VERSION ""

NS_ :

BS_:

BU_: AMP ETC GW ICM IVI NVS PDC TBOX VSP WCM

BO_ 801 VCU_alertMatrix0: 8 GW
 SG_ vcu_w000_accelPedalMismatch : 0|1@1+ (1,0) [0|1] ""  TBOX
 SG_ vcu_f000_accelPedalMismatch : 1|1@1+ (1,0) [0|1] ""  TBOX
 SG_ vcu_w001_ptOverTemp : 2|1@1+ (1,0) [0|1] ""  TBOX
 SG_ vcu_f001_ptOverTemp : 3|1@1+ (1,0) [0|1] ""  TBOX
 SG_ vcu_w002_vacuumSensorError : 4|1@1+ (1,0) [0|1] ""  TBOX
 SG_ vcu_f002_vacuumSensorError : 5|1@1+ (1,0) [0|1] ""  TBOX
 SG_ vcu_w003_accelPedalOutRange : 6|1@1+ (1,0) [0|1] ""  TBOX
 SG_ vcu_f003_accelPedalOutRange : 7|1@1+ (1,0) [0|1] ""  TBOX
 SG_ vcu_w004_waterPumpError : 8|1@1+ (1,0) [0|1] ""  TBOX
 SG_ vcu_f004_waterPumpError : 9|1@1+ (1,0) [0|1] ""  TBOX
 SG_ vcu_w009_limpMode : 18|1@1+ (1,0) [0|1] ""  TBOX
 SG_ vcu_f009_limpMode : 19|1@1+ (1,0) [0|1] ""  IVI,TBOX
 SG_ vcu_w010_gpoMode : 20|1@1+ (1,0) [0|1] ""  TBOX
 SG_ vcu_f010_gpoMode : 21|1@1+ (1,0) [0|1] ""  TBOX
 SG_ vcu_w011_hardFault : 22|1@1+ (1,0) [0|1] ""  TBOX
 SG_ vcu_f011_hardFault : 23|1@1+ (1,0) [0|1] ""  TBOX
 SG_ vcu_w012_bmsMia : 24|1@1+ (1,0) [0|1] ""  TBOX
 SG_ vcu_f012_bmsMia : 25|1@1+ (1,0) [0|1] ""  TBOX
 SG_ vcu_w013_mcuf0Mia : 26|1@1+ (1,0) [0|1] ""  TBOX
 SG_ vcu_f013_mcuf0Mia : 27|1@1+ (1,0) [0|1] ""  TBOX
 SG_ vcu_w014_mcur0Mia : 28|1@1+ (1,0) [0|1] ""  TBOX
 SG_ vcu_f014_mcur0Mia : 29|1@1+ (1,0) [0|1] ""  TBOX
 SG_ vcu_w015_mcuf1Mia : 30|1@1+ (1,0) [0|1] ""  TBOX
 SG_ vcu_f015_mcuf1Mia : 31|1@1+ (1,0) [0|1] ""  TBOX
 SG_ vcu_w016_mcur1Mia : 32|1@1+ (1,0) [0|1] ""  TBOX
 SG_ vcu_f016_mcur1Mia : 33|1@1+ (1,0) [0|1] ""  TBOX
 SG_ vcu_w017_gcuMia : 34|1@1+ (1,0) [0|1] ""  TBOX
 SG_ vcu_f017_gcuMia : 35|1@1+ (1,0) [0|1] ""  TBOX
 SG_ vcu_w018_escMia : 36|1@1+ (1,0) [0|1] ""  TBOX
 SG_ vcu_f018_escMia : 37|1@1+ (1,0) [0|1] ""  TBOX
 SG_ vcu_w019_dcdcOverTemp : 38|1@1+ (1,0) [0|1] ""  IVI,TBOX
 SG_ vcu_f019_dcdcOverTemp : 39|1@1+ (1,0) [0|1] ""  TBOX
 SG_ vcu_w020_obcOverTemp : 40|1@1+ (1,0) [0|1] ""  TBOX
 SG_ vcu_f020_obcOverTemp : 41|1@1+ (1,0) [0|1] ""  TBOX
 SG_ vcu_w021_lostCommCoolantLevel : 42|1@1+ (1,0) [0|1] ""  TBOX
 SG_ vcu_f021_lostCommCoolantLevel : 43|1@1+ (1,0) [0|1] ""  TBOX
 SG_ vcu_w022_threeWayValveFault : 44|1@1+ (1,0) [0|1] ""  TBOX
 SG_ vcu_f022_threeWayValveFault : 45|1@1+ (1,0) [0|1] ""  TBOX
 SG_ vcu_w023_fourWayValveFault : 46|1@1+ (1,0) [0|1] ""  TBOX
 SG_ vcu_f023_fourWayValveFault : 47|1@1+ (1,0) [0|1] ""  TBOX
 SG_ vcu_w024_battPtcFault : 48|1@1+ (1,0) [0|1] ""  TBOX
 SG_ vcu_f024_battPtcFault : 49|1@1+ (1,0) [0|1] ""  TBOX
 SG_ vcu_w025_acCompressorFault : 50|1@1+ (1,0) [0|1] ""  TBOX
 SG_ vcu_f025_acCompressorFault : 51|1@1+ (1,0) [0|1] ""  TBOX
 SG_ vcu_w026_agsFault : 52|1@1+ (1,0) [0|1] ""  TBOX
 SG_ vcu_f026_agsFault : 53|1@1+ (1,0) [0|1] ""  TBOX
 SG_ vcu_w027_battExvFault : 54|1@1+ (1,0) [0|1] ""  TBOX
 SG_ vcu_f027_battExvFault : 55|1@1+ (1,0) [0|1] ""  TBOX
 SG_ vcu_w028_acExvFault : 56|1@1+ (1,0) [0|1] ""  TBOX
 SG_ vcu_f028_acExvFault : 57|1@1+ (1,0) [0|1] ""  TBOX
 SG_ vcu_w029_coolantLevelLow : 58|1@1+ (1,0) [0|1] ""  TBOX
 SG_ vcu_f029_coolantLevelLow : 59|1@1+ (1,0) [0|1] ""  TBOX

BO_ 802 MCUR0_alertMatrix0: 8 GW
 SG_ mcur0_w000_overVoltage : 0|1@1+ (1,0) [0|1] ""  TBOX
 SG_ mcur0_f000_overVoltage : 1|1@1+ (1,0) [0|1] ""  TBOX
 SG_ mcur0_w001_overSpeed : 2|1@1+ (1,0) [0|1] ""  TBOX
 SG_ mcur0_f001_overSpeed : 3|1@1+ (1,0) [0|1] ""  TBOX
 SG_ mcur0_w002_overCurrentPhA : 4|1@1+ (1,0) [0|1] ""  TBOX
 SG_ mcur0_f002_overCurrentPhA : 5|1@1+ (1,0) [0|1] ""  TBOX
 SG_ mcur0_w003_overCurrentPhB : 6|1@1+ (1,0) [0|1] ""  TBOX
 SG_ mcur0_f003_overCurrentPhB : 7|1@1+ (1,0) [0|1] ""  TBOX
 SG_ mcur0_w004_overCurrentPhC : 8|1@1+ (1,0) [0|1] ""  TBOX
 SG_ mcur0_f004_overCurrentPhC : 9|1@1+ (1,0) [0|1] ""  TBOX
 SG_ mcur0_w005_canError : 10|1@1+ (1,0) [0|1] ""  TBOX
 SG_ mcur0_f005_canError : 11|1@1+ (1,0) [0|1] ""  TBOX
 SG_ mcur0_w006_noCurrentPhA : 12|1@1+ (1,0) [0|1] ""  TBOX
 SG_ mcur0_f006_noCurrentPhA : 13|1@1+ (1,0) [0|1] ""  TBOX
 SG_ mcur0_w007_noCurrentPhB : 14|1@1+ (1,0) [0|1] ""  TBOX
 SG_ mcur0_f007_noCurrentPhB : 15|1@1+ (1,0) [0|1] ""  TBOX
 SG_ mcur0_w008_noCurrentPhC : 16|1@1+ (1,0) [0|1] ""  TBOX
 SG_ mcur0_f008_noCurrentPhC : 17|1@1+ (1,0) [0|1] ""  TBOX
 SG_ mcur0_w009_taskOverrun100Hz : 18|1@1+ (1,0) [0|1] ""  TBOX
 SG_ mcur0_f009_taskOverrun100Hz : 19|1@1+ (1,0) [0|1] ""  TBOX
 SG_ mcur0_w010_taskOverrun10Hz : 20|1@1+ (1,0) [0|1] ""  TBOX
 SG_ mcur0_f010_taskOverrun10Hz : 21|1@1+ (1,0) [0|1] ""  TBOX
 SG_ mcur0_w011_PhATopDsatFaltSta : 22|1@1+ (1,0) [0|1] ""  TBOX
 SG_ mcur0_f011_PhATopDsatFaltSta : 23|1@1+ (1,0) [0|1] ""  TBOX
 SG_ mcur0_w012_PhBTopDsatFaltSta : 24|1@1+ (1,0) [0|1] ""  TBOX
 SG_ mcur0_f012_PhBTopDsatFaltSta : 25|1@1+ (1,0) [0|1] ""  TBOX
 SG_ mcur0_w013_PhCTopDsatFaltSta : 26|1@1+ (1,0) [0|1] ""  TBOX
 SG_ mcur0_f013_PhCTopDsatFaltSta : 27|1@1+ (1,0) [0|1] ""  TBOX
 SG_ mcur0_w014_PhABotDsatFaltSta : 28|1@1+ (1,0) [0|1] ""  TBOX
 SG_ mcur0_f014_PhABotDsatFaltSta : 29|1@1+ (1,0) [0|1] ""  TBOX
 SG_ mcur0_w015_PhBBotDsatFaltSta : 30|1@1+ (1,0) [0|1] ""  TBOX
 SG_ mcur0_f015_PhBBotDsatFaltSta : 31|1@1+ (1,0) [0|1] ""  TBOX
 SG_ mcur0_w016_PhCBotDsatFaltSta : 32|1@1+ (1,0) [0|1] ""  TBOX
 SG_ mcur0_f016_PhCBotDsatFaltSta : 33|1@1+ (1,0) [0|1] ""  TBOX
 SG_ mcur0_w017_underVoltage : 34|1@1+ (1,0) [0|1] ""  TBOX
 SG_ mcur0_f017_underVoltage : 35|1@1+ (1,0) [0|1] ""  TBOX
 SG_ mcur0_w018_overTemperature : 36|1@1+ (1,0) [0|1] ""  IVI,TBOX
 SG_ mcur0_f018_overTemperature : 37|1@1+ (1,0) [0|1] ""  IVI,TBOX
 SG_ mcur0_w019_underTemperature : 38|1@1+ (1,0) [0|1] ""  IVI,TBOX
 SG_ mcur0_f019_underTemperature : 39|1@1+ (1,0) [0|1] ""  TBOX
 SG_ mcur0_w020_controllerOverTemp : 40|1@1+ (1,0) [0|1] ""  IVI,TBOX
 SG_ mcur0_f020_controllerOverTemp : 41|1@1+ (1,0) [0|1] ""  TBOX
 SG_ mcur0_w021_adcOverRun : 42|1@1+ (1,0) [0|1] ""  TBOX
 SG_ mcur0_f021_adcOverRun : 43|1@1+ (1,0) [0|1] ""  TBOX
 SG_ mcur0_w022_HwOverCurrentPh : 44|1@1+ (1,0) [0|1] ""  TBOX
 SG_ mcur0_f022_HwOverCurrentPh : 45|1@1+ (1,0) [0|1] ""  TBOX
 SG_ mcur0_w023_HwOverCurrentPh : 46|1@1+ (1,0) [0|1] ""  TBOX
 SG_ mcur0_f023_HwOverCurrentPh : 47|1@1+ (1,0) [0|1] ""  TBOX
 SG_ mcur0_w024_HwOverCurrentPh : 48|1@1+ (1,0) [0|1] ""  TBOX
 SG_ mcur0_f024_HwOverCurrentPh : 49|1@1+ (1,0) [0|1] ""  TBOX
 SG_ mcur0_w025_hardwareOverVoltage : 50|1@1+ (1,0) [0|1] ""  TBOX
 SG_ mcur0_f025_hardwareOverVoltage : 51|1@1+ (1,0) [0|1] ""  TBOX
 SG_ mcur0_w026_hardwareDsatFault : 52|1@1+ (1,0) [0|1] ""  TBOX
 SG_ mcur0_f026_hardwareDsatFault : 53|1@1+ (1,0) [0|1] ""  TBOX
 SG_ mcur0_w027_curSenOffsetOutOfR : 54|1@1+ (1,0) [0|1] ""  TBOX
 SG_ mcur0_f027_curSenOffsetOutOfR : 55|1@1+ (1,0) [0|1] ""  TBOX

BO_ 803 MCUF0_alertMatrix0: 8 GW
 SG_ mcuf0_w000_overVoltage : 0|1@1+ (1,0) [0|1] ""  TBOX
 SG_ mcuf0_f000_overVoltage : 1|1@1+ (1,0) [0|1] ""  TBOX
 SG_ mcuf0_w001_overSpeed : 2|1@1+ (1,0) [0|1] ""  TBOX
 SG_ mcuf0_f001_overSpeed : 3|1@1+ (1,0) [0|1] ""  TBOX
 SG_ mcuf0_w002_overCurrentPhA : 4|1@1+ (1,0) [0|1] ""  TBOX
 SG_ mcuf0_f002_overCurrentPhA : 5|1@1+ (1,0) [0|1] ""  TBOX
 SG_ mcuf0_w003_overCurrentPhB : 6|1@1+ (1,0) [0|1] ""  TBOX
 SG_ mcuf0_f003_overCurrentPhB : 7|1@1+ (1,0) [0|1] ""  TBOX
 SG_ mcuf0_w004_overCurrentPhC : 8|1@1+ (1,0) [0|1] ""  TBOX
 SG_ mcuf0_f004_overCurrentPhC : 9|1@1+ (1,0) [0|1] ""  TBOX
 SG_ mcuf0_w005_canError : 10|1@1+ (1,0) [0|1] ""  TBOX
 SG_ mcuf0_f005_canError : 11|1@1+ (1,0) [0|1] ""  TBOX
 SG_ mcuf0_w006_noCurrentPhA : 12|1@1+ (1,0) [0|1] ""  TBOX
 SG_ mcuf0_f006_noCurrentPhA : 13|1@1+ (1,0) [0|1] ""  TBOX
 SG_ mcuf0_w007_noCurrentPhB : 14|1@1+ (1,0) [0|1] ""  TBOX
 SG_ mcuf0_f007_noCurrentPhB : 15|1@1+ (1,0) [0|1] ""  TBOX
 SG_ mcuf0_w008_noCurrentPhC : 16|1@1+ (1,0) [0|1] ""  TBOX
 SG_ mcuf0_f008_noCurrentPhC : 17|1@1+ (1,0) [0|1] ""  TBOX
 SG_ mcuf0_w009_taskOverrun100Hz : 18|1@1+ (1,0) [0|1] ""  TBOX
 SG_ mcuf0_f009_taskOverrun100Hz : 19|1@1+ (1,0) [0|1] ""  TBOX
 SG_ mcuf0_w010_taskOverrun10Hz : 20|1@1+ (1,0) [0|1] ""  TBOX
 SG_ mcuf0_f010_taskOverrun10Hz : 21|1@1+ (1,0) [0|1] ""  TBOX
 SG_ mcuf0_w011_PhATopDsatFaltSts : 22|1@1+ (1,0) [0|1] ""  TBOX
 SG_ mcuf0_f011_PhATopDsatFaltSts : 23|1@1+ (1,0) [0|1] ""  TBOX
 SG_ mcuf0_w012_PhBTopDsatFaltSts : 24|1@1+ (1,0) [0|1] ""  TBOX
 SG_ mcuf0_f012_PhBTopDsatFaltSts : 25|1@1+ (1,0) [0|1] ""  TBOX
 SG_ mcuf0_w013_PhCTopDsatFaltSts : 26|1@1+ (1,0) [0|1] ""  TBOX
 SG_ mcuf0_f013_PhCTopDsatFaltSts : 27|1@1+ (1,0) [0|1] ""  TBOX
 SG_ mcuf0_w014_PhABotDsatFaltSts : 28|1@1+ (1,0) [0|1] ""  TBOX
 SG_ mcuf0_f014_PhABotDsatFaltSts : 29|1@1+ (1,0) [0|1] ""  TBOX
 SG_ mcuf0_w015_PhBBotDsatFaltSts : 30|1@1+ (1,0) [0|1] ""  TBOX
 SG_ mcuf0_f015_PhBBotDsatFaltSts : 31|1@1+ (1,0) [0|1] ""  TBOX
 SG_ mcuf0_w016_PhCBotDsatFaltSts : 32|1@1+ (1,0) [0|1] ""  TBOX
 SG_ mcuf0_f016_PhCBotDsatFaltSts : 33|1@1+ (1,0) [0|1] ""  TBOX
 SG_ mcuf0_w017_underVoltage : 34|1@1+ (1,0) [0|1] ""  TBOX
 SG_ mcuf0_f017_underVoltage : 35|1@1+ (1,0) [0|1] ""  TBOX
 SG_ mcuf0_w018_overTemperature : 36|1@1+ (1,0) [0|1] ""  IVI,TBOX
 SG_ mcuf0_f018_overTemperature : 37|1@1+ (1,0) [0|1] ""  IVI,TBOX
 SG_ mcuf0_w019_underTemperature : 38|1@1+ (1,0) [0|1] ""  IVI,TBOX
 SG_ mcuf0_f019_underTemperature : 39|1@1+ (1,0) [0|1] ""  TBOX
 SG_ mcuf0_w020_controllerOverTemp : 40|1@1+ (1,0) [0|1] ""  IVI,TBOX
 SG_ mcuf0_f020_controllerOverTemp : 41|1@1+ (1,0) [0|1] ""  TBOX
 SG_ mcuf0_w021_adcOverRun : 42|1@1+ (1,0) [0|1] ""  TBOX
 SG_ mcuf0_f021_adcOverRun : 43|1@1+ (1,0) [0|1] ""  TBOX
 SG_ mcuf0_w022_hdOverCurrentPhA : 44|1@1+ (1,0) [0|1] ""  TBOX
 SG_ mcuf0_f022_hdOverCurrentPhA : 45|1@1+ (1,0) [0|1] ""  TBOX
 SG_ mcuf0_w023_hdOverCurrentPhB : 46|1@1+ (1,0) [0|1] ""  TBOX
 SG_ mcuf0_f023_hdOverCurrentPhB : 47|1@1+ (1,0) [0|1] ""  TBOX
 SG_ mcuf0_w024_hdOverCurrentPhC : 48|1@1+ (1,0) [0|1] ""  TBOX
 SG_ mcuf0_f024_hdOverCurrentPhC : 49|1@1+ (1,0) [0|1] ""  TBOX
 SG_ mcuf0_w025_hardwareOverVoltage : 50|1@1+ (1,0) [0|1] ""  TBOX
 SG_ mcuf0_f025_hardwareOverVoltage : 51|1@1+ (1,0) [0|1] ""  TBOX
 SG_ mcuf0_w026_hardwareDsatFault : 52|1@1+ (1,0) [0|1] ""  TBOX
 SG_ mcuf0_f026_hardwareDsatFault : 53|1@1+ (1,0) [0|1] ""  TBOX
 SG_ mcuf0_w027_curSenOffsetOutOfR : 54|1@1+ (1,0) [0|1] ""  TBOX
 SG_ mcuf0_f027_curSenOffsetOutOfR : 55|1@1+ (1,0) [0|1] ""  TBOX

BO_ 804 BMS_alertMatrix0: 8 GW
 SG_ bms_w000_packUnderVoltage : 0|1@1+ (1,0) [0|1] ""  TBOX
 SG_ bms_f000_packUnderVoltage : 1|1@1+ (1,0) [0|1] ""  TBOX
 SG_ bms_w001_packOverVoltage : 2|1@1+ (1,0) [0|1] ""  TBOX
 SG_ bms_f001_packOverVoltage : 3|1@1+ (1,0) [0|1] ""  TBOX
 SG_ bms_w002_packOverCrntDischg : 4|1@1+ (1,0) [0|1] ""  TBOX
 SG_ bms_f002_packOverCrntDischg : 5|1@1+ (1,0) [0|1] ""  TBOX
 SG_ bms_w003_packOverCrntChg : 6|1@1+ (1,0) [0|1] ""  TBOX
 SG_ bms_f003_packOverCrntChg : 7|1@1+ (1,0) [0|1] ""  TBOX
 SG_ bms_w004_cellUnderVoltage : 8|1@1+ (1,0) [0|1] ""  TBOX
 SG_ bms_f004_cellUnderVoltage : 9|1@1+ (1,0) [0|1] ""  TBOX
 SG_ bms_w005_cellOverVoltage : 10|1@1+ (1,0) [0|1] ""  TBOX
 SG_ bms_f005_cellOverVoltage : 11|1@1+ (1,0) [0|1] ""  TBOX
 SG_ bms_w006_cellUnderTemp : 12|1@1+ (1,0) [0|1] ""  IVI,TBOX
 SG_ bms_f006_cellUnderTemp : 13|1@1+ (1,0) [0|1] ""  TBOX
 SG_ bms_w007_cellOverTemp : 14|1@1+ (1,0) [0|1] ""  IVI,TBOX
 SG_ bms_f007_cellOverTemp : 15|1@1+ (1,0) [0|1] ""  TBOX
 SG_ bms_w008_contactorPosMainHSFlt : 16|1@1+ (1,0) [0|1] ""  TBOX
 SG_ bms_f008_contactorPosMainHSFlt : 17|1@1+ (1,0) [0|1] ""  TBOX
 SG_ bms_w009_contactorPosMainLSFlt : 18|1@1+ (1,0) [0|1] ""  TBOX
 SG_ bms_f009_contactorPosMainLSFlt : 19|1@1+ (1,0) [0|1] ""  TBOX
 SG_ bms_w010_contactorNegMainHSFlt : 20|1@1+ (1,0) [0|1] ""  TBOX
 SG_ bms_f010_contactorNegMainHSFlt : 21|1@1+ (1,0) [0|1] ""  TBOX
 SG_ bms_w011_contactorNegMainLSFlt : 22|1@1+ (1,0) [0|1] ""  TBOX
 SG_ bms_f011_contactorNegMainLSFlt : 23|1@1+ (1,0) [0|1] ""  TBOX
 SG_ bms_w012_contactorPrechgHSFault : 24|1@1+ (1,0) [0|1] ""  TBOX
 SG_ bms_f012_contactorPrechgHSFault : 25|1@1+ (1,0) [0|1] ""  TBOX
 SG_ bms_w013_contactorPrechgLSFault : 26|1@1+ (1,0) [0|1] ""  TBOX
 SG_ bms_f013_contactorPrechgLSFault : 27|1@1+ (1,0) [0|1] ""  TBOX
 SG_ bms_w014_acChargingRelayFault : 28|1@1+ (1,0) [0|1] ""  TBOX
 SG_ bms_f014_acChargingRelayFault : 29|1@1+ (1,0) [0|1] ""  TBOX
 SG_ bms_w015_dcChargingRelayFault : 30|1@1+ (1,0) [0|1] ""  TBOX
 SG_ bms_f015_dcChargingRelayFault : 31|1@1+ (1,0) [0|1] ""  TBOX
 SG_ bms_w016_currentSensorFailure : 32|1@1+ (1,0) [0|1] ""  TBOX
 SG_ bms_f016_currentSensorFailure : 33|1@1+ (1,0) [0|1] ""  TBOX
 SG_ bms_w017_cellImbalanceDischrg : 34|1@1+ (1,0) [0|1] ""  TBOX
 SG_ bms_f017_cellImbalanceDischrg : 35|1@1+ (1,0) [0|1] ""  TBOX
 SG_ bms_w018_prechargeFailure : 36|1@1+ (1,0) [0|1] ""  TBOX
 SG_ bms_f018_prechargeFailure : 37|1@1+ (1,0) [0|1] ""  TBOX
 SG_ bms_w019_bmuCommFailure : 38|1@1+ (1,0) [0|1] ""  TBOX
 SG_ bms_f019_bmuCommFailure : 39|1@1+ (1,0) [0|1] ""  TBOX
 SG_ bms_w020_isolationFault : 40|1@1+ (1,0) [0|1] ""  TBOX
 SG_ bms_f020_isolationFault : 41|1@1+ (1,0) [0|1] ""  IVI,TBOX
 SG_ bms_w021_coolantInletOverTemp : 42|1@1+ (1,0) [0|1] ""  TBOX
 SG_ bms_f021_coolantInletOverTemp : 43|1@1+ (1,0) [0|1] ""  TBOX
 SG_ bms_w022_coolantOutletOverTemp : 44|1@1+ (1,0) [0|1] ""  TBOX
 SG_ bms_f022_coolantOutletOverTemp : 45|1@1+ (1,0) [0|1] ""  TBOX
 SG_ bms_w023_prechargeTimeout : 46|1@1+ (1,0) [0|1] ""  TBOX
 SG_ bms_f023_prechargeTimeout : 47|1@1+ (1,0) [0|1] ""  TBOX
 SG_ bms_w024_powerDeratingSoc : 48|1@1+ (1,0) [0|1] ""  TBOX
 SG_ bms_f024_powerDeratingSoc : 49|1@1+ (1,0) [0|1] ""  TBOX
 SG_ bms_w025_noPowerDeliverySoc : 50|1@1+ (1,0) [0|1] ""  TBOX
 SG_ bms_f025_noPowerDeliverySoc : 51|1@1+ (1,0) [0|1] ""  TBOX
 SG_ bms_w026_dcLSContactorFail : 52|1@1+ (1,0) [0|1] ""  TBOX
 SG_ bms_f026_dcLSContactorFail : 53|1@1+ (1,0) [0|1] ""  TBOX
 SG_ bms_w027_hvilOpen : 54|1@1+ (1,0) [0|1] ""  TBOX
 SG_ bms_f027_hvilOpen : 55|1@1+ (1,0) [0|1] ""  TBOX
 SG_ bms_w028_lostCommsVCU : 56|1@1+ (1,0) [0|1] ""  TBOX
 SG_ bms_f028_lostCommsVCU : 57|1@1+ (1,0) [0|1] ""  TBOX
 SG_ bms_w029_lostCommsOBC : 58|1@1+ (1,0) [0|1] ""  TBOX
 SG_ bms_f029_lostCommsOBC : 59|1@1+ (1,0) [0|1] ""  TBOX
 SG_ bms_w030_batteryProtectionSoc : 60|1@1+ (1,0) [0|1] ""  TBOX
 SG_ bms_f030_batteryProtectionSoc : 61|1@1+ (1,0) [0|1] ""  TBOX
 SG_ bms_w031_cellTempImbalDischrg : 62|1@1+ (1,0) [0|1] ""  TBOX
 SG_ bms_f031_cellTempImbalDischrg : 63|1@1+ (1,0) [0|1] ""  TBOX

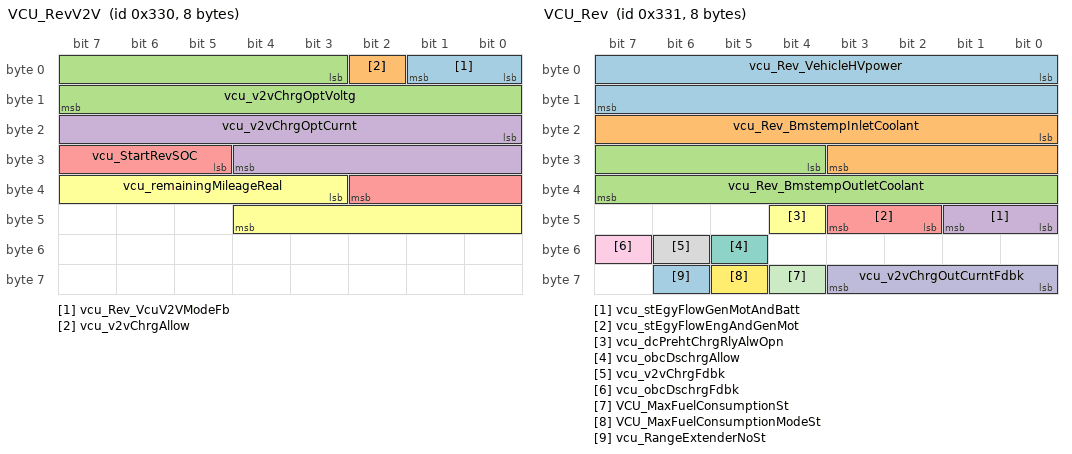
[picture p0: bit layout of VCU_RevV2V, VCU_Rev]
BO_ 816 VCU_RevV2V: 8 GW
 SG_ vcu_Rev_VcuV2VModeFb : 0|2@1+ (1,0) [0|3] "" Vector__XXX
 SG_ vcu_v2vChrgAllow : 2|1@1+ (1,0) [0|1] ""  IVI
 SG_ vcu_v2vChrgOptVoltg : 3|13@1+ (0.1,0) [0|800] "V"  IVI
 SG_ vcu_v2vChrgOptCurnt : 16|13@1+ (0.1,-400) [-400|400] "A"  IVI
 SG_ vcu_StartRevSOC : 29|6@1+ (1,20) [20|80] "%"  IVI
 SG_ vcu_remainingMileageReal : 35|10@1+ (1,0) [0|1023] "km"  IVI,TBOX

BO_ 817 VCU_Rev: 8 GW
 SG_ vcu_Rev_VehicleHVpower : 0|16@1+ (1,0) [0|20000] "W" Vector__XXX
 SG_ vcu_Rev_BmstempInletCoolant : 16|12@1+ (0.5,-40) [-40|125] "℃" Vector__XXX
 SG_ vcu_Rev_BmstempOutletCoolant : 28|12@1+ (0.5,-40) [-40|125] "℃" Vector__XXX
 SG_ vcu_stEgyFlowGenMotAndBatt : 40|2@1+ (1,0) [0|2] ""  IVI
 SG_ vcu_stEgyFlowEngAndGenMot : 42|2@1+ (1,0) [0|2] ""  IVI
 SG_ vcu_dcPrehtChrgRlyAlwOpn : 44|1@1+ (1,0) [0|1] "" Vector__XXX
 SG_ vcu_obcDschrgAllow : 53|1@1+ (1,0) [0|1] ""  IVI
 SG_ vcu_v2vChrgFdbk : 54|1@1+ (1,0) [0|1] ""  IVI
 SG_ vcu_obcDschrgFdbk : 55|1@1+ (1,0) [0|1] ""  IVI
 SG_ vcu_v2vChrgOutCurntFdbk : 56|4@1+ (1,0) [0|15] "A"  IVI
 SG_ VCU_MaxFuelConsumptionSt : 60|1@1+ (1,0) [0|1] ""  IVI
 SG_ VCU_MaxFuelConsumptionModeSt : 61|1@1+ (1,0) [0|1] ""  IVI
 SG_ vcu_RangeExtenderNoSt : 62|1@1+ (1,0) [0|1] ""  IVI

BO_ 820 BMS_alertMatrix1: 8 GW
 SG_ bms_w032_highSOC : 0|1@1+ (1,0) [0|1] ""  TBOX
 SG_ bms_f032_highSOC : 1|1@1+ (1,0) [0|1] ""  TBOX
 SG_ bms_w033_lostCommsIVTS : 2|1@1+ (1,0) [0|1] ""  TBOX
 SG_ bms_f033_lostCommsIVTS : 3|1@1+ (1,0) [0|1] ""  TBOX
 SG_ bms_w034_socStepChange : 4|1@1+ (1,0) [0|1] ""  TBOX
 SG_ bms_f034_socStepChange : 5|1@1+ (1,0) [0|1] ""  TBOX
 SG_ bms_w035_bmuNoResponse : 6|1@1+ (1,0) [0|1] ""  TBOX
 SG_ bms_f035_bmuNoResponse : 7|1@1+ (1,0) [0|1] ""  TBOX
 SG_ bms_w036_bmuHarnessBroken : 8|1@1+ (1,0) [0|1] ""  TBOX
 SG_ bms_f036_bmuHarnessBroken : 9|1@1+ (1,0) [0|1] ""  TBOX
 SG_ bms_w037_cellVoltImbalanceChrg : 10|1@1+ (1,0) [0|1] ""  TBOX
 SG_ bms_f037_cellVoltImbalanceChrg : 11|1@1+ (1,0) [0|1] ""  TBOX
 SG_ bms_w038_cellTempImbalanceChrg : 12|1@1+ (1,0) [0|1] ""  TBOX
 SG_ bms_f038_cellTempImbalanceChrg : 13|1@1+ (1,0) [0|1] ""  TBOX
 SG_ bms_w039_cellVoltSnrDisconnect : 14|1@1+ (1,0) [0|1] ""  TBOX
 SG_ bms_f039_cellVoltSnrDisconnect : 15|1@1+ (1,0) [0|1] ""  TBOX
 SG_ bms_w040_cellThermistorDiscon : 16|1@1+ (1,0) [0|1] ""  TBOX
 SG_ bms_f040_cellThermistorDiscon : 17|1@1+ (1,0) [0|1] ""  TBOX
 SG_ bms_w041_posMainConStuckOpen : 18|1@1+ (1,0) [0|1] ""  TBOX
 SG_ bms_f041_posMainConStuckOpen : 19|1@1+ (1,0) [0|1] ""  TBOX
 SG_ bms_w042_posMainContactorWelded : 20|1@1+ (1,0) [0|1] ""  TBOX
 SG_ bms_f042_posMainContactorWelded : 21|1@1+ (1,0) [0|1] ""  TBOX
 SG_ bms_w043_negMainConStuckOpen : 22|1@1+ (1,0) [0|1] ""  TBOX
 SG_ bms_f043_negMainConStuckOpen : 23|1@1+ (1,0) [0|1] ""  TBOX
 SG_ bms_w044_negMainContactorWelded : 24|1@1+ (1,0) [0|1] ""  TBOX
 SG_ bms_f044_negMainContactorWelded : 25|1@1+ (1,0) [0|1] ""  TBOX
 SG_ bms_w045_prechrgConStuckOpen : 26|1@1+ (1,0) [0|1] ""  TBOX
 SG_ bms_f045_prechrgConStuckOpen : 27|1@1+ (1,0) [0|1] ""  TBOX
 SG_ bms_w046_prechrgContactorWelded : 28|1@1+ (1,0) [0|1] ""  TBOX
 SG_ bms_f046_prechrgContactorWelded : 29|1@1+ (1,0) [0|1] ""  TBOX
 SG_ bms_w047_packOverTemp : 30|1@1+ (1,0) [0|1] ""  TBOX
 SG_ bms_f047_packOverTemp : 31|1@1+ (1,0) [0|1] ""  TBOX
 SG_ bms_w048_packUnderTemp : 32|1@1+ (1,0) [0|1] ""  TBOX
 SG_ bms_f048_packUnderTemp : 33|1@1+ (1,0) [0|1] ""  TBOX
 SG_ bms_w049_coolantInletSnrDiscon : 34|1@1+ (1,0) [0|1] ""  TBOX
 SG_ bms_f049_coolantInletSnrDiscon : 35|1@1+ (1,0) [0|1] ""  TBOX
 SG_ bms_w050_coolantOutletSnrDiscon : 36|1@1+ (1,0) [0|1] ""  TBOX
 SG_ bms_f050_coolantOutletSnrDiscon : 37|1@1+ (1,0) [0|1] ""  TBOX
 SG_ bms_w051_obcOverTemp : 38|1@1+ (1,0) [0|1] ""  IVI,TBOX
 SG_ bms_f051_obcOverTemp : 39|1@1+ (1,0) [0|1] ""  IVI,TBOX
 SG_ bms_w052_battPackShortCircuit : 40|1@1+ (1,0) [0|1] ""  TBOX
 SG_ bms_f052_battPackShortCircuit : 41|1@1+ (1,0) [0|1] ""  TBOX
 SG_ bms_w053_acChrgPortOverTemp : 42|1@1+ (1,0) [0|1] ""  TBOX
 SG_ bms_f053_acChrgPortOverTemp : 43|1@1+ (1,0) [0|1] ""  TBOX
 SG_ bms_w054_dcChrgPortOverTemp : 44|1@1+ (1,0) [0|1] ""  TBOX
 SG_ bms_f054_dcChrgPortOverTemp : 45|1@1+ (1,0) [0|1] ""  TBOX
 SG_ bms_w055_dcChrgPortTempRise : 46|1@1+ (1,0) [0|1] ""  TBOX
 SG_ bms_f055_dcChrgPortTempRise : 47|1@1+ (1,0) [0|1] ""  TBOX
 SG_ bms_w056_ivtsOverTemp : 48|1@1+ (1,0) [0|1] "" Vector__XXX
 SG_ bms_f056_ivtsOverTemp : 49|1@1+ (1,0) [0|1] "" Vector__XXX
 SG_ bms_w059_vcuStateMsgMia : 54|1@1+ (1,0) [0|1] ""  TBOX
 SG_ bms_f059_vcuStateMsgMia : 55|1@1+ (1,0) [0|1] ""  TBOX
 SG_ bms_w060_ribbonBondBroken : 56|1@1+ (1,0) [0|1] "" Vector__XXX
 SG_ bms_f060_ribbonBondBroken : 57|1@1+ (1,0) [0|1] "" Vector__XXX
 SG_ bms_w061_crashDetected : 58|1@1+ (1,0) [0|1] "" Vector__XXX
 SG_ bms_f061_crashDetected : 59|1@1+ (1,0) [0|1] ""  TBOX
 SG_ bms_w062_vcuVehicleMsgMia : 60|1@1+ (1,0) [0|1] ""  TBOX
 SG_ bms_f062_vcuVehicleMsgMia : 61|1@1+ (1,0) [0|1] ""  TBOX
 SG_ bms_w063_systemFault : 62|1@1+ (1,0) [0|1] ""  TBOX
 SG_ bms_f063_systemFault : 63|1@1+ (1,0) [0|1] ""  TBOX

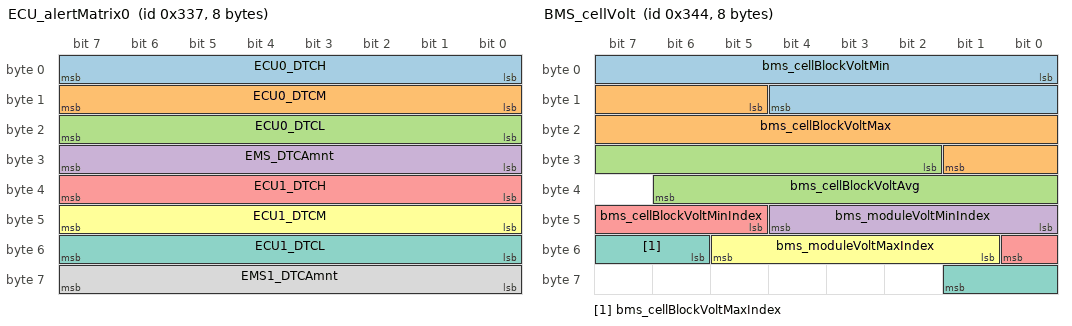
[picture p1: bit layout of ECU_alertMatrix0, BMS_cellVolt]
BO_ 823 ECU_alertMatrix0: 8 GW
 SG_ ECU0_DTCH : 0|8@1+ (1,0) [0|255] ""  TBOX
 SG_ ECU0_DTCM : 8|8@1+ (1,0) [0|255] ""  TBOX
 SG_ ECU0_DTCL : 16|8@1+ (1,0) [0|255] ""  TBOX
 SG_ EMS_DTCAmnt : 24|8@1+ (1,0) [0|255] ""  TBOX
 SG_ ECU1_DTCH : 32|8@1+ (1,0) [0|255] ""  TBOX
 SG_ ECU1_DTCM : 40|8@1+ (1,0) [0|255] ""  TBOX
 SG_ ECU1_DTCL : 48|8@1+ (1,0) [0|255] ""  TBOX
 SG_ EMS1_DTCAmnt : 56|8@1+ (1,0) [0|255] ""  TBOX

BO_ 836 BMS_cellVolt: 8 GW
 SG_ bms_cellBlockVoltMin : 0|13@1+ (0.001,0) [0|5] "V"  TBOX
 SG_ bms_cellBlockVoltMax : 13|13@1+ (0.001,0) [0|5] "V"  TBOX
 SG_ bms_cellBlockVoltAvg : 26|13@1+ (0.001,0) [0|5] "V"  TBOX
 SG_ bms_moduleVoltMinIndex : 40|5@1+ (1,0) [0|31] ""  TBOX
 SG_ bms_cellBlockVoltMinIndex : 45|4@1+ (1,0) [0|15] ""  TBOX
 SG_ bms_moduleVoltMaxIndex : 49|5@1+ (1,0) [0|31] ""  TBOX
 SG_ bms_cellBlockVoltMaxIndex : 54|4@1+ (1,0) [0|15] ""  TBOX

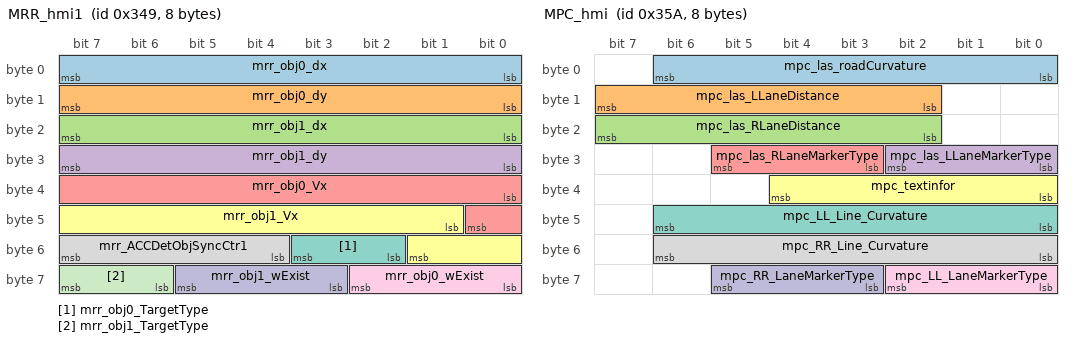
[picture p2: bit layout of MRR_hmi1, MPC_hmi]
BO_ 841 MRR_hmi1: 8 GW
 SG_ mrr_obj0_dx : 0|8@1+ (1,0) [0|250] "m"  IVI
 SG_ mrr_obj0_dy : 8|8@1+ (0.1,-12.8) [-12.8|12.7] "m"  IVI
 SG_ mrr_obj1_dx : 16|8@1+ (1,0) [0|250] "m"  IVI
 SG_ mrr_obj1_dy : 24|8@1+ (0.1,-12.8) [-12.8|12.7] "m"  IVI
 SG_ mrr_obj0_Vx : 32|9@1+ (0.1,0) [0|50] "m/s"  IVI
 SG_ mrr_obj1_Vx : 41|9@1+ (0.1,0) [0|50] "m/s"  IVI
 SG_ mrr_obj0_TargetType : 50|2@1+ (1,0) [0|3] ""  IVI
 SG_ mrr_ACCDetObjSyncCtr1 : 52|4@1+ (1,0) [0|15] ""  IVI
 SG_ mrr_obj0_wExist : 56|3@1+ (1,0) [0|7] ""  IVI
 SG_ mrr_obj1_wExist : 59|3@1+ (1,0) [0|7] ""  IVI
 SG_ mrr_obj1_TargetType : 62|2@1+ (1,0) [0|3] ""  IVI

BO_ 858 MPC_hmi: 8 GW
 SG_ mpc_las_roadCurvature : 0|7@1+ (0.0005,-0.03) [-0.03|0.03] "1/m"  IVI,TBOX
 SG_ mpc_las_LLaneDistance : 10|6@1+ (0.1,-1) [-1|5] "m"  IVI,TBOX
 SG_ mpc_las_RLaneDistance : 18|6@1+ (0.1,-5) [-5|1] "m"  IVI,TBOX
 SG_ mpc_las_LLaneMarkerType : 24|3@1+ (1,0) [0|7] ""  IVI,TBOX
 SG_ mpc_las_RLaneMarkerType : 27|3@1+ (1,0) [0|7] ""  IVI,TBOX
 SG_ mpc_textinfor : 32|5@1+ (1,0) [0|31] ""  IVI
 SG_ mpc_LL_Line_Curvature : 40|7@1+ (0.0005,-0.03) [-0.03|0.03] "1/m"  IVI,TBOX
 SG_ mpc_RR_Line_Curvature : 48|7@1+ (0.0005,-0.03) [-0.03|0.03] "1/m"  IVI,TBOX
 SG_ mpc_LL_LaneMarkerType : 56|3@1+ (1,0) [0|7] ""  IVI,TBOX
 SG_ mpc_RR_LaneMarkerType : 59|3@1+ (1,0) [0|7] ""  IVI,TBOX

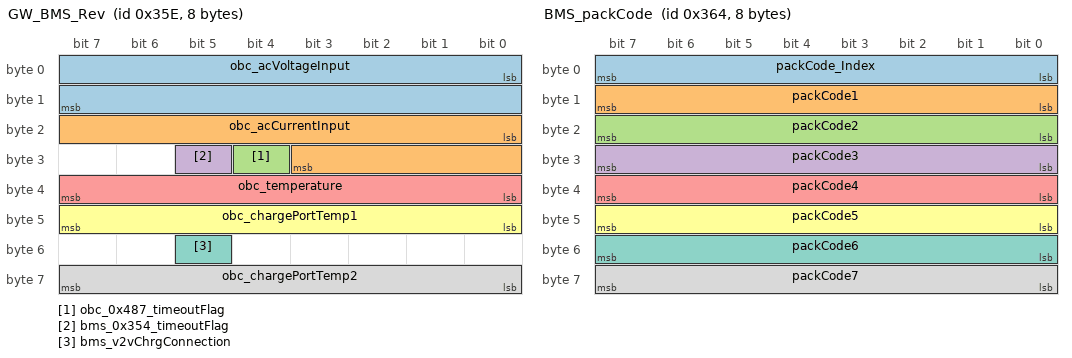
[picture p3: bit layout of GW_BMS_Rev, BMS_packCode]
BO_ 862 GW_BMS_Rev: 8 GW
 SG_ obc_acVoltageInput : 0|16@1+ (0.1,0) [0|6553.5] "V"  IVI
 SG_ obc_acCurrentInput : 16|12@1+ (0.1,0) [0|409.5] "A"  IVI
 SG_ obc_0x487_timeoutFlag : 28|1@1+ (1,0) [0|1] ""  IVI,TBOX
 SG_ bms_0x354_timeoutFlag : 29|1@1+ (1,0) [0|1] ""  IVI
 SG_ obc_temperature : 32|8@1+ (1,-40) [-40|200] "degC"  TBOX
 SG_ obc_chargePortTemp1 : 40|8@1+ (1,-40) [-40|205] "degC"  TBOX
 SG_ bms_v2vChrgConnection : 53|1@1+ (1,0) [0|1] ""  IVI
 SG_ obc_chargePortTemp2 : 56|8@1+ (1,-40) [-40|205] "degC"  TBOX

BO_ 868 BMS_packCode: 8 GW
 SG_ packCode_Index : 0|8@1+ (1,0) [0|4] ""  TBOX
 SG_ packCode1 : 8|8@1+ (1,0) [0|255] ""  TBOX
 SG_ packCode2 : 16|8@1+ (1,0) [0|255] ""  TBOX
 SG_ packCode3 : 24|8@1+ (1,0) [0|255] ""  TBOX
 SG_ packCode4 : 32|8@1+ (1,0) [0|255] ""  TBOX
 SG_ packCode5 : 40|8@1+ (1,0) [0|255] ""  TBOX
 SG_ packCode6 : 48|8@1+ (1,0) [0|255] ""  TBOX
 SG_ packCode7 : 56|8@1+ (1,0) [0|255] ""  TBOX

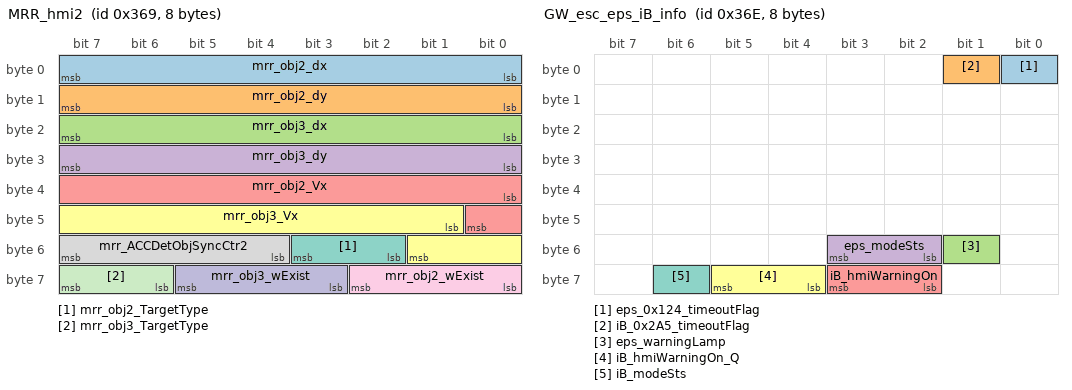
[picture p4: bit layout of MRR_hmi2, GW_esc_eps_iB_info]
BO_ 873 MRR_hmi2: 8 GW
 SG_ mrr_obj2_dx : 0|8@1+ (1,0) [0|250] "m"  IVI
 SG_ mrr_obj2_dy : 8|8@1+ (0.1,-12.8) [-12.8|12.7] "m"  IVI
 SG_ mrr_obj3_dx : 16|8@1+ (1,0) [0|250] "m"  IVI
 SG_ mrr_obj3_dy : 24|8@1+ (0.1,-12.8) [-12.8|12.7] "m"  IVI
 SG_ mrr_obj2_Vx : 32|9@1+ (0.1,0) [0|50] "m/s"  IVI
 SG_ mrr_obj3_Vx : 41|9@1+ (0.1,0) [0|50] "m/s"  IVI
 SG_ mrr_obj2_TargetType : 50|2@1+ (1,0) [0|3] ""  IVI
 SG_ mrr_ACCDetObjSyncCtr2 : 52|4@1+ (1,0) [0|15] ""  IVI
 SG_ mrr_obj2_wExist : 56|3@1+ (1,0) [0|7] ""  IVI
 SG_ mrr_obj3_wExist : 59|3@1+ (1,0) [0|7] ""  IVI
 SG_ mrr_obj3_TargetType : 62|2@1+ (1,0) [0|3] ""  IVI

BO_ 878 GW_esc_eps_iB_info: 8 GW
 SG_ eps_0x124_timeoutFlag : 0|1@1+ (1,0) [0|1] ""  IVI
 SG_ iB_0x2A5_timeoutFlag : 1|1@1+ (1,0) [0|1] ""  IVI
 SG_ eps_warningLamp : 49|1@1+ (1,0) [0|1] ""  IVI,TBOX
 SG_ eps_modeSts : 50|2@1+ (1,0) [0|3] ""  IVI
 SG_ iB_hmiWarningOn : 58|2@1+ (1,0) [0|3] ""  IVI,TBOX
 SG_ iB_hmiWarningOn_Q : 60|2@1+ (1,0) [0|3] ""  IVI,TBOX
 SG_ iB_modeSts : 62|1@1+ (1,0) [0|1] ""  IVI

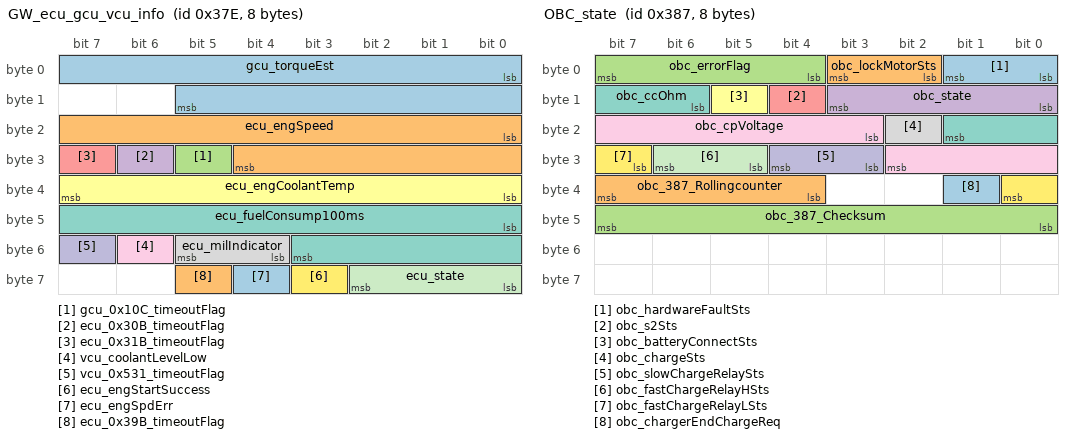
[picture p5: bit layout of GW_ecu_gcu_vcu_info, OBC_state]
BO_ 894 GW_ecu_gcu_vcu_info: 8 GW
 SG_ gcu_torqueEst : 0|14@1+ (0.1,-800) [-800|800] "Nm"  TBOX
 SG_ ecu_engSpeed : 16|13@1+ (1,0) [0|8000] "RPM"  IVI,TBOX
 SG_ gcu_0x10C_timeoutFlag : 29|1@1+ (1,0) [0|1] ""  IVI,TBOX
 SG_ ecu_0x30B_timeoutFlag : 30|1@1+ (1,0) [0|1] ""  IVI
 SG_ ecu_0x31B_timeoutFlag : 31|1@1+ (1,0) [0|1] ""  IVI
 SG_ ecu_engCoolantTemp : 32|8@1+ (0.75,-48) [-48|142.5] "℃"  IVI,TBOX
 SG_ ecu_fuelConsump100ms : 40|12@1+ (0.001,0) [0|4] "ml"  IVI,TBOX
 SG_ ecu_milIndicator : 52|2@1+ (1,0) [0|3] ""  IVI
 SG_ vcu_coolantLevelLow : 54|1@1+ (1,0) [0|1] ""  IVI
 SG_ vcu_0x531_timeoutFlag : 55|1@1+ (1,0) [0|1] "" Vector__XXX
 SG_ ecu_state : 56|3@1+ (1,0) [0|7] ""  TBOX
 SG_ ecu_engStartSuccess : 59|1@1+ (1,0) [0|1] ""  TBOX
 SG_ ecu_engSpdErr : 60|1@1+ (1,0) [0|1] ""  IVI
 SG_ ecu_0x39B_timeoutFlag : 61|1@1+ (1,0) [0|1] ""  IVI

BO_ 896 ACU_state: 8 GW
 SG_ acu_warningLampSts : 0|2@1+ (1,0) [0|3] ""  IVI
 SG_ acu_crashOutputStsValid : 2|2@1+ (1,0) [0|3] ""  TBOX
 SG_ acu_crashOutputSts : 4|2@1+ (1,0) [0|3] ""  ICM,TBOX
 SG_ acu_driverSeatBeltSts : 8|1@1+ (1,0) [0|1] ""  ICM,IVI
 SG_ acu_driverSeatBeltStsValid : 9|1@1+ (1,0) [0|1] ""  IVI
 SG_ acu_passengerSeatBeltSts : 10|1@1+ (1,0) [0|1] ""  IVI
 SG_ acu_passengerSeatBeltStsValid : 11|1@1+ (1,0) [0|1] ""  IVI
 SG_ acu_passengerAirbagSts : 12|2@1+ (1,0) [0|3] ""  IVI
 SG_ acu_secondLeftSeatBeltSts : 14|1@1+ (1,0) [0|1] ""  IVI
 SG_ acu_secondMiddleSeatBeltSts : 15|1@1+ (1,0) [0|1] ""  IVI
 SG_ acu_secondRightSeatBeltSts : 16|1@1+ (1,0) [0|1] ""  IVI
 SG_ acu_passengerSts : 17|1@1+ (1,0) [0|1] ""  IVI
 SG_ acu_secondLeftSts : 18|1@1+ (1,0) [0|1] ""  IVI
 SG_ acu_secondMiddleSts : 19|1@1+ (1,0) [0|1] ""  IVI
 SG_ acu_secondRightSts : 20|1@1+ (1,0) [0|1] ""  IVI
 SG_ acu_380_RollingCounter : 52|4@1+ (1,0) [0|15] ""  ICM,IVI
 SG_ acu_380_Checksum : 56|8@1+ (1,0) [0|255] ""  ICM,IVI

BO_ 903 OBC_state: 8 GW
 SG_ obc_hardwareFaultSts : 0|2@1+ (1,0) [0|3] ""  TBOX
 SG_ obc_lockMotorSts : 2|2@1+ (1,0) [0|3] ""  IVI,TBOX
 SG_ obc_errorFlag : 4|4@1+ (1,0) [0|15] ""  TBOX
 SG_ obc_state : 8|4@1+ (1,0) [0|15] ""  TBOX
 SG_ obc_s2Sts : 12|1@1+ (1,0) [0|1] ""  TBOX
 SG_ obc_batteryConnectSts : 13|1@1+ (1,0) [0|1] ""  TBOX
 SG_ obc_ccOhm : 14|4@1+ (1,0) [0|15] ""  IVI,TBOX
 SG_ obc_chargeSts : 18|1@1+ (1,0) [0|1] ""  TBOX
 SG_ obc_cpVoltage : 19|8@1+ (0.1,0) [0|25.5] ""  TBOX
 SG_ obc_slowChargeRelaySts : 27|2@1+ (1,0) [0|2] ""  TBOX
 SG_ obc_fastChargeRelayHSts : 29|2@1+ (1,0) [0|2] ""  TBOX
 SG_ obc_fastChargeRelayLSts : 31|2@1+ (1,0) [0|2] ""  TBOX
 SG_ obc_chargerEndChargeReq : 33|1@1+ (1,0) [0|1] ""  TBOX
 SG_ obc_387_Rollingcounter : 36|4@1+ (1,0) [0|15] ""  TBOX
 SG_ obc_387_Checksum : 40|8@1+ (1,0) [0|255] ""  TBOX

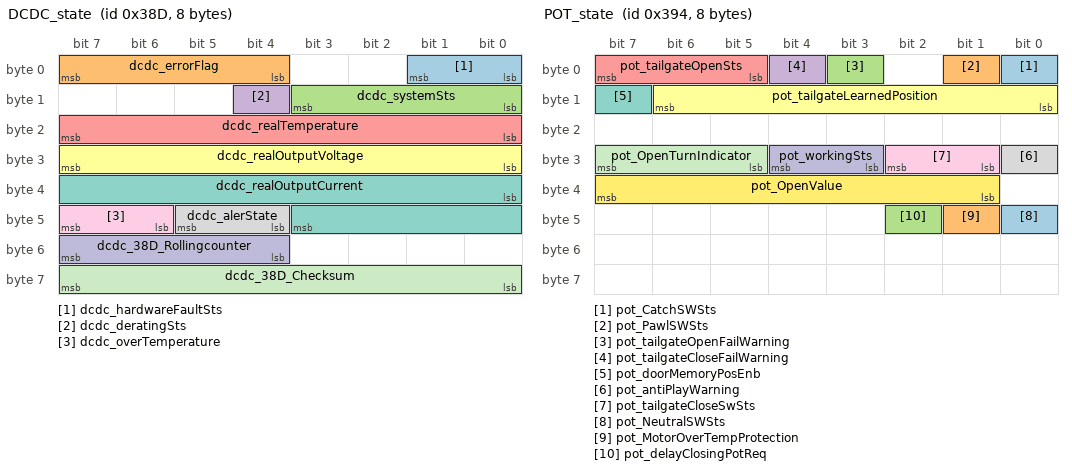
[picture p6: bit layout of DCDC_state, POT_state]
BO_ 909 DCDC_state: 8 GW
 SG_ dcdc_hardwareFaultSts : 0|2@1+ (1,0) [0|3] ""  TBOX
 SG_ dcdc_errorFlag : 4|4@1+ (1,0) [0|15] "" Vector__XXX
 SG_ dcdc_systemSts : 8|4@1+ (1,0) [0|15] ""  IVI,TBOX
 SG_ dcdc_deratingSts : 12|1@1+ (1,0) [0|1] "" Vector__XXX
 SG_ dcdc_realTemperature : 16|8@1+ (1,-40) [-40|120] "degreeC" Vector__XXX
 SG_ dcdc_realOutputVoltage : 24|8@1+ (0.1,0) [0|25.5] "V"  TBOX
 SG_ dcdc_realOutputCurrent : 32|12@1+ (0.1,0) [0|409.5] "A"  IVI,TBOX
 SG_ dcdc_alerState : 44|2@1+ (1,0) [0|3] ""  TBOX
 SG_ dcdc_overTemperature : 46|2@1+ (1,0) [0|3] ""  TBOX
 SG_ dcdc_38D_Rollingcounter : 52|4@1+ (1,0) [0|15] "" Vector__XXX
 SG_ dcdc_38D_Checksum : 56|8@1+ (1,0) [0|255] "" Vector__XXX

BO_ 916 POT_state: 8 GW
 SG_ pot_CatchSWSts : 0|1@1+ (1,0) [0|1] ""  IVI
 SG_ pot_PawlSWSts : 1|1@1+ (1,0) [0|1] ""  IVI
 SG_ pot_tailgateOpenFailWarning : 3|1@1+ (1,0) [0|1] ""  IVI
 SG_ pot_tailgateCloseFailWarning : 4|1@1+ (1,0) [0|1] ""  IVI
 SG_ pot_tailgateOpenSts : 5|3@1+ (1,0) [0|7] ""  IVI,TBOX
 SG_ pot_tailgateLearnedPosition : 8|7@1+ (1,0) [0|100] "%"  IVI
 SG_ pot_doorMemoryPosEnb : 15|1@1+ (1,0) [0|1] ""  IVI
 SG_ pot_antiPlayWarning : 24|1@1+ (1,0) [0|1] ""  IVI
 SG_ pot_tailgateCloseSwSts : 25|2@1+ (1,0) [0|3] ""  IVI
 SG_ pot_workingSts : 27|2@1+ (1,0) [0|3] ""  IVI
 SG_ pot_OpenTurnIndicator : 29|3@1+ (1,0) [0|7] ""  IVI
 SG_ pot_OpenValue : 33|7@1+ (1,0) [0|100] "%"  IVI
 SG_ pot_NeutralSWSts : 40|1@1+ (1,0) [0|1] ""  IVI
 SG_ pot_MotorOverTempProtection : 41|1@1+ (1,0) [0|1] ""  IVI
 SG_ pot_delayClosingPotReq : 42|1@1+ (1,0) [0|1] "" Vector__XXX

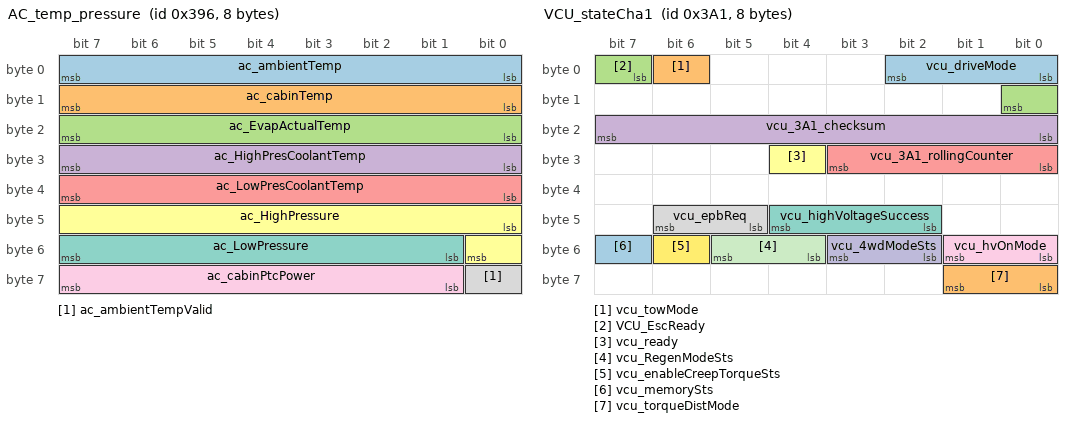
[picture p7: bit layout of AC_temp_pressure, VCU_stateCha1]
BO_ 918 AC_temp_pressure: 8 GW
 SG_ ac_ambientTemp : 0|8@1+ (0.5,-40) [-40|85] "degreeC"  IVI,PDC,TBOX
 SG_ ac_cabinTemp : 8|8@1+ (0.5,-40) [-40|85] "degreeC"  IVI,TBOX
 SG_ ac_EvapActualTemp : 16|8@1+ (0.5,-40) [-40|85] "degreeC" Vector__XXX
 SG_ ac_HighPresCoolantTemp : 24|8@1+ (0.5,-40) [-40|85] "degreeC" Vector__XXX
 SG_ ac_LowPresCoolantTemp : 32|8@1+ (0.5,-40) [-40|85] "degreeC" Vector__XXX
 SG_ ac_HighPressure : 40|9@1+ (0.1,0) [0|36] "Bar" Vector__XXX
 SG_ ac_LowPressure : 49|7@1+ (0.1,0) [0|12] "Bar" Vector__XXX
 SG_ ac_ambientTempValid : 56|1@1+ (1,0) [0|1] "bit"  IVI,PDC,TBOX
 SG_ ac_cabinPtcPower : 57|7@1+ (0.1,0) [0|10] "KW"  TBOX

BO_ 929 VCU_stateCha1: 8 GW
 SG_ vcu_driveMode : 0|3@1+ (1,0) [0|7] ""  IVI,TBOX
 SG_ vcu_towMode : 6|1@1+ (1,0) [0|1] ""  IVI,TBOX
 SG_ VCU_EscReady : 7|2@1+ (1,0) [0|3] "" Vector__XXX
 SG_ vcu_3A1_checksum : 16|8@1+ (1,0) [0|255] "" Vector__XXX
 SG_ vcu_3A1_rollingCounter : 24|4@1+ (1,0) [0|15] "" Vector__XXX
 SG_ vcu_ready : 28|1@1+ (1,0) [0|1] ""  ICM,IVI,TBOX,VSP
 SG_ vcu_highVoltageSuccess : 42|3@1+ (1,0) [0|7] ""  IVI
 SG_ vcu_epbReq : 45|2@1+ (1,0) [0|3] "" Vector__XXX
 SG_ vcu_hvOnMode : 48|2@1+ (1,0) [0|3] ""  IVI,TBOX
 SG_ vcu_4wdModeSts : 50|2@1+ (1,0) [0|3] ""  IVI
 SG_ vcu_RegenModeSts : 52|2@1+ (1,0) [0|3] ""  IVI,TBOX
 SG_ vcu_enableCreepTorqueSts : 54|1@1+ (1,0) [0|1] ""  IVI
 SG_ vcu_memorySts : 55|1@1+ (1,0) [0|1] ""  IVI,TBOX
 SG_ vcu_torqueDistMode : 56|2@1+ (1,0) [0|3] ""  IVI

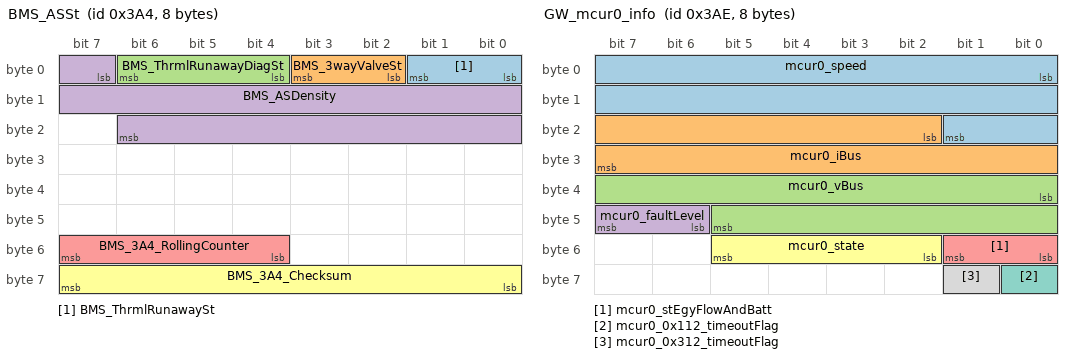
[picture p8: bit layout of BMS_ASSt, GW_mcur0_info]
BO_ 932 BMS_ASSt: 8 GW
 SG_ BMS_ThrmlRunawaySt : 0|2@1+ (1,0) [0|3] ""  IVI,TBOX
 SG_ BMS_3wayValveSt : 2|2@1+ (1,0) [0|3] "" Vector__XXX
 SG_ BMS_ThrmlRunawayDiagSt : 4|3@1+ (1,0) [0|7] "" Vector__XXX
 SG_ BMS_ASDensity : 7|16@1+ (1,0) [0|10000] ""  TBOX
 SG_ BMS_3A4_RollingCounter : 52|4@1+ (1,0) [0|15] ""  IVI,TBOX
 SG_ BMS_3A4_Checksum : 56|8@1+ (1,0) [0|255] ""  IVI,TBOX

BO_ 942 GW_mcur0_info: 8 GW
 SG_ mcur0_speed : 0|18@1- (0.2,0) [-26000|26000] "RPM"  IVI,TBOX
 SG_ mcur0_iBus : 18|14@1+ (0.2,-600) [-600|2500] "A"  TBOX
 SG_ mcur0_vBus : 32|14@1+ (0.05,0) [0|800] "V"  TBOX
 SG_ mcur0_faultLevel : 46|2@1+ (1,0) [0|3] ""  IVI
 SG_ mcur0_stEgyFlowAndBatt : 48|2@1+ (1,0) [0|3] ""  IVI
 SG_ mcur0_state : 50|4@1+ (1,0) [0|15] ""  TBOX
 SG_ mcur0_0x112_timeoutFlag : 56|1@1+ (1,0) [0|1] ""  IVI
 SG_ mcur0_0x312_timeoutFlag : 57|1@1+ (1,0) [0|1] ""  IVI

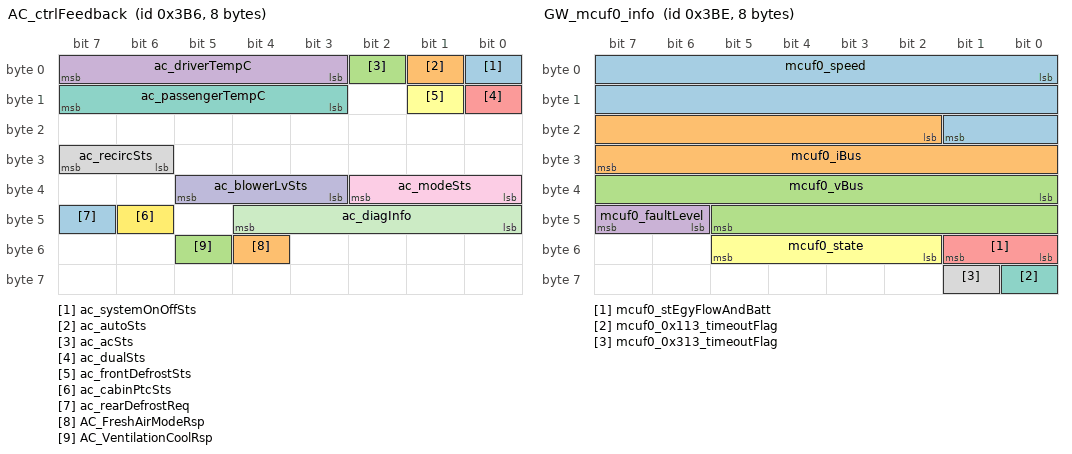
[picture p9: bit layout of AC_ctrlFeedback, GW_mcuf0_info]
BO_ 950 AC_ctrlFeedback: 8 GW
 SG_ ac_systemOnOffSts : 0|1@1+ (1,0) [0|1] ""  IVI,TBOX
 SG_ ac_autoSts : 1|1@1+ (1,0) [0|1] ""  IVI,TBOX
 SG_ ac_acSts : 2|1@1+ (1,0) [0|1] ""  IVI,TBOX
 SG_ ac_driverTempC : 3|5@1+ (0.5,15.5) [15.5|30.5] "degreeC"  IVI,TBOX
 SG_ ac_dualSts : 8|1@1+ (1,0) [0|1] ""  IVI
 SG_ ac_frontDefrostSts : 9|1@1+ (1,0) [0|1] ""  IVI,TBOX
 SG_ ac_passengerTempC : 11|5@1+ (0.5,15.5) [15.5|30.5] "degreeC"  IVI,TBOX
 SG_ ac_recircSts : 30|2@1+ (1,0) [0|3] ""  IVI,TBOX
 SG_ ac_modeSts : 32|3@1+ (1,0) [0|7] ""  IVI,TBOX
 SG_ ac_blowerLvSts : 35|3@1+ (1,0) [0|7] ""  IVI,TBOX
 SG_ ac_diagInfo : 40|5@1+ (1,0) [0|31] ""  IVI,TBOX
 SG_ ac_cabinPtcSts : 46|1@1+ (1,0) [0|1] ""  IVI
 SG_ ac_rearDefrostReq : 47|1@1+ (1,0) [0|1] "" Vector__XXX
 SG_ AC_FreshAirModeRsp : 52|1@1+ (1,0) [0|1] ""  IVI
 SG_ AC_VentilationCoolRsp : 53|1@1+ (1,0) [0|1] ""  IVI

BO_ 958 GW_mcuf0_info: 8 GW
 SG_ mcuf0_speed : 0|18@1- (0.2,0) [-26000|26000] "RPM"  IVI,TBOX
 SG_ mcuf0_iBus : 18|14@1+ (0.2,-600) [-600|2500] "A"  TBOX
 SG_ mcuf0_vBus : 32|14@1+ (0.05,0) [0|800] "V"  TBOX
 SG_ mcuf0_faultLevel : 46|2@1+ (1,0) [0|3] ""  IVI
 SG_ mcuf0_stEgyFlowAndBatt : 48|2@1+ (1,0) [0|3] ""  IVI
 SG_ mcuf0_state : 50|4@1+ (1,0) [0|15] ""  TBOX
 SG_ mcuf0_0x113_timeoutFlag : 56|1@1+ (1,0) [0|1] ""  IVI
 SG_ mcuf0_0x313_timeoutFlag : 57|1@1+ (1,0) [0|1] ""  IVI

BO_ 961 BCM_state2: 8 GW
 SG_ bcm_rearMirrorSts : 0|1@1+ (1,0) [0|1] ""  IVI
 SG_ bcm_DRLSts : 1|1@1+ (1,0) [0|1] ""  IVI
 SG_ bcm_sunroofSts : 2|3@1+ (1,0) [0|7] ""  IVI,TBOX
 SG_ bcm_sunshadeSts : 5|3@1+ (1,0) [0|7] ""  IVI,TBOX
 SG_ bcm_windowLFSts : 8|3@1+ (1,0) [0|7] ""  IVI,TBOX
 SG_ bcm_windowRFSts : 11|3@1+ (1,0) [0|7] ""  IVI,TBOX
 SG_ bcm_leftBsdLedSts : 14|1@1+ (1,0) [0|1] "" Vector__XXX
 SG_ bcm_rightBsdLedSts : 15|1@1+ (1,0) [0|1] "" Vector__XXX
 SG_ bcm_windowLRSts : 16|3@1+ (1,0) [0|7] ""  IVI,TBOX
 SG_ bcm_windowRRSts : 19|3@1+ (1,0) [0|7] ""  IVI,TBOX
 SG_ bcm_rearDefrostSts : 22|1@1+ (1,0) [0|1] ""  IVI,TBOX
 SG_ bcm_delayClosingPotReq : 23|1@1+ (1,0) [0|1] "" Vector__XXX
 SG_ bcm_rkeTailgateCtrlCmd : 24|2@1+ (1,0) [0|3] "" Vector__XXX
 SG_ bcm_rainSensorError : 28|1@1+ (1,0) [0|1] "" Vector__XXX
 SG_ bcm_GlassUncloseWarning : 29|1@1+ (1,0) [0|1] ""  TBOX
 SG_ bcm_posLampSts : 30|1@1+ (1,0) [0|1] ""  ICM,IVI
 SG_ bcm_autoLampSwSts : 31|1@1+ (1,0) [0|1] ""  IVI
 SG_ bcm_rsmSolarRight : 32|8@1+ (5,0) [0|1265] "w/m2"  IVI
 SG_ bcm_rsmSolarLeft : 40|8@1+ (5,0) [0|1265] "w/m2"  IVI
 SG_ bcm_lowBeamSts : 48|1@1+ (1,0) [0|1] ""  ICM,IVI,NVS,TBOX
 SG_ bcm_highBeamSts : 50|1@1+ (1,0) [0|1] ""  ICM,IVI,NVS,TBOX
 SG_ bcm_kickActiveReq : 52|1@1+ (1,0) [0|1] "" Vector__XXX
 SG_ bcm_rlsSensitivity : 53|3@1+ (1,0) [0|7] "" Vector__XXX
 SG_ bcm_rearFogLampSts : 56|1@1+ (1,0) [0|1] ""  ICM,IVI,TBOX
 SG_ bcm_lightSensorError : 58|1@1+ (1,0) [0|1] "" Vector__XXX
 SG_ bcm_remoteForbidden : 61|2@1+ (1,0) [0|3] ""  IVI,TBOX
 SG_ BCM_rlsWindowCloseReq : 63|1@1+ (1,0) [0|1] ""  ICM

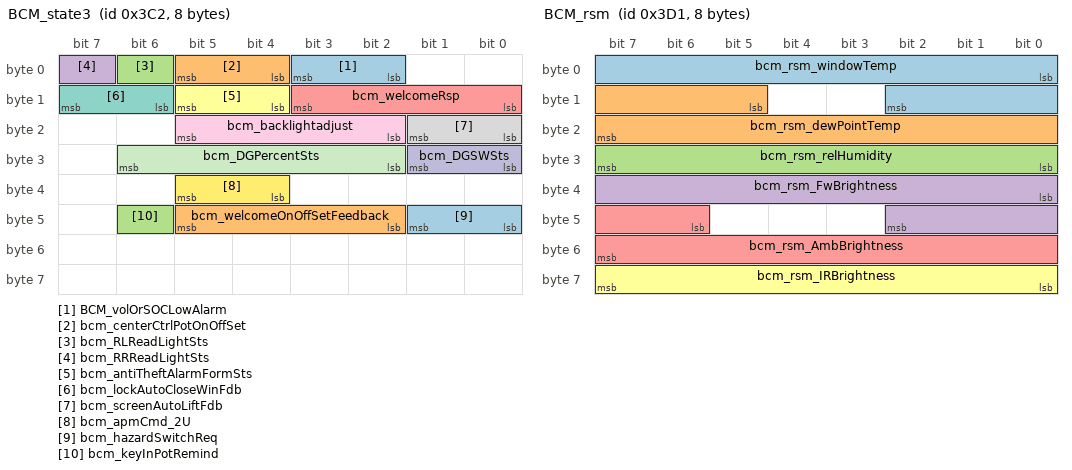
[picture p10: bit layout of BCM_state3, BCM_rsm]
BO_ 962 BCM_state3: 8 GW
 SG_ BCM_volOrSOCLowAlarm : 2|2@1+ (1,0) [0|3] ""  IVI
 SG_ bcm_centerCtrlPotOnOffSet : 4|2@1+ (1,0) [0|3] "" Vector__XXX
 SG_ bcm_RLReadLightSts : 6|1@1+ (1,0) [0|1] ""  ICM
 SG_ bcm_RRReadLightSts : 7|1@1+ (1,0) [0|1] ""  ICM
 SG_ bcm_welcomeRsp : 8|4@1+ (1,0) [0|15] "" Vector__XXX
 SG_ bcm_antiTheftAlarmFormSts : 12|2@1+ (1,0) [0|3] ""  IVI
 SG_ bcm_lockAutoCloseWinFdb : 14|2@1+ (1,0) [0|3] ""  IVI
 SG_ bcm_screenAutoLiftFdb : 16|2@1+ (1,0) [0|3] ""  IVI
 SG_ bcm_backlightadjust : 18|4@1+ (1,0) [0|10] ""  IVI
 SG_ bcm_DGSWSts : 24|2@1+ (1,0) [0|3] ""  IVI
 SG_ bcm_DGPercentSts : 26|5@1+ (1,0) [0|31] ""  IVI
 SG_ bcm_apmCmd_2U : 36|2@1+ (1,0) [0|3] "" Vector__XXX
 SG_ bcm_hazardSwitchReq : 40|2@1+ (1,0) [0|3] "" Vector__XXX
 SG_ bcm_welcomeOnOffSetFeedback : 42|4@1+ (1,0) [0|15] ""  IVI
 SG_ bcm_keyInPotRemind : 46|1@1+ (1,0) [0|1] "" Vector__XXX

BO_ 977 BCM_rsm: 8 GW
 SG_ bcm_rsm_windowTemp : 0|11@1+ (0.1,-39.6) [-39.6|100] "degreeC" Vector__XXX
 SG_ bcm_rsm_dewPointTemp : 13|11@1+ (0.1,-39.6) [-39.6|100] "degreeC" Vector__XXX
 SG_ bcm_rsm_relHumidity : 24|8@1+ (0.5,-0.5) [-0.5|100] "%" Vector__XXX
 SG_ bcm_rsm_FwBrightness : 32|11@1+ (1,0) [0|2045] "lux"  ICM,IVI,NVS
 SG_ bcm_rsm_AmbBrightness : 46|10@1+ (1,0) [0|1021] "lux"  IVI
 SG_ bcm_rsm_IRBrightness : 56|8@1+ (8,0) [0|2024] "lux"  IVI

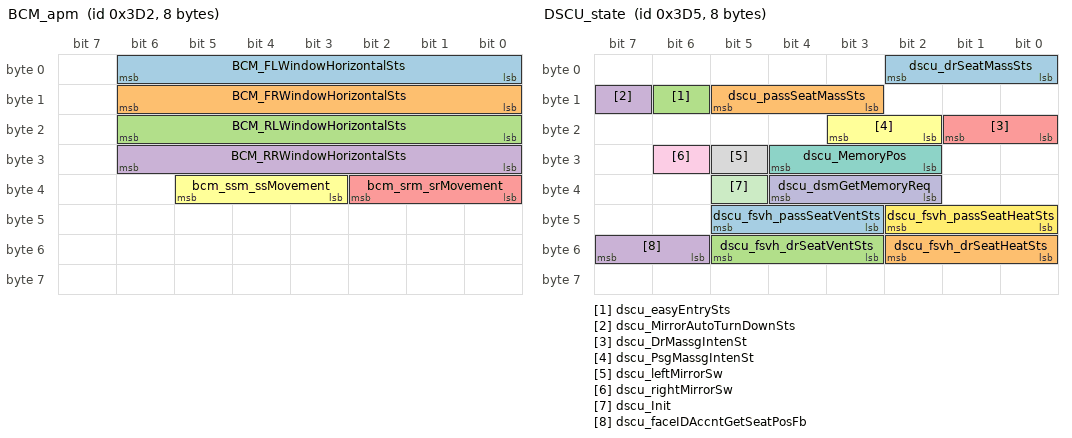
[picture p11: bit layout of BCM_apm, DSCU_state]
BO_ 978 BCM_apm: 8 GW
 SG_ BCM_FLWindowHorizontalSts : 0|7@1+ (1,0) [0|100] "%"  IVI,TBOX
 SG_ BCM_FRWindowHorizontalSts : 8|7@1+ (1,0) [0|100] "%"  IVI,TBOX
 SG_ BCM_RLWindowHorizontalSts : 16|7@1+ (1,0) [0|100] "%"  IVI,TBOX
 SG_ BCM_RRWindowHorizontalSts : 24|7@1+ (1,0) [0|100] "%"  IVI,TBOX
 SG_ bcm_srm_srMovement : 32|3@1+ (1,0) [0|7] ""  IVI
 SG_ bcm_ssm_ssMovement : 35|3@1+ (1,0) [0|7] ""  IVI

BO_ 981 DSCU_state: 8 GW
 SG_ dscu_drSeatMassSts : 0|3@1+ (1,0) [0|7] ""  IVI
 SG_ dscu_passSeatMassSts : 11|3@1+ (1,0) [0|7] ""  IVI
 SG_ dscu_easyEntrySts : 14|1@1+ (1,0) [0|1] ""  IVI
 SG_ dscu_MirrorAutoTurnDownSts : 15|1@1+ (1,0) [0|1] ""  IVI
 SG_ dscu_DrMassgIntenSt : 16|2@1+ (1,0) [0|3] ""  IVI
 SG_ dscu_PsgMassgIntenSt : 18|2@1+ (1,0) [0|3] ""  IVI
 SG_ dscu_MemoryPos : 26|3@1+ (1,0) [0|7] ""  IVI
 SG_ dscu_leftMirrorSw : 29|1@1+ (1,0) [0|1] "" Vector__XXX
 SG_ dscu_rightMirrorSw : 30|1@1+ (1,0) [0|1] "" Vector__XXX
 SG_ dscu_dsmGetMemoryReq : 34|3@1+ (1,0) [0|7] ""  IVI
 SG_ dscu_Init : 37|1@1+ (1,0) [0|1] ""  IVI
 SG_ dscu_fsvh_passSeatHeatSts : 40|3@1+ (1,0) [0|7] ""  IVI,TBOX
 SG_ dscu_fsvh_passSeatVentSts : 43|3@1+ (1,0) [0|7] ""  IVI
 SG_ dscu_fsvh_drSeatHeatSts : 48|3@1+ (1,0) [0|7] ""  IVI,TBOX
 SG_ dscu_fsvh_drSeatVentSts : 51|3@1+ (1,0) [0|7] ""  IVI
 SG_ dscu_faceIDAccntGetSeatPosFb : 54|2@1+ (1,0) [0|3] ""  IVI

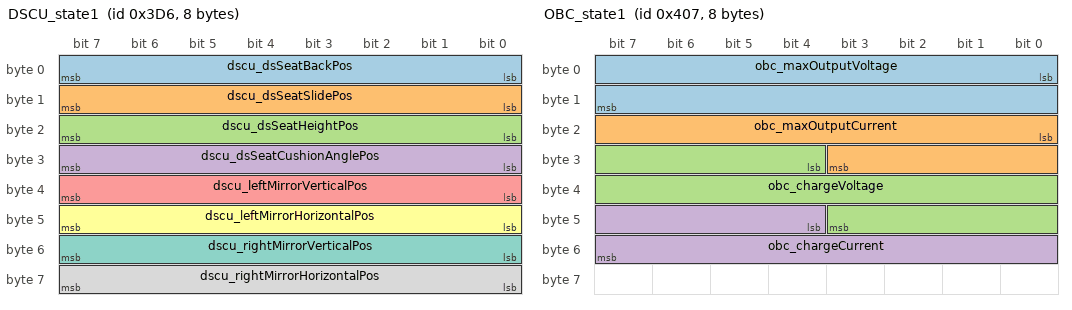
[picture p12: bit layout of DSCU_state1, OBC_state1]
BO_ 982 DSCU_state1: 8 GW
 SG_ dscu_dsSeatBackPos : 0|8@1+ (1,0) [0|100] "%"  IVI
 SG_ dscu_dsSeatSlidePos : 8|8@1+ (1,0) [0|100] "%"  IVI
 SG_ dscu_dsSeatHeightPos : 16|8@1+ (1,0) [0|100] "%"  IVI
 SG_ dscu_dsSeatCushionAnglePos : 24|8@1+ (1,0) [0|100] "%"  IVI
 SG_ dscu_leftMirrorVerticalPos : 32|8@1+ (1,0) [0|100] "%"  IVI
 SG_ dscu_leftMirrorHorizontalPos : 40|8@1+ (1,0) [0|100] "%"  IVI
 SG_ dscu_rightMirrorVerticalPos : 48|8@1+ (1,0) [0|100] "%"  IVI
 SG_ dscu_rightMirrorHorizontalPos : 56|8@1+ (1,0) [0|100] "%"  IVI

BO_ 1031 OBC_state1: 8 GW
 SG_ obc_maxOutputVoltage : 0|16@1+ (0.1,0) [0|6553.5] "V" Vector__XXX
 SG_ obc_maxOutputCurrent : 16|12@1+ (0.1,0) [0|409.5] "A"  TBOX
 SG_ obc_chargeVoltage : 28|16@1+ (0.1,0) [0|6553.5] "V"  IVI,TBOX
 SG_ obc_chargeCurrent : 44|12@1+ (0.1,0) [0|409.5] "A"  IVI,TBOX

BO_ 255 OBC1: 8 GW
 SG_ OBC_AcChgEnergy : 0|11@1+ (0.1,0) [0|200] "kwh"  TBOX

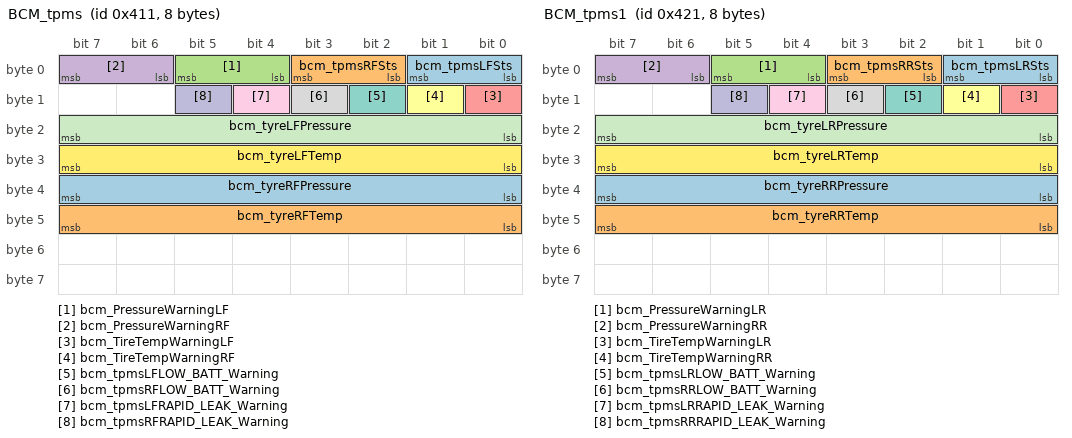
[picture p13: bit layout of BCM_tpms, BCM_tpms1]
BO_ 1041 BCM_tpms: 8 GW
 SG_ bcm_tpmsLFSts : 0|2@1+ (1,0) [0|3] ""  IVI
 SG_ bcm_tpmsRFSts : 2|2@1+ (1,0) [0|3] ""  IVI
 SG_ bcm_PressureWarningLF : 4|2@1+ (1,0) [0|3] ""  IVI
 SG_ bcm_PressureWarningRF : 6|2@1+ (1,0) [0|3] ""  IVI
 SG_ bcm_TireTempWarningLF : 8|1@1+ (1,0) [0|1] ""  IVI
 SG_ bcm_TireTempWarningRF : 9|1@1+ (1,0) [0|1] ""  IVI
 SG_ bcm_tpmsLFLOW_BATT_Warning : 10|1@1+ (1,0) [0|1] ""  IVI
 SG_ bcm_tpmsRFLOW_BATT_Warning : 11|1@1+ (1,0) [0|1] ""  IVI
 SG_ bcm_tpmsLFRAPID_LEAK_Warning : 12|1@1+ (1,0) [0|1] ""  IVI
 SG_ bcm_tpmsRFRAPID_LEAK_Warning : 13|1@1+ (1,0) [0|1] ""  IVI
 SG_ bcm_tyreLFPressure : 16|8@1+ (0.1,0) [0|7] "bar"  IVI
 SG_ bcm_tyreLFTemp : 24|8@1+ (1,-61) [-61|193] "degreeC"  IVI
 SG_ bcm_tyreRFPressure : 32|8@1+ (0.1,0) [0|7] "bar"  IVI
 SG_ bcm_tyreRFTemp : 40|8@1+ (1,-61) [-61|193] "degreeC"  IVI

BO_ 1057 BCM_tpms1: 8 GW
 SG_ bcm_tpmsLRSts : 0|2@1+ (1,0) [0|3] ""  IVI
 SG_ bcm_tpmsRRSts : 2|2@1+ (1,0) [0|3] ""  IVI
 SG_ bcm_PressureWarningLR : 4|2@1+ (1,0) [0|3] ""  IVI
 SG_ bcm_PressureWarningRR : 6|2@1+ (1,0) [0|3] ""  IVI
 SG_ bcm_TireTempWarningLR : 8|1@1+ (1,0) [0|1] ""  IVI
 SG_ bcm_TireTempWarningRR : 9|1@1+ (1,0) [0|1] ""  IVI
 SG_ bcm_tpmsLRLOW_BATT_Warning : 10|1@1+ (1,0) [0|1] ""  IVI
 SG_ bcm_tpmsRRLOW_BATT_Warning : 11|1@1+ (1,0) [0|1] ""  IVI
 SG_ bcm_tpmsLRRAPID_LEAK_Warning : 12|1@1+ (1,0) [0|1] ""  IVI
 SG_ bcm_tpmsRRRAPID_LEAK_Warning : 13|1@1+ (1,0) [0|1] ""  IVI
 SG_ bcm_tyreLRPressure : 16|8@1+ (0.1,0) [0|7] "bar"  IVI
 SG_ bcm_tyreLRTemp : 24|8@1+ (1,-61) [-61|193] "degreeC"  IVI
 SG_ bcm_tyreRRPressure : 32|8@1+ (0.1,0) [0|7] "bar"  IVI
 SG_ bcm_tyreRRTemp : 40|8@1+ (1,-61) [-61|193] "degreeC"  IVI

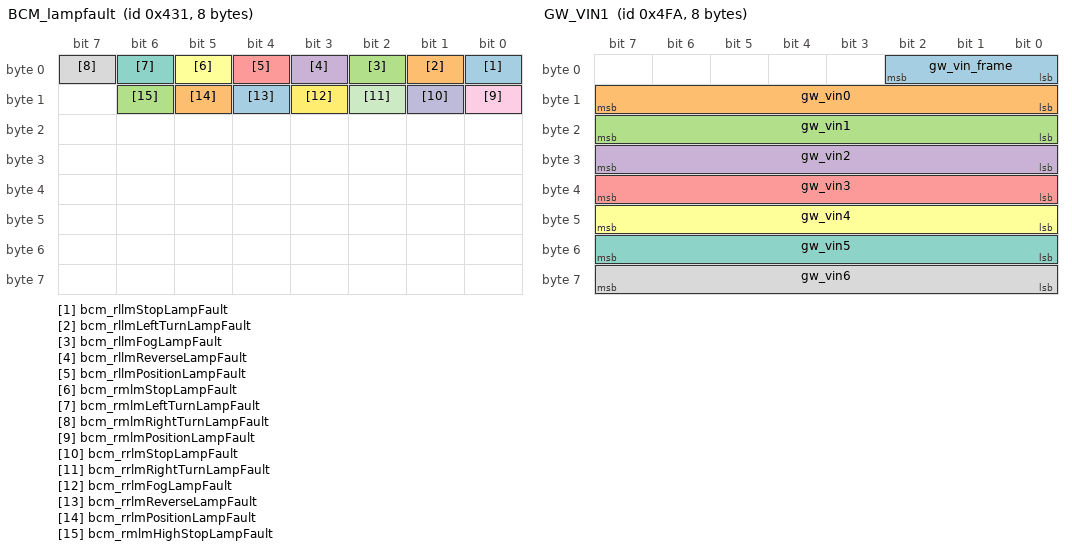
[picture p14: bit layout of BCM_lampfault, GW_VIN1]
BO_ 1073 BCM_lampfault: 8 GW
 SG_ bcm_rllmStopLampFault : 0|1@1+ (1,0) [0|1] ""  IVI
 SG_ bcm_rllmLeftTurnLampFault : 1|1@1+ (1,0) [0|1] ""  IVI
 SG_ bcm_rllmFogLampFault : 2|1@1+ (1,0) [0|1] ""  IVI
 SG_ bcm_rllmReverseLampFault : 3|1@1+ (1,0) [0|1] ""  IVI
 SG_ bcm_rllmPositionLampFault : 4|1@1+ (1,0) [0|1] ""  IVI
 SG_ bcm_rmlmStopLampFault : 5|1@1+ (1,0) [0|1] ""  IVI
 SG_ bcm_rmlmLeftTurnLampFault : 6|1@1+ (1,0) [0|1] ""  IVI
 SG_ bcm_rmlmRightTurnLampFault : 7|1@1+ (1,0) [0|1] ""  IVI
 SG_ bcm_rmlmPositionLampFault : 8|1@1+ (1,0) [0|1] ""  IVI
 SG_ bcm_rrlmStopLampFault : 9|1@1+ (1,0) [0|1] ""  IVI
 SG_ bcm_rrlmRightTurnLampFault : 10|1@1+ (1,0) [0|1] ""  IVI
 SG_ bcm_rrlmFogLampFault : 11|1@1+ (1,0) [0|1] ""  IVI
 SG_ bcm_rrlmReverseLampFault : 12|1@1+ (1,0) [0|1] ""  IVI
 SG_ bcm_rrlmPositionLampFault : 13|1@1+ (1,0) [0|1] ""  IVI
 SG_ bcm_rmlmHighStopLampFault : 14|1@1+ (1,0) [0|1] ""  IVI

BO_ 1089 VCU_vehicle: 8 GW
 SG_ vcu_vehicleSpeed : 0|9@1+ (1,-100) [-100|300] "kph"  IVI,TBOX
 SG_ vcu_cruiseCtrlSetSpeed : 9|8@1+ (1,0) [0|255] "kph"  TBOX
 SG_ vcu_brakeLight : 17|1@1+ (1,0) [0|1] ""  TBOX
 SG_ vcu_alertLevel : 18|3@1+ (1,0) [0|7] ""  IVI,TBOX
 SG_ vcu_driveReady : 21|1@1+ (1,0) [0|1] ""  IVI,TBOX
 SG_ vcu_hvState : 22|2@1+ (1,0) [0|3] ""  TBOX
 SG_ vcu_highVoltFail : 24|2@1+ (1,0) [0|3] ""  IVI,TBOX
 SG_ vcu_regenmode : 26|1@1+ (1,0) [0|1] ""  IVI
 SG_ vcu_drivePowerAllowed : 27|10@1+ (0.5,0) [0|511.5] "kW"  IVI
 SG_ vcu_gearSwitchFail : 37|1@1+ (1,0) [0|1] "" Vector__XXX
 SG_ vcu_refuelReq : 38|1@1+ (1,0) [0|1] "" Vector__XXX
 SG_ vcu_drivePowerAcutal : 40|10@1+ (0.5,0) [0|511.5] "kW"  IVI
 SG_ vcu_evModeDisplay : 50|2@1+ (1,0) [0|3] ""  IVI,TBOX
 SG_ VCU_VehicleSpeedValid : 52|1@1+ (1,0) [0|1] ""  TBOX
 SG_ vcu_RmtEngStartReq : 53|1@1+ (1,0) [0|1] ""  TBOX
 SG_ vcu_ExhibitionSts : 54|2@1+ (1,0) [0|3] ""  IVI
 SG_ vcu_remoteVehicleForbiddenStart : 61|2@1+ (1,0) [0|3] ""  TBOX

BO_ 1274 GW_VIN1: 8 GW
 SG_ gw_vin_frame : 0|3@1+ (1,0) [0|7] ""  ETC,TBOX
 SG_ gw_vin0 : 8|8@1+ (1,0) [0|255] ""  ETC,TBOX
 SG_ gw_vin1 : 16|8@1+ (1,0) [0|255] ""  ETC,TBOX
 SG_ gw_vin2 : 24|8@1+ (1,0) [0|255] ""  ETC,TBOX
 SG_ gw_vin3 : 32|8@1+ (1,0) [0|255] ""  ETC,TBOX
 SG_ gw_vin4 : 40|8@1+ (1,0) [0|255] ""  ETC,TBOX
 SG_ gw_vin5 : 48|8@1+ (1,0) [0|255] ""  ETC,TBOX
 SG_ gw_vin6 : 56|8@1+ (1,0) [0|255] ""  ETC,TBOX

BO_ 1275 GW_Mode: 8 GW
 SG_ GW_Mode : 0|3@1+ (1,0) [0|6] ""  TBOX

BO_ 1297 VCU_tboxGeneralAlert: 8 GW
 SG_ vcu_cellTemperatureDifHig : 0|1@1+ (1,0) [0|1] ""  TBOX
 SG_ vcu_batteryOverTemperature : 1|1@1+ (1,0) [0|1] ""  IVI,TBOX
 SG_ vcu_overVoltage : 2|1@1+ (1,0) [0|1] ""  TBOX
 SG_ vcu_lowVoltage : 3|1@1+ (1,0) [0|1] ""  TBOX
 SG_ vcu_lowSoc : 4|1@1+ (1,0) [0|1] ""  TBOX
 SG_ vcu_cellOverVoltage : 5|1@1+ (1,0) [0|1] ""  TBOX
 SG_ vcu_cellLowVoltage : 6|1@1+ (1,0) [0|1] ""  TBOX
 SG_ vcu_highSoc : 7|1@1+ (1,0) [0|1] ""  TBOX
 SG_ vcu_socStepChange : 8|1@1+ (1,0) [0|1] ""  TBOX
 SG_ vcu_chargerMismatch : 9|1@1+ (1,0) [0|1] ""  TBOX
 SG_ vcu_cellOutOfBalance : 10|1@1+ (1,0) [0|1] ""  TBOX
 SG_ vcu_isolationFault : 11|1@1+ (1,0) [0|1] ""  TBOX
 SG_ vcu_dcdcOverTemperature : 12|1@1+ (1,0) [0|1] ""  IVI,TBOX
 SG_ vcu_brakeFault : 13|1@1+ (1,0) [0|1] ""  TBOX
 SG_ vcu_dcdcAlerState : 14|1@1+ (1,0) [0|1] ""  TBOX
 SG_ vcu_mcuf0OverTemperature : 15|1@1+ (1,0) [0|1] ""  IVI,TBOX
 SG_ vcu_mcur0OverTemperature : 16|1@1+ (1,0) [0|1] ""  IVI,TBOX
 SG_ vcu_hvilFault : 17|1@1+ (1,0) [0|1] ""  TBOX
 SG_ vcu_mcuf0MotorOverTemperature : 18|1@1+ (1,0) [0|1] ""  IVI,TBOX
 SG_ vcu_mcur0MotorOverTemperature : 19|1@1+ (1,0) [0|1] ""  IVI,TBOX
 SG_ vcu_batteryOverCharge : 20|1@1+ (1,0) [0|1] ""  TBOX

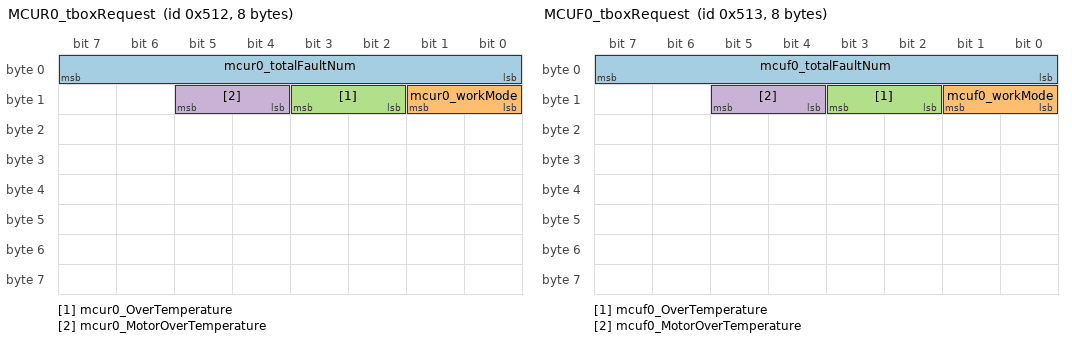
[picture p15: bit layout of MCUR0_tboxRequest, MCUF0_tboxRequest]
BO_ 1298 MCUR0_tboxRequest: 8 GW
 SG_ mcur0_totalFaultNum : 0|8@1+ (1,0) [0|255] ""  TBOX
 SG_ mcur0_workMode : 8|2@1+ (1,0) [0|3] ""  TBOX
 SG_ mcur0_OverTemperature : 10|2@1+ (1,0) [0|3] ""  TBOX
 SG_ mcur0_MotorOverTemperature : 12|2@1+ (1,0) [0|3] ""  TBOX

BO_ 1299 MCUF0_tboxRequest: 8 GW
 SG_ mcuf0_totalFaultNum : 0|8@1+ (1,0) [0|255] ""  TBOX
 SG_ mcuf0_workMode : 8|2@1+ (1,0) [0|3] ""  TBOX
 SG_ mcuf0_OverTemperature : 10|2@1+ (1,0) [0|3] ""  TBOX
 SG_ mcuf0_MotorOverTemperature : 12|2@1+ (1,0) [0|3] ""  TBOX

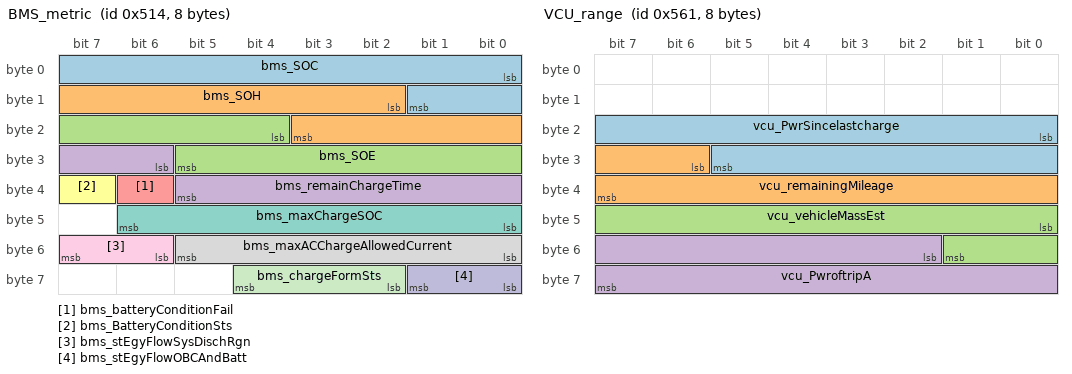
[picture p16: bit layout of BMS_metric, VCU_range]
BO_ 1300 BMS_metric: 8 GW
 SG_ bms_SOC : 0|10@1+ (0.1,0) [0|100] "%"  IVI,TBOX
 SG_ bms_SOH : 10|10@1+ (0.1,0) [0|100] "%"  IVI,TBOX
 SG_ bms_SOE : 20|10@1+ (0.1,0) [0|100] "%"  IVI,TBOX
 SG_ bms_remainChargeTime : 30|8@1+ (0.1,0) [0|20] "hr"  IVI,TBOX
 SG_ bms_batteryConditionFail : 38|1@1+ (1,0) [0|1] ""  IVI,TBOX
 SG_ bms_BatteryConditionSts : 39|1@1+ (1,0) [0|1] ""  IVI,TBOX
 SG_ bms_maxChargeSOC : 40|7@1+ (1,0) [0|100] ""  IVI,TBOX
 SG_ bms_maxACChargeAllowedCurrent : 48|6@1+ (1,5) [5|67] "A"  IVI,TBOX
 SG_ bms_stEgyFlowSysDischRgn : 54|2@1+ (1,0) [0|3] ""  IVI,TBOX
 SG_ bms_stEgyFlowOBCAndBatt : 56|2@1+ (1,0) [0|3] ""  IVI,TBOX
 SG_ bms_chargeFormSts : 58|3@1+ (1,0) [0|7] ""  IVI,TBOX

BO_ 1377 VCU_range: 8 GW
 SG_ vcu_PwrSincelastcharge : 16|14@1+ (0.1,-500) [-500|1000] "kWh"  IVI
 SG_ vcu_remainingMileage : 30|10@1+ (1,0) [0|1023] "km"  IVI,TBOX
 SG_ vcu_vehicleMassEst : 40|10@1+ (5,1300) [1300|5000] "kg"  IVI
 SG_ vcu_PwroftripA : 50|14@1+ (0.1,-500) [-500|1000] "kWh"  IVI

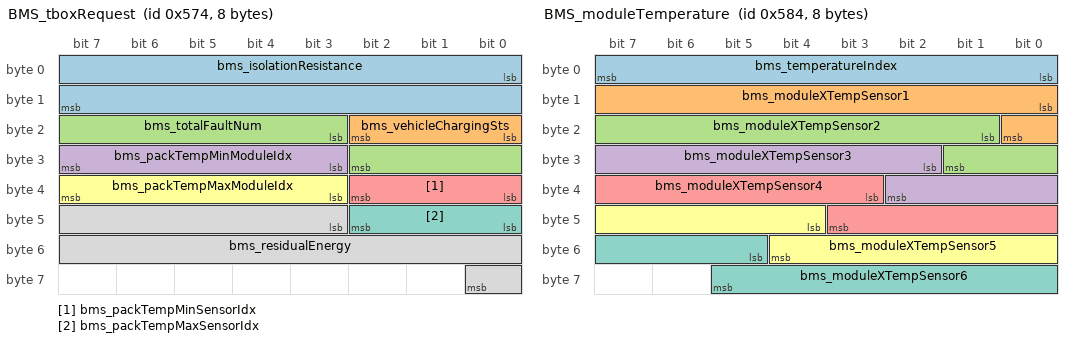
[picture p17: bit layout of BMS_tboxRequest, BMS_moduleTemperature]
BO_ 1396 BMS_tboxRequest: 8 GW
 SG_ bms_isolationResistance : 0|16@1+ (1,0) [0|60000] "kOhm"  TBOX
 SG_ bms_vehicleChargingSts : 16|3@1+ (1,0) [0|7] ""  TBOX
 SG_ bms_totalFaultNum : 19|8@1+ (1,0) [0|255] ""  TBOX
 SG_ bms_packTempMinModuleIdx : 27|5@1+ (1,0) [0|31] ""  TBOX
 SG_ bms_packTempMinSensorIdx : 32|3@1+ (1,0) [0|7] ""  TBOX
 SG_ bms_packTempMaxModuleIdx : 35|5@1+ (1,0) [0|31] ""  TBOX
 SG_ bms_packTempMaxSensorIdx : 40|3@1+ (1,0) [0|7] ""  TBOX
 SG_ bms_residualEnergy : 43|14@1+ (0.01,0) [0|100] "kWh"  TBOX

BO_ 1412 BMS_moduleTemperature: 8 GW
 SG_ bms_temperatureIndex : 0|8@1+ (1,0) [0|255] ""  TBOX
 SG_ bms_moduleXTempSensor1 : 8|9@1+ (0.5,-40) [-40|215] "℃"  TBOX
 SG_ bms_moduleXTempSensor2 : 17|9@1+ (0.5,-40) [-40|215] "℃"  TBOX
 SG_ bms_moduleXTempSensor3 : 26|9@1+ (0.5,-40) [-40|215] "℃"  TBOX
 SG_ bms_moduleXTempSensor4 : 35|9@1+ (0.5,-40) [-40|215] "℃"  TBOX
 SG_ bms_moduleXTempSensor5 : 44|9@1+ (0.5,-40) [-40|215] "℃"  TBOX
 SG_ bms_moduleXTempSensor6 : 53|9@1+ (0.5,-40) [-40|215] "℃"  TBOX

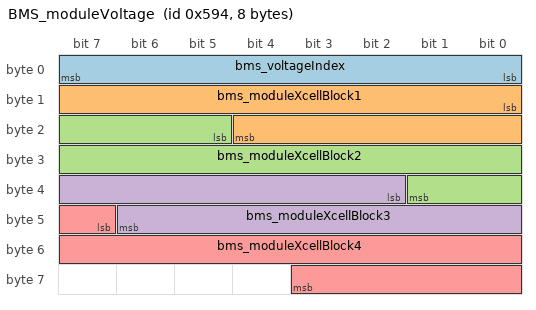
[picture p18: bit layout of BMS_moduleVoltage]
BO_ 1428 BMS_moduleVoltage: 8 GW
 SG_ bms_voltageIndex : 0|8@1+ (1,0) [0|255] ""  TBOX
 SG_ bms_moduleXcellBlock1 : 8|13@1+ (0.001,0) [0|5] "V"  TBOX
 SG_ bms_moduleXcellBlock2 : 21|13@1+ (0.001,0) [0|5] "V"  TBOX
 SG_ bms_moduleXcellBlock3 : 34|13@1+ (0.001,0) [0|5] "V"  TBOX
 SG_ bms_moduleXcellBlock4 : 47|13@1+ (0.001,0) [0|5] "V"  TBOX

BO_ 254 BMS1: 8 GW
 SG_ bms_DcChgEnergy : 0|11@1+ (0.1,0) [0|200] "kwh"  TBOX

BO_ 1566 NM_GW_INFO: 8 GW
 SG_ GW_INFO_RMR : 8|1@1+ (1,0) [0|1] ""  AMP,ETC,ICM,IVI,TBOX
 SG_ GW_INFO_AWB : 12|1@1+ (1,0) [0|1] ""  AMP,ETC,ICM,IVI,TBOX

BO_ 1832 Diag_PhyReq_TBOX: 8 GW
 SG_ Diag_PhyReq_TBOX_Data : 0|64@1+ (1,0) [0|0] "N/A"  TBOX

BO_ 1921 Diag_Resp_BCM: 8 GW
 SG_ Diag_Resp_BCM_Data : 0|64@1+ (1,0) [0|0] "N/A"  TBOX

CM_ SG_ 801 vcu_w000_accelPedalMismatch "w000_Accelerator pedal mismatch.";
CM_ SG_ 801 vcu_f000_accelPedalMismatch "f000_Accelerator pedal mismatch.";
CM_ SG_ 801 vcu_w001_ptOverTemp "w001_pt over temperature.";
CM_ SG_ 801 vcu_f001_ptOverTemp "f001_pt over temperature.";
CM_ SG_ 801 vcu_w002_vacuumSensorError "w002_Vacuum sensor error.";
CM_ SG_ 801 vcu_f002_vacuumSensorError "f002_Vacuum sensor error.";
CM_ SG_ 801 vcu_w003_accelPedalOutRange "w003_Accelerator pedal out range.";
CM_ SG_ 801 vcu_f003_accelPedalOutRange "f003_Accelerator pedal out range.";
CM_ SG_ 801 vcu_w004_waterPumpError "w004_Water pumperror.";
CM_ SG_ 801 vcu_f004_waterPumpError "f004_Water pumperror.";
CM_ SG_ 801 vcu_w009_limpMode "w009_Limp mode.";
CM_ SG_ 801 vcu_f009_limpMode "f009_Limp mode.";
CM_ SG_ 801 vcu_w010_gpoMode "w010_gpo mode.";
CM_ SG_ 801 vcu_f010_gpoMode "f010_gpoMode.";
CM_ SG_ 801 vcu_w011_hardFault "w011_Hard fault.";
CM_ SG_ 801 vcu_f011_hardFault "f011_Hard fault.";
CM_ SG_ 801 vcu_w012_bmsMia "w012_BMS Mia.";
CM_ SG_ 801 vcu_f012_bmsMia "f012_BMS Mia.";
CM_ SG_ 801 vcu_w013_mcuf0Mia "w013_MCUF0 Mia.";
CM_ SG_ 801 vcu_f013_mcuf0Mia "f013_MCUF0 Mia.";
CM_ SG_ 801 vcu_w014_mcur0Mia "w014_MCUR0 Mia";
CM_ SG_ 801 vcu_f014_mcur0Mia "f014_MCUR0 Mia";
CM_ SG_ 801 vcu_w015_mcuf1Mia "w015_MCUF1 Mia";
CM_ SG_ 801 vcu_f015_mcuf1Mia "f015_MCUF1 Mia";
CM_ SG_ 801 vcu_w016_mcur1Mia "w016_MCUR1 Mia";
CM_ SG_ 801 vcu_f016_mcur1Mia "f016_MCUR1 Mia";
CM_ SG_ 801 vcu_w017_gcuMia "w017_GCU Mia";
CM_ SG_ 801 vcu_f017_gcuMia "f017_GCU Mia";
CM_ SG_ 801 vcu_w018_escMia "w018_ESC Mia";
CM_ SG_ 801 vcu_f018_escMia "f018_ESC Mia";
CM_ SG_ 801 vcu_w019_dcdcOverTemp "w019_DCDC over temperature.";
CM_ SG_ 801 vcu_f019_dcdcOverTemp "f019_DCDC over temperature.";
CM_ SG_ 801 vcu_w020_obcOverTemp "w020_OBC over temperature.";
CM_ SG_ 801 vcu_f020_obcOverTemp "f020_OBC over temperature.";
CM_ SG_ 801 vcu_w021_lostCommCoolantLevel "w021_Lost communication coolant level.";
CM_ SG_ 801 vcu_f021_lostCommCoolantLevel "f021_Lost communication coolant level.";
CM_ SG_ 801 vcu_w022_threeWayValveFault "w022_Three way valve fault.";
CM_ SG_ 801 vcu_f022_threeWayValveFault "f022_Three way valve fault.";
CM_ SG_ 801 vcu_w023_fourWayValveFault "w023_Four way valve fault.";
CM_ SG_ 801 vcu_f023_fourWayValveFault "f023_Four way valve fault.";
CM_ SG_ 801 vcu_w024_battPtcFault "w024_Battery PTC fault.";
CM_ SG_ 801 vcu_f024_battPtcFault "f024_Battery PTC fault.";
CM_ SG_ 801 vcu_w025_acCompressorFault "w025_AC compressor  fault.";
CM_ SG_ 801 vcu_f025_acCompressorFault "f025_AC compressor  fault.";
CM_ SG_ 801 vcu_w026_agsFault "w026_ags fault.";
CM_ SG_ 801 vcu_f026_agsFault "f026_ags fault.";
CM_ SG_ 801 vcu_w027_battExvFault "w027_Battery electronic expansion valve   fault.";
CM_ SG_ 801 vcu_f027_battExvFault "f027_Battery electronic expansion valve   fault.";
CM_ SG_ 801 vcu_w028_acExvFault "w028_AC electronic expansion valve   fault.";
CM_ SG_ 801 vcu_f028_acExvFault "f028_AC electronic expansion valve   fault.";
CM_ SG_ 801 vcu_w029_coolantLevelLow "Warning for coolant level low.";
CM_ SG_ 801 vcu_f029_coolantLevelLow "Fault for coolant level low.";
CM_ SG_ 802 mcur0_w000_overVoltage "w000_over voltage.";
CM_ SG_ 802 mcur0_f000_overVoltage "f000_over voltage.";
CM_ SG_ 802 mcur0_w001_overSpeed "w001_over speed.";
CM_ SG_ 802 mcur0_f001_overSpeed "f001_over speed.";
CM_ SG_ 802 mcur0_w002_overCurrentPhA "w002_over  Current PhA.";
CM_ SG_ 802 mcur0_f002_overCurrentPhA "f002_over Current PhA.";
CM_ SG_ 802 mcur0_w003_overCurrentPhB "w003_over Current PhB.";
CM_ SG_ 802 mcur0_f003_overCurrentPhB "f003_over Current PhB.";
CM_ SG_ 802 mcur0_w004_overCurrentPhC "w004_over Current PhC.";
CM_ SG_ 802 mcur0_f004_overCurrentPhC "f004_over Current PhC.";
CM_ SG_ 802 mcur0_w005_canError "w005_can Error.";
CM_ SG_ 802 mcur0_f005_canError "f005_can Error.";
CM_ SG_ 802 mcur0_w006_noCurrentPhA "w006_ Current PhA no fault.";
CM_ SG_ 802 mcur0_f006_noCurrentPhA "f006_Current PhA no fault.";
CM_ SG_ 802 mcur0_w007_noCurrentPhB "w007_Current PhB no fault.";
CM_ SG_ 802 mcur0_f007_noCurrentPhB "f007_Current PhB no fault.";
CM_ SG_ 802 mcur0_w008_noCurrentPhC "w008_Current PhC no fault.";
CM_ SG_ 802 mcur0_f008_noCurrentPhC "f008_Current PhC no fault.";
CM_ SG_ 802 mcur0_w009_taskOverrun100Hz "w009_task Overrun100Hz.";
CM_ SG_ 802 mcur0_f009_taskOverrun100Hz "f009_task Overrun100Hz.";
CM_ SG_ 802 mcur0_w010_taskOverrun10Hz "w010_task Overrun10Hz.";
CM_ SG_ 802 mcur0_f010_taskOverrun10Hz "f010_task Overrun10Hz.";
CM_ SG_ 802 mcur0_w011_PhATopDsatFaltSta "w011_igbt PhA Top Dsat Falt Status.";
CM_ SG_ 802 mcur0_f011_PhATopDsatFaltSta "f011_igbt PhA Top Dsat Falt Status.";
CM_ SG_ 802 mcur0_w012_PhBTopDsatFaltSta "w012_igbt PhB Top Dsat Falt Status.";
CM_ SG_ 802 mcur0_f012_PhBTopDsatFaltSta "f012_igbt PhB Top Dsat Falt Status.";
CM_ SG_ 802 mcur0_w013_PhCTopDsatFaltSta "w013_igbt PhC Top Dsat Falt Status.";
CM_ SG_ 802 mcur0_f013_PhCTopDsatFaltSta "f013_igbt PhC Top Dsat Falt  Status.";
CM_ SG_ 802 mcur0_w014_PhABotDsatFaltSta "w014_igbt PhA Bot Dsat Falt Status.";
CM_ SG_ 802 mcur0_f014_PhABotDsatFaltSta "f014_igbt PhA Bot Dsat Falt Status.";
CM_ SG_ 802 mcur0_w015_PhBBotDsatFaltSta "w015_igbt PhB Bot Dsat Falt Status.";
CM_ SG_ 802 mcur0_f015_PhBBotDsatFaltSta "f015_igbt PhB Bot Dsat Falt Status.";
CM_ SG_ 802 mcur0_w016_PhCBotDsatFaltSta "w016_igbt PhC Bot Dsat Falt  Status.";
CM_ SG_ 802 mcur0_f016_PhCBotDsatFaltSta "f016_igbt PhC Bot Dsat Falt Status.";
CM_ SG_ 802 mcur0_w017_underVoltage "w017_under Voltage.";
CM_ SG_ 802 mcur0_f017_underVoltage "f017_under Voltage.";
CM_ SG_ 802 mcur0_w018_overTemperature "w018_over Temperature.";
CM_ SG_ 802 mcur0_f018_overTemperature "f018_over Temperature.";
CM_ SG_ 802 mcur0_w019_underTemperature "w019_under Temperature.";
CM_ SG_ 802 mcur0_f019_underTemperature "f019_under Temperature.";
CM_ SG_ 802 mcur0_w020_controllerOverTemp "w020_controller Over Temperature.";
CM_ SG_ 802 mcur0_f020_controllerOverTemp "f020_controller Over Temperature.";
CM_ SG_ 802 mcur0_w021_adcOverRun "w021_adc Over Run.";
CM_ SG_ 802 mcur0_f021_adcOverRun "f021_adc Over Run";
CM_ SG_ 802 mcur0_w022_HwOverCurrentPh "w022_hardware  Over Current PhA.";
CM_ SG_ 802 mcur0_f022_HwOverCurrentPh "f022_hardware OverCurrentPhA.";
CM_ SG_ 802 mcur0_w023_HwOverCurrentPh "w023_hardware OverCurrentPhB.";
CM_ SG_ 802 mcur0_f023_HwOverCurrentPh "f023_hardware OverCurrentPhB.";
CM_ SG_ 802 mcur0_w024_HwOverCurrentPh "w024_hardware OverCurrentPhC.";
CM_ SG_ 802 mcur0_f024_HwOverCurrentPh "f024_hardware Over Current PhC.";
CM_ SG_ 802 mcur0_w025_hardwareOverVoltage "w025_hardware Over Voltage.";
CM_ SG_ 802 mcur0_f025_hardwareOverVoltage "f025_hardware Over Voltage.";
CM_ SG_ 802 mcur0_w026_hardwareDsatFault "w026_hardware Dsat Fault.";
CM_ SG_ 802 mcur0_f026_hardwareDsatFault "f026_hardware Dsat Fault.";
CM_ SG_ 802 mcur0_w027_curSenOffsetOutOfR "Warning for rear MCUR0 current sensor offset out of range";
CM_ SG_ 802 mcur0_f027_curSenOffsetOutOfR "Fault for rear MCUR0 current sensor offset out of range";
CM_ SG_ 803 mcuf0_w000_overVoltage "w000_over voltage.";
CM_ SG_ 803 mcuf0_f000_overVoltage "f000_over voltage.";
CM_ SG_ 803 mcuf0_w001_overSpeed "w001_over speed.";
CM_ SG_ 803 mcuf0_f001_overSpeed "f001_over speed.";
CM_ SG_ 803 mcuf0_w002_overCurrentPhA "w002_over  Current PhA.";
CM_ SG_ 803 mcuf0_f002_overCurrentPhA "f002_over Current PhA.";
CM_ SG_ 803 mcuf0_w003_overCurrentPhB "w003_over Current PhB.";
CM_ SG_ 803 mcuf0_f003_overCurrentPhB "f003_over Current PhB.";
CM_ SG_ 803 mcuf0_w004_overCurrentPhC "w004_over Current PhC.";
CM_ SG_ 803 mcuf0_f004_overCurrentPhC "f004_over Current PhC.";
CM_ SG_ 803 mcuf0_w005_canError "w005_can Error.";
CM_ SG_ 803 mcuf0_f005_canError "f005_can Error.";
CM_ SG_ 803 mcuf0_w006_noCurrentPhA "w006_ Current PhA no fault.";
CM_ SG_ 803 mcuf0_f006_noCurrentPhA "f006_Current PhA no fault.";
CM_ SG_ 803 mcuf0_w007_noCurrentPhB "w007_Current PhB no fault.";
CM_ SG_ 803 mcuf0_f007_noCurrentPhB "f007_Current PhB no fault.";
CM_ SG_ 803 mcuf0_w008_noCurrentPhC "w008_Current PhC no fault.";
CM_ SG_ 803 mcuf0_f008_noCurrentPhC "f008_Current PhC no fault.";
CM_ SG_ 803 mcuf0_w009_taskOverrun100Hz "w009_task Overrun100Hz.";
CM_ SG_ 803 mcuf0_f009_taskOverrun100Hz "f009_task Overrun100Hz.";
CM_ SG_ 803 mcuf0_w010_taskOverrun10Hz "w010_task Overrun10Hz.";
CM_ SG_ 803 mcuf0_f010_taskOverrun10Hz "f010_task Overrun10Hz.";
CM_ SG_ 803 mcuf0_w011_PhATopDsatFaltSts "w011_igbt PhA Top Dsat Falt Status.";
CM_ SG_ 803 mcuf0_f011_PhATopDsatFaltSts "f011_igbt PhA Top Dsat Falt Status.";
CM_ SG_ 803 mcuf0_w012_PhBTopDsatFaltSts "w012_igbt PhB Top Dsat Falt Status.";
CM_ SG_ 803 mcuf0_f012_PhBTopDsatFaltSts "f012_igbt PhB Top Dsat Falt Status.";
CM_ SG_ 803 mcuf0_w013_PhCTopDsatFaltSts "w013_igbt PhC Top Dsat Falt Status.";
CM_ SG_ 803 mcuf0_f013_PhCTopDsatFaltSts "f013_igbt PhC Top Dsat Falt  Status.";
CM_ SG_ 803 mcuf0_w014_PhABotDsatFaltSts "w014_igbt PhA Bot Dsat Falt Status.";
CM_ SG_ 803 mcuf0_f014_PhABotDsatFaltSts "f014_igbt PhA Bot Dsat Falt Status.";
CM_ SG_ 803 mcuf0_w015_PhBBotDsatFaltSts "w015_igbt PhB Bot Dsat Falt Status.";
CM_ SG_ 803 mcuf0_f015_PhBBotDsatFaltSts "f015_igbt PhB Bot Dsat Falt Status.";
CM_ SG_ 803 mcuf0_w016_PhCBotDsatFaltSts "w016_igbt PhC Bot Dsat Falt  Status.";
CM_ SG_ 803 mcuf0_f016_PhCBotDsatFaltSts "f016_igbt PhC Bot Dsat Falt Status.";
CM_ SG_ 803 mcuf0_w017_underVoltage "w017_under Voltage.";
CM_ SG_ 803 mcuf0_f017_underVoltage "f017_under Voltage.";
CM_ SG_ 803 mcuf0_w018_overTemperature "w018_over Temperature.";
CM_ SG_ 803 mcuf0_f018_overTemperature "f018_over Temperature.";
CM_ SG_ 803 mcuf0_w019_underTemperature "w019_under Temperature.";
CM_ SG_ 803 mcuf0_f019_underTemperature "f019_under Temperature.";
CM_ SG_ 803 mcuf0_w020_controllerOverTemp "w020_controller Over Temperature.";
CM_ SG_ 803 mcuf0_f020_controllerOverTemp "f020_controller Over Temperature.";
CM_ SG_ 803 mcuf0_w021_adcOverRun "w021_adc Over Run.";
CM_ SG_ 803 mcuf0_f021_adcOverRun "f021_adc Over Run";
CM_ SG_ 803 mcuf0_w022_hdOverCurrentPhA "w022_hardware  Over Current PhA.";
CM_ SG_ 803 mcuf0_f022_hdOverCurrentPhA "f022_hardware OverCurrentPhA.";
CM_ SG_ 803 mcuf0_w023_hdOverCurrentPhB "w023_hardware OverCurrentPhB.";
CM_ SG_ 803 mcuf0_f023_hdOverCurrentPhB "f023_hardware OverCurrentPhB.";
CM_ SG_ 803 mcuf0_w024_hdOverCurrentPhC "w024_hardware OverCurrentPhC.";
CM_ SG_ 803 mcuf0_f024_hdOverCurrentPhC "f024_hardware Over Current PhC.";
CM_ SG_ 803 mcuf0_w025_hardwareOverVoltage "w025_hardware Over Voltage.";
CM_ SG_ 803 mcuf0_f025_hardwareOverVoltage "f025_hardware Over Voltage.";
CM_ SG_ 803 mcuf0_w026_hardwareDsatFault "w026_hardware Dsat Fault.";
CM_ SG_ 803 mcuf0_f026_hardwareDsatFault "f026_hardware Dsat Fault.";
CM_ SG_ 803 mcuf0_w027_curSenOffsetOutOfR "Warning for rear MCUF0 current sensor offset out of range.";
CM_ SG_ 803 mcuf0_f027_curSenOffsetOutOfR "Fault for rear MCUF0 current sensor offset out of range.";
CM_ SG_ 804 bms_w000_packUnderVoltage "Warning for battery pack under voltage.";
CM_ SG_ 804 bms_f000_packUnderVoltage "fault for battery pack under voltage.";
CM_ SG_ 804 bms_w001_packOverVoltage "Warning for  battery pack over voltage.";
CM_ SG_ 804 bms_f001_packOverVoltage "fault for  battery pack over voltage.";
CM_ SG_ 804 bms_w002_packOverCrntDischg "Warning for battery pack discharge over current.";
CM_ SG_ 804 bms_f002_packOverCrntDischg "fault for battery pack discharge over current.";
CM_ SG_ 804 bms_w003_packOverCrntChg "Warning for battery pack charge over current .";
CM_ SG_ 804 bms_f003_packOverCrntChg "fault for battery pack charge over current .";
CM_ SG_ 804 bms_w004_cellUnderVoltage "Warning for battery cell under voltage.";
CM_ SG_ 804 bms_f004_cellUnderVoltage "fault for battery cell under voltage.";
CM_ SG_ 804 bms_w005_cellOverVoltage "Warning for battery cell over voltage.";
CM_ SG_ 804 bms_f005_cellOverVoltage "fault for battery cell over voltage.";
CM_ SG_ 804 bms_w006_cellUnderTemp "Warning for battery cell under temperature.";
CM_ SG_ 804 bms_f006_cellUnderTemp "fault for battery cell under temperature.";
CM_ SG_ 804 bms_w007_cellOverTemp "Warning for battery cell over temperature.";
CM_ SG_ 804 bms_f007_cellOverTemp "fault for battery cell over temperature.";
CM_ SG_ 804 bms_w008_contactorPosMainHSFlt "Warining for positive main contactor high-side MOSFET.";
CM_ SG_ 804 bms_f008_contactorPosMainHSFlt "Warining for positive main contactor high-side MOSFET.";
CM_ SG_ 804 bms_w009_contactorPosMainLSFlt "Warning for positive main contactor low-side MOSFET.";
CM_ SG_ 804 bms_f009_contactorPosMainLSFlt "fault for positive main contactor low-side MOSFET.";
CM_ SG_ 804 bms_w010_contactorNegMainHSFlt "Warning for negative main contactor high-side MOSFET.";
CM_ SG_ 804 bms_f010_contactorNegMainHSFlt "fault for negative main contactor high-side MOSFET.";
CM_ SG_ 804 bms_w011_contactorNegMainLSFlt "Warning for negative main contactor low-side MOSFET.";
CM_ SG_ 804 bms_f011_contactorNegMainLSFlt "fault for negative main contactor low-side MOSFET.";
CM_ SG_ 804 bms_w012_contactorPrechgHSFault "Warning for precharge contactor high-side MOSFET.";
CM_ SG_ 804 bms_f012_contactorPrechgHSFault "fault for precharge contactor high-side MOSFET.";
CM_ SG_ 804 bms_w013_contactorPrechgLSFault "Warning for precharge contactor low-side MOSFET.";
CM_ SG_ 804 bms_f013_contactorPrechgLSFault "fault for precharge contactor low-side MOSFET.";
CM_ SG_ 804 bms_w014_acChargingRelayFault "Warning for AC charge relay.";
CM_ SG_ 804 bms_f014_acChargingRelayFault "fault for AC charge relay.";
CM_ SG_ 804 bms_w015_dcChargingRelayFault "Warning for DC charge high side relay.";
CM_ SG_ 804 bms_f015_dcChargingRelayFault "fault for DC charge high side relay.";
CM_ SG_ 804 bms_w016_currentSensorFailure "Warning for current sensor fail.";
CM_ SG_ 804 bms_f016_currentSensorFailure "fault for current sensor fail.";
CM_ SG_ 804 bms_w017_cellImbalanceDischrg "Warning for cell imbalance during discharge.";
CM_ SG_ 804 bms_f017_cellImbalanceDischrg "fault for cell imbalance during discharge.";
CM_ SG_ 804 bms_w018_prechargeFailure "Warning for precharge.";
CM_ SG_ 804 bms_f018_prechargeFailure "fault for precharge.";
CM_ SG_ 804 bms_w019_bmuCommFailure "Warning for BMU communication.";
CM_ SG_ 804 bms_f019_bmuCommFailure "fault for BMU communication.";
CM_ SG_ 804 bms_w020_isolationFault "Warining for isolation detection.";
CM_ SG_ 804 bms_f020_isolationFault "Warining for isolation detection.";
CM_ SG_ 804 bms_w021_coolantInletOverTemp "Warining for battery pack inlet coolant temperature over temperature.";
CM_ SG_ 804 bms_f021_coolantInletOverTemp "Warining for battery pack inlet coolant temperature over temperature.";
CM_ SG_ 804 bms_w022_coolantOutletOverTemp "Warining for battery pack outlet coolant temperature over temperature.";
CM_ SG_ 804 bms_f022_coolantOutletOverTemp "Warining for battery pack outlet coolant temperature over temperature.";
CM_ SG_ 804 bms_w023_prechargeTimeout "Warining for precharge voltage mismatch.";
CM_ SG_ 804 bms_f023_prechargeTimeout "Warining for precharge voltage mismatch.";
CM_ SG_ 804 bms_w024_powerDeratingSoc "Warining for battery pack low SOC.";
CM_ SG_ 804 bms_f024_powerDeratingSoc "Warining for battery pack low SOC.";
CM_ SG_ 804 bms_w025_noPowerDeliverySoc "Warining for battery pack extreme low SOC.";
CM_ SG_ 804 bms_f025_noPowerDeliverySoc "Warining for battery pack extreme low SOC.";
CM_ SG_ 804 bms_w026_dcLSContactorFail "Warning for DC charge low side relay.";
CM_ SG_ 804 bms_f026_dcLSContactorFail "fault for DC charge low side relay.";
CM_ SG_ 804 bms_w027_hvilOpen "Warning for HVIL open circuit.";
CM_ SG_ 804 bms_f027_hvilOpen "fault for HVIL open circuit.";
CM_ SG_ 804 bms_w028_lostCommsVCU "Warning for BMS loss communication with VCU.";
CM_ SG_ 804 bms_f028_lostCommsVCU "fault for BMS loss communication with VCU.";
CM_ SG_ 804 bms_w029_lostCommsOBC "Warning for BMS loss communication with OBC.";
CM_ SG_ 804 bms_f029_lostCommsOBC "fault for BMS loss communication with OBC.";
CM_ SG_ 804 bms_w030_batteryProtectionSoc "Warning for BMS system failure.";
CM_ SG_ 804 bms_f030_batteryProtectionSoc "fault for BMS system failure.";
CM_ SG_ 804 bms_w031_cellTempImbalDischrg "Warning for battery cell temperature unbalance.";
CM_ SG_ 804 bms_f031_cellTempImbalDischrg "fault for battery cell temperature unbalance.";
CM_ SG_ 816 vcu_Rev_VcuV2VModeFb "V2V mode feed back.";
CM_ SG_ 816 vcu_v2vChrgAllow "V2V charging allows flag.";
CM_ SG_ 816 vcu_v2vChrgOptVoltg "V2V charging output voltage.";
CM_ SG_ 816 vcu_v2vChrgOptCurnt "V2V charging output current.";
CM_ SG_ 816 vcu_StartRevSOC "Start recovery SOC.";
CM_ SG_ 816 vcu_remainingMileageReal "纯电续驶里程";
CM_ SG_ 817 vcu_Rev_VehicleHVpower "Power consumption value of high voltage accessories during charging.";
CM_ SG_ 817 vcu_Rev_BmstempInletCoolant "BMS temperature Inlet Coolant.";
CM_ SG_ 817 vcu_Rev_BmstempOutletCoolant "BMS temperature Outlet Coolant.";
CM_ SG_ 817 vcu_stEgyFlowGenMotAndBatt "State of energy flow for Generator motor and Battery.";
CM_ SG_ 817 vcu_stEgyFlowEngAndGenMot "State of energy flow for Generator motor and engine.";
CM_ SG_ 817 vcu_dcPrehtChrgRlyAlwOpn "DC preheat charging relay allow open.";
CM_ SG_ 817 vcu_obcDschrgAllow "OBC discharging allows flag.";
CM_ SG_ 817 vcu_v2vChrgFdbk "V2V charging feedback flag.";
CM_ SG_ 817 vcu_obcDschrgFdbk "OBC discharging feedback flag.";
CM_ SG_ 817 vcu_v2vChrgOutCurntFdbk "V2V charging output current feedback.";
CM_ SG_ 817 VCU_MaxFuelConsumptionSt "Maximum fuel consumption status.";
CM_ SG_ 817 VCU_MaxFuelConsumptionModeSt "Maximum fuel consumption mode status.";
CM_ SG_ 817 vcu_RangeExtenderNoSt "Range Extender Not Start                
增程器 未启动";
CM_ SG_ 820 bms_w032_highSOC "Warning for high battery pack SOC.";
CM_ SG_ 820 bms_f032_highSOC "fault for high battery pack SOC.";
CM_ SG_ 820 bms_w033_lostCommsIVTS "Warning for loss communication with IVTS sensor.";
CM_ SG_ 820 bms_f033_lostCommsIVTS "fault for loss communication with IVTS sensor.";
CM_ SG_ 820 bms_w034_socStepChange "Warning for battery pack SOC step change.";
CM_ SG_ 820 bms_f034_socStepChange "fault for battery pack SOC step change.";
CM_ SG_ 820 bms_w035_bmuNoResponse "Warning for BMU not respond to BMS commands.";
CM_ SG_ 820 bms_f035_bmuNoResponse "fault for BMU not respond to BMS commands.";
CM_ SG_ 820 bms_w036_bmuHarnessBroken "Warning for BMU harness broken.";
CM_ SG_ 820 bms_f036_bmuHarnessBroken "fault for BMU harness broken.";
CM_ SG_ 820 bms_w037_cellVoltImbalanceChrg "Warning for cell voltage imbalance during charging.";
CM_ SG_ 820 bms_f037_cellVoltImbalanceChrg "fault for cell voltage imbalance during charging.";
CM_ SG_ 820 bms_w038_cellTempImbalanceChrg "Warning for cell temperature imbalance during charging.";
CM_ SG_ 820 bms_f038_cellTempImbalanceChrg "fault for cell temperature imbalance during charging.";
CM_ SG_ 820 bms_w039_cellVoltSnrDisconnect "Warining for cell voltage sensor disconnection.";
CM_ SG_ 820 bms_f039_cellVoltSnrDisconnect "Warining for cell voltage sensor disconnection.";
CM_ SG_ 820 bms_w040_cellThermistorDiscon "Warning for battery module thermistor disconnection.";
CM_ SG_ 820 bms_f040_cellThermistorDiscon "fault for battery module thermistor disconnection.";
CM_ SG_ 820 bms_w041_posMainConStuckOpen "Warning for positive main contactor stuck OPEN.";
CM_ SG_ 820 bms_f041_posMainConStuckOpen "fault for positive main contactor stuck OPEN.";
CM_ SG_ 820 bms_w042_posMainContactorWelded "Warining for positive main contactor welded.";
CM_ SG_ 820 bms_f042_posMainContactorWelded "Warining for positive main contactor welded.";
CM_ SG_ 820 bms_w043_negMainConStuckOpen "Warning for negative main contactor stuck OPEN.";
CM_ SG_ 820 bms_f043_negMainConStuckOpen "fault for negative main contactor stuck OPEN.";
CM_ SG_ 820 bms_w044_negMainContactorWelded "Warning for negative contactor welded.";
CM_ SG_ 820 bms_f044_negMainContactorWelded "fault for negative contactor welded.";
CM_ SG_ 820 bms_w045_prechrgConStuckOpen "Warning for precharge contactor stuck OPEN.";
CM_ SG_ 820 bms_f045_prechrgConStuckOpen "fault for precharge contactor stuck OPEN.";
CM_ SG_ 820 bms_w046_prechrgContactorWelded "Warning for precharge contactor welded.";
CM_ SG_ 820 bms_f046_prechrgContactorWelded "fault for precharge contactor welded.";
CM_ SG_ 820 bms_w047_packOverTemp "Warning for nattery pack over temperature.";
CM_ SG_ 820 bms_f047_packOverTemp "fault for nattery pack over temperature.";
CM_ SG_ 820 bms_w048_packUnderTemp "warning for battery pack under temperature.";
CM_ SG_ 820 bms_f048_packUnderTemp "fault for battery pack under temperature.";
CM_ SG_ 820 bms_w049_coolantInletSnrDiscon "Warining for inlet coolant temperature sensor disconnection.";
CM_ SG_ 820 bms_f049_coolantInletSnrDiscon "Warining for inlet coolant temperature sensor disconnection.";
CM_ SG_ 820 bms_w050_coolantOutletSnrDiscon "Warning for outlet coolant temperature sensor disconnection.";
CM_ SG_ 820 bms_f050_coolantOutletSnrDiscon "fault for outlet coolant temperature sensor disconnection.";
CM_ SG_ 820 bms_w051_obcOverTemp "Warning for OBC over temperature.";
CM_ SG_ 820 bms_f051_obcOverTemp "fault for OBC over temperature.";
CM_ SG_ 820 bms_w052_battPackShortCircuit "Warning for battery pack short circuit.";
CM_ SG_ 820 bms_f052_battPackShortCircuit "fault for battery pack short circuit.";
CM_ SG_ 820 bms_w053_acChrgPortOverTemp "Warning for AC charge port over temperature.";
CM_ SG_ 820 bms_f053_acChrgPortOverTemp "Fault for AC charge port over temperature.";
CM_ SG_ 820 bms_w054_dcChrgPortOverTemp "Warining for DC charge port over temperature.";
CM_ SG_ 820 bms_f054_dcChrgPortOverTemp "Fault for DC charge port over temperature.";
CM_ SG_ 820 bms_w055_dcChrgPortTempRise "Warning for DC charge port temperature increasing.";
CM_ SG_ 820 bms_f055_dcChrgPortTempRise "Fault for DC charge port temperature increasing.";
CM_ SG_ 820 bms_w059_vcuStateMsgMia "Warning for VCU state message missing in action .";
CM_ SG_ 820 bms_f059_vcuStateMsgMia "Fault for VCU state message missing in action .";
CM_ SG_ 820 bms_w062_vcuVehicleMsgMia "Warning for VCU vehicle message missing in action .";
CM_ SG_ 820 bms_f062_vcuVehicleMsgMia "Fault for VCU vehicle message missing in action .";
CM_ SG_ 820 bms_w063_systemFault "Warning for BMS system fault.";
CM_ SG_ 820 bms_f063_systemFault "Fault for BMS system fault.";
CM_ SG_ 823 ECU0_DTCH "ECU0 故障码 H";
CM_ SG_ 823 ECU0_DTCM "ECU0 故障码 M";
CM_ SG_ 823 ECU0_DTCL "ECU0 故障码 L";
CM_ SG_ 823 EMS_DTCAmnt "当前故障码数量";
CM_ SG_ 823 ECU1_DTCH "ECU1 故障码 H";
CM_ SG_ 823 ECU1_DTCM "ECU1 故障码 M";
CM_ SG_ 823 ECU1_DTCL "ECU1 故障码 L";
CM_ SG_ 823 EMS1_DTCAmnt "当前故障码数量";
CM_ SG_ 836 bms_cellBlockVoltMin "cell block voltage minimum.";
CM_ SG_ 836 bms_cellBlockVoltMax "cell block voltage maximum.";
CM_ SG_ 836 bms_cellBlockVoltAvg "cell block voltage average.";
CM_ SG_ 836 bms_moduleVoltMinIndex "module voltage minimum index.";
CM_ SG_ 836 bms_cellBlockVoltMinIndex "cell block voltage minimum index.";
CM_ SG_ 836 bms_moduleVoltMaxIndex "module voltage maximum index.";
CM_ SG_ 836 bms_cellBlockVoltMaxIndex "cell block voltage maximum index.";
CM_ SG_ 841 mrr_obj0_dx "Distance from object 0 in X direction.";
CM_ SG_ 841 mrr_obj0_dy "Distance from object 0 in Y direction.";
CM_ SG_ 841 mrr_obj1_dx "Distance from object 1 in X direction.";
CM_ SG_ 841 mrr_obj1_dy "Distance from object 1 in Y direction.";
CM_ SG_ 841 mrr_obj0_Vx "absolute velocity in X direction from object 0";
CM_ SG_ 841 mrr_obj1_Vx "absolute velocity in X direction from object 1";
CM_ SG_ 841 mrr_obj0_TargetType "object 0 Target Type.";
CM_ SG_ 841 mrr_ACCDetObjSyncCtr1 "ACC determine synchronous control object 1";
CM_ SG_ 841 mrr_obj0_wExist "object 0 Exist.";
CM_ SG_ 841 mrr_obj1_wExist "object 1 Exist .";
CM_ SG_ 841 mrr_obj1_TargetType "object 1 Target Type.";
CM_ SG_ 858 mpc_las_roadCurvature "road Curvature.";
CM_ SG_ 858 mpc_las_LLaneDistance "Distance from vehicle to left lane line";
CM_ SG_ 858 mpc_las_RLaneDistance "Distance from vehicle to right lane line.";
CM_ SG_ 858 mpc_las_LLaneMarkerType "Lane Marker Type of left lane.";
CM_ SG_ 858 mpc_las_RLaneMarkerType "Lane Marker Type of right lane.";
CM_ SG_ 858 mpc_textinfor "TJA/ICA text information for driver.";
CM_ SG_ 858 mpc_LL_Line_Curvature "Curvature of Left left line";
CM_ SG_ 858 mpc_RR_Line_Curvature "Curvature of right right line";
CM_ SG_ 858 mpc_LL_LaneMarkerType "Lane Marker Type of left left line";
CM_ SG_ 858 mpc_RR_LaneMarkerType "Lane Marker Type of right right line";
CM_ SG_ 862 obc_acVoltageInput "AC voltage input.";
CM_ SG_ 862 obc_acCurrentInput "AC current input.";
CM_ SG_ 862 obc_0x487_timeoutFlag "GW信号指示OBC节点在源网段是否超时。
指示以下信号是否超时：
1. obc_acVoltageInput 
2. obc_acCurrentInput";
CM_ SG_ 862 bms_0x354_timeoutFlag "GW信号指示BMS节点在源网段是否超时。
指示以下信号是否超时：
1. bms_v2vChrgConnection";
CM_ SG_ 862 obc_temperature "Temperature .";
CM_ SG_ 862 obc_chargePortTemp1 "Charge port temperature1 .";
CM_ SG_ 862 bms_v2vChrgConnection "V2V charge connection status.";
CM_ SG_ 862 obc_chargePortTemp2 "Charge port temperature2 .";
CM_ SG_ 868 packCode_Index "pack code_index.";
CM_ SG_ 868 packCode1 "pack Code1.";
CM_ SG_ 868 packCode2 "pack Code2.";
CM_ SG_ 868 packCode3 "pack Code3.";
CM_ SG_ 868 packCode4 "pack Code4.";
CM_ SG_ 868 packCode5 "pack Code5.";
CM_ SG_ 868 packCode6 "pack Code6.";
CM_ SG_ 868 packCode7 "pack Code7.";
CM_ SG_ 873 mrr_obj2_dx "Distance from object 2 in X direction.";
CM_ SG_ 873 mrr_obj2_dy "Distance from object 2 in Y direction.";
CM_ SG_ 873 mrr_obj3_dx "Distance from object 3 in X direction.";
CM_ SG_ 873 mrr_obj3_dy "Distance from object 3 in Y direction.";
CM_ SG_ 873 mrr_obj2_Vx "absolute velocity in X direction from object 2";
CM_ SG_ 873 mrr_obj3_Vx "absolute velocity in X direction from object 3";
CM_ SG_ 873 mrr_obj2_TargetType "object 2 Target Type.";
CM_ SG_ 873 mrr_ACCDetObjSyncCtr2 "ACC determine synchronous control object3.";
CM_ SG_ 873 mrr_obj2_wExist "object 2 Exist.";
CM_ SG_ 873 mrr_obj3_wExist "object 3 Exist .";
CM_ SG_ 873 mrr_obj3_TargetType "object 3 Target Type.";
CM_ SG_ 878 eps_0x124_timeoutFlag "GW信号指示EPS节点在源网段是否超时。
指示以下信号是否超时：
1. eps_warningLamp
2. eps_modeSts";
CM_ SG_ 878 iB_0x2A5_timeoutFlag "GW信号指示iB节点在源网段是否超时。
指示以下信号是否超时：
1. iB_hmiWarningOn
2. iB_hmiWarningOn_Q
3. iB_modeSts";
CM_ SG_ 878 eps_warningLamp "EPS warning lamp.";
CM_ SG_ 878 eps_modeSts "EPS mode status.";
CM_ SG_ 878 iB_hmiWarningOn "With this signal iBooster requests the warning lamp  in the dashboard.";
CM_ SG_ 878 iB_hmiWarningOn_Q "Qualifier of iB_hmi Warning On.";
CM_ SG_ 878 iB_modeSts "iB mode Status.";
CM_ SG_ 894 gcu_torqueEst "generate torque.";
CM_ SG_ 894 ecu_engSpeed "engine speed.";
CM_ SG_ 894 gcu_0x10C_timeoutFlag "GW信号指示GCU节点在源网段是否超时。
指示以下信号是否超时：
1. gcu_Speed
2. gcu_SpeedValid";
CM_ SG_ 894 ecu_0x30B_timeoutFlag "GW信号指示ECU节点在源网段是否超时。
指示以下信号是否超时：
BODCAN关联信号：1. ecu_engSpeed
INFOCAN关联信号：1. ecu_engSpeed；2. ecu_engStartSuccess；3. ecu_engSpdErr";
CM_ SG_ 894 ecu_0x31B_timeoutFlag "GW信号指示ECU节点在源网段是否超时。
指示以下信号是否超时：
1. ecu_engCoolantTemp
2. ecu_state";
CM_ SG_ 894 ecu_engCoolantTemp "engine coolant temperature.";
CM_ SG_ 894 ecu_fuelConsump100ms "fuel consumption during 100ms.";
CM_ SG_ 894 ecu_milIndicator "MIL indicator light.";
CM_ SG_ 894 vcu_coolantLevelLow "Coolant level low.";
CM_ SG_ 894 vcu_0x531_timeoutFlag "GW信号指示VCU节点在源网段是否超时。
指示以下信号是否超时：
1. vcu_coolantLevelLow";
CM_ SG_ 894 ecu_state "Engine running status.";
CM_ SG_ 894 ecu_engStartSuccess "Engine starting success indicator (corresponding to ECU internal B_stend variable).";
CM_ SG_ 894 ecu_engSpdErr "Engine speed sensor failure.";
CM_ SG_ 894 ecu_0x39B_timeoutFlag "GW信号指示ECU节点在源网段是否超时。
指示以下信号是否超时：
1. ecu_fuelConsump100ms
2. ecu_milIndicator";
CM_ SG_ 896 acu_warningLampSts "Warning lamp status.";
CM_ SG_ 896 acu_crashOutputStsValid "Crash output statusvalid.";
CM_ SG_ 896 acu_crashOutputSts "Crash output status.";
CM_ SG_ 896 acu_driverSeatBeltSts "Driver seatbelt status.";
CM_ SG_ 896 acu_driverSeatBeltStsValid "Driver seatbelt status vailid.";
CM_ SG_ 896 acu_passengerSeatBeltSts "Passenger seatbelt status.";
CM_ SG_ 896 acu_passengerSeatBeltStsValid "Passenger seatbelt status valid.";
CM_ SG_ 896 acu_passengerAirbagSts "Passenger airbag status(closed or not)";
CM_ SG_ 896 acu_secondLeftSeatBeltSts "Left of second row seatbelt status.";
CM_ SG_ 896 acu_secondMiddleSeatBeltSts "Middle of second row seatbelt status.";
CM_ SG_ 896 acu_secondRightSeatBeltSts "Right of second row seatbelt status.";
CM_ SG_ 896 acu_passengerSts "Passenger seat is occupied or not.";
CM_ SG_ 896 acu_secondLeftSts "Left of second row seat is occupied not.";
CM_ SG_ 896 acu_secondMiddleSts "Middle of second row seat is occupied not.";
CM_ SG_ 896 acu_secondRightSts "Right of second row seat is occupied not.";
CM_ SG_ 896 acu_380_RollingCounter "every message increments the counter.";
CM_ SG_ 896 acu_380_Checksum "CRC8 checksum.";
CM_ SG_ 903 obc_hardwareFaultSts "Hardware fault status.";
CM_ SG_ 903 obc_lockMotorSts "Lock motor status.";
CM_ SG_ 903 obc_errorFlag "Error flag.";
CM_ SG_ 903 obc_state "OBC state.";
CM_ SG_ 903 obc_s2Sts "OBC s2 status.";
CM_ SG_ 903 obc_batteryConnectSts "Battery connect status.";
CM_ SG_ 903 obc_ccOhm "OBC constant current  Ohm.";
CM_ SG_ 903 obc_chargeSts "Charge status.";
CM_ SG_ 903 obc_cpVoltage "OBC  CP Voltage.";
CM_ SG_ 903 obc_slowChargeRelaySts "Slow charge relay status.";
CM_ SG_ 903 obc_fastChargeRelayHSts "Fast charge relay high status.";
CM_ SG_ 903 obc_fastChargeRelayLSts "Fast charge relay low status.";
CM_ SG_ 903 obc_chargerEndChargeReq "Charger end charge request.";
CM_ SG_ 903 obc_387_Rollingcounter "OBC state counter.";
CM_ SG_ 903 obc_387_Checksum "OBC state checksum.";
CM_ SG_ 909 dcdc_hardwareFaultSts "DCDC hardware fault status.";
CM_ SG_ 909 dcdc_errorFlag "DCDC error flag.";
CM_ SG_ 909 dcdc_systemSts "DCDC system status.";
CM_ SG_ 909 dcdc_deratingSts "DCDC derating status.";
CM_ SG_ 909 dcdc_realTemperature "DCDC real temperature.";
CM_ SG_ 909 dcdc_realOutputVoltage "DCDC real output voltage.";
CM_ SG_ 909 dcdc_realOutputCurrent "DCDC real output current.";
CM_ SG_ 909 dcdc_alerState "DCDC aler state.";
CM_ SG_ 909 dcdc_overTemperature "DCDC over temperature.";
CM_ SG_ 909 dcdc_38D_Rollingcounter "Message counter for the message.";
CM_ SG_ 909 dcdc_38D_Checksum "CRC8, checksum.";
CM_ SG_ 916 pot_CatchSWSts "Catch Switch status.";
CM_ SG_ 916 pot_PawlSWSts "Pawl Switch status.";
CM_ SG_ 916 pot_tailgateOpenFailWarning "Tailgate open fail warning.";
CM_ SG_ 916 pot_tailgateCloseFailWarning "Tailgate close fail warning.";
CM_ SG_ 916 pot_tailgateOpenSts "Tailgate open status.";
CM_ SG_ 916 pot_tailgateLearnedPosition "Tailgate learned position.";
CM_ SG_ 916 pot_doorMemoryPosEnb "door Memory position enable.";
CM_ SG_ 916 pot_antiPlayWarning "Tailgate antiplay warning.";
CM_ SG_ 916 pot_tailgateCloseSwSts "Tailgate close switch status.";
CM_ SG_ 916 pot_workingSts "POT working status.";
CM_ SG_ 916 pot_OpenTurnIndicator "POT Open Turn Indicator.";
CM_ SG_ 916 pot_OpenValue "POT Open Value.";
CM_ SG_ 916 pot_NeutralSWSts "POT Neutral  switch status.";
CM_ SG_ 916 pot_MotorOverTempProtection "POT motor over temperature protection.";
CM_ SG_ 916 pot_delayClosingPotReq "Delay closing Request to BCM";
CM_ SG_ 918 ac_ambientTemp "Ambient  temperature.";
CM_ SG_ 918 ac_cabinTemp "Cabin  temperature.";
CM_ SG_ 918 ac_EvapActualTemp "Evaporative actual temperature.";
CM_ SG_ 918 ac_HighPresCoolantTemp "High pressure coolant temperature.";
CM_ SG_ 918 ac_LowPresCoolantTemp "Low pressure coolant temperature.";
CM_ SG_ 918 ac_HighPressure "High pressure.";
CM_ SG_ 918 ac_LowPressure "Low pressure.";
CM_ SG_ 918 ac_ambientTempValid "Ambient temperature valid.";
CM_ SG_ 918 ac_cabinPtcPower "Cabin  PTC power.";
CM_ SG_ 929 vcu_driveMode "Indicates the driving mode of the vehicle.";
CM_ SG_ 929 vcu_towMode "Switching of two modes.";
CM_ SG_ 929 VCU_EscReady "VCU 工作状态";
CM_ SG_ 929 vcu_3A1_checksum "CRC8, message checksum.";
CM_ SG_ 929 vcu_3A1_rollingCounter "Message counter for the message";
CM_ SG_ 929 vcu_ready "Powertrain ready.";
CM_ SG_ 929 vcu_highVoltageSuccess "High voltage status.";
CM_ SG_ 929 vcu_epbReq "epb Request.";
CM_ SG_ 929 vcu_hvOnMode "high voltage On Mode.";
CM_ SG_ 929 vcu_4wdModeSts "4WD mode status.";
CM_ SG_ 929 vcu_RegenModeSts "Energy recovery on off status.";
CM_ SG_ 929 vcu_enableCreepTorqueSts "enable Creep Torque Status.";
CM_ SG_ 929 vcu_memorySts "VCU memory Status.";
CM_ SG_ 929 vcu_torqueDistMode "Torque Distribution Mode";
CM_ SG_ 932 BMS_ThrmlRunawaySt "传感器状态";
CM_ SG_ 932 BMS_3wayValveSt "三通阀状态";
CM_ SG_ 932 BMS_ThrmlRunawayDiagSt "传感器诊断";
CM_ SG_ 932 BMS_ASDensity "气溶胶浓度";
CM_ SG_ 942 mcur0_speed "MCUR0  motor speed.";
CM_ SG_ 942 mcur0_iBus "Bus current.";
CM_ SG_ 942 mcur0_vBus "Bus voltage.";
CM_ SG_ 942 mcur0_faultLevel "MCUR0  fault level.";
CM_ SG_ 942 mcur0_stEgyFlowAndBatt "state energy flow and battery.";
CM_ SG_ 942 mcur0_state "MCUR0 state";
CM_ SG_ 942 mcur0_0x112_timeoutFlag "GW信号指示MCUR0节点在源网段是否超时。
指示以下信号是否超时：
1. mcur0_speed
2. mcur0_vBus
3. mcur0_faultLevel
4. mcur0_state";
CM_ SG_ 942 mcur0_0x312_timeoutFlag "GW信号指示MCUR0节点在源网段是否超时。
指示以下信号是否超时：
1. mcur0_iBus
2. mcur0_stEgyFlowAndBatt";
CM_ SG_ 950 ac_systemOnOffSts "System ON/OFF  Status.";
CM_ SG_ 950 ac_autoSts "AUTO Status.";
CM_ SG_ 950 ac_acSts "AC Status.";
CM_ SG_ 950 ac_driverTempC "Driver Temperature Celsius.";
CM_ SG_ 950 ac_dualSts "Dual Temperature Status.";
CM_ SG_ 950 ac_frontDefrostSts "Front Defrost Status.";
CM_ SG_ 950 ac_passengerTempC "Passenger Temperature Celsius.";
CM_ SG_ 950 ac_recircSts "Fresh Air Status.";
CM_ SG_ 950 ac_modeSts "mode status.";
CM_ SG_ 950 ac_blowerLvSts "Blower Level Status.";
CM_ SG_ 950 ac_diagInfo "AC diagnostic information.";
CM_ SG_ 950 ac_cabinPtcSts "cabin PTC Status.";
CM_ SG_ 950 ac_rearDefrostReq "rear Deforst Req";
CM_ SG_ 950 AC_FreshAirModeRsp "换气设置状态反馈";
CM_ SG_ 950 AC_VentilationCoolRsp "通风降温设置状态反馈";
CM_ SG_ 958 mcuf0_speed "MCU F0 motor speed.";
CM_ SG_ 958 mcuf0_iBus "Bus current.";
CM_ SG_ 958 mcuf0_vBus "Bus voltage.";
CM_ SG_ 958 mcuf0_faultLevel "MCU F0 fault level.";
CM_ SG_ 958 mcuf0_stEgyFlowAndBatt "st energy flow and battery.";
CM_ SG_ 958 mcuf0_state "MCU F0 state.";
CM_ SG_ 958 mcuf0_0x113_timeoutFlag "GW信号指示MCUF0节点在源网段是否超时。
指示以下信号是否超时：
1. mcuf0_speed
2. mcuf0_vBus
3. mcuf0_faultLevel
4. mcuf0_state";
CM_ SG_ 958 mcuf0_0x313_timeoutFlag "GW信号指示MCUF0节点在源网段是否超时。
指示以下信号是否超时：
1. mcuf0_iBus
2. mcuf0_stEgyFlowAndBatt";
CM_ SG_ 961 bcm_rearMirrorSts "Rearview mirror status.";
CM_ SG_ 961 bcm_DRLSts "DRL status.";
CM_ SG_ 961 bcm_sunroofSts "Sunroof status.";
CM_ SG_ 961 bcm_sunshadeSts "Sunshade status.";
CM_ SG_ 961 bcm_windowLFSts "Front left window status.";
CM_ SG_ 961 bcm_windowRFSts "Front right window status.";
CM_ SG_ 961 bcm_leftBsdLedSts "Left side BSD indication LED status.";
CM_ SG_ 961 bcm_rightBsdLedSts "Right side BSD indication LED status.";
CM_ SG_ 961 bcm_windowLRSts "Rear left window status.";
CM_ SG_ 961 bcm_windowRRSts "Rear right window status.";
CM_ SG_ 961 bcm_rearDefrostSts "Rear defrost status.";
CM_ SG_ 961 bcm_delayClosingPotReq "Delay closing POT request.";
CM_ SG_ 961 bcm_rkeTailgateCtrlCmd "RKE tailgate control command.";
CM_ SG_ 961 bcm_rainSensorError "rain sensor error.";
CM_ SG_ 961 bcm_GlassUncloseWarning "车外闭锁车窗未关提醒信号";
CM_ SG_ 961 bcm_posLampSts "Position lamp status.";
CM_ SG_ 961 bcm_autoLampSwSts "Auto lamp switch status.";
CM_ SG_ 961 bcm_rsmSolarRight "Solar value right side";
CM_ SG_ 961 bcm_rsmSolarLeft "Solar value left side";
CM_ SG_ 961 bcm_lowBeamSts "Low beam status.";
CM_ SG_ 961 bcm_highBeamSts "high beam status.";
CM_ SG_ 961 bcm_kickActiveReq "Kick sensor active request.";
CM_ SG_ 961 bcm_rlsSensitivity "Rain sensor sensitivity level.";
CM_ SG_ 961 bcm_rearFogLampSts "rear fog lamp status.";
CM_ SG_ 961 bcm_lightSensorError "light sensor error.";
CM_ SG_ 961 bcm_remoteForbidden "禁止上电状态信号";
CM_ SG_ 961 BCM_rlsWindowCloseReq "RLS_Sunroof_Window_Close Request
天窗&车窗关闭请求";
CM_ SG_ 962 BCM_volOrSOCLowAlarm "Voltage Or SOC Low Alarm.";
CM_ SG_ 962 bcm_centerCtrlPotOnOffSet "Center control POT on/off set.";
CM_ SG_ 962 bcm_RLReadLightSts "Rear left reading lamp status.";
CM_ SG_ 962 bcm_RRReadLightSts "Rear right reading lamp status.";
CM_ SG_ 962 bcm_welcomeRsp "illuminated entry welcomes tatus.";
CM_ SG_ 962 bcm_antiTheftAlarmFormSts "anti Theft Alarm Form Status";
CM_ SG_ 962 bcm_lockAutoCloseWinFdb "lock Auto Close Window Feedback";
CM_ SG_ 962 bcm_screenAutoLiftFdb "screen Auto Lift Feedback";
CM_ SG_ 962 bcm_backlightadjust "背光调节";
CM_ SG_ 962 bcm_DGSWSts "DG Switch Status.";
CM_ SG_ 962 bcm_DGPercentSts "DG Percent Status.";
CM_ SG_ 962 bcm_apmCmd_2U "BCM Window Up/Down Control
防夹模块接收的升窗/降窗控制信号";
CM_ SG_ 962 bcm_hazardSwitchReq "Hazard Light Request.";
CM_ SG_ 962 bcm_welcomeOnOffSetFeedback "welcome light status set feedback";
CM_ SG_ 962 bcm_keyInPotRemind "钥匙遗忘后备箱提醒";
CM_ SG_ 977 bcm_rsm_windowTemp "Window temperature.";
CM_ SG_ 977 bcm_rsm_dewPointTemp "Dew point temperature.";
CM_ SG_ 977 bcm_rsm_relHumidity "Relative humidity.";
CM_ SG_ 977 bcm_rsm_FwBrightness "Forward Brightness value.";
CM_ SG_ 977 bcm_rsm_AmbBrightness "Roof ambient Brightness value.";
CM_ SG_ 977 bcm_rsm_IRBrightness "Infrared Brightness value.";
CM_ SG_ 978 BCM_FLWindowHorizontalSts "左前车窗开度";
CM_ SG_ 978 BCM_FRWindowHorizontalSts "右前车窗开度";
CM_ SG_ 978 BCM_RLWindowHorizontalSts "左后车窗开度";
CM_ SG_ 978 BCM_RRWindowHorizontalSts "右后车窗开度";
CM_ SG_ 978 bcm_srm_srMovement "sunroof movement status";
CM_ SG_ 978 bcm_ssm_ssMovement "sunshade movement status";
CM_ SG_ 981 dscu_drSeatMassSts "Driver Seat massage Status.";
CM_ SG_ 981 dscu_passSeatMassSts "Passenger Seat massage Status.";
CM_ SG_ 981 dscu_easyEntrySts "Easy entry status feedback.";
CM_ SG_ 981 dscu_MirrorAutoTurnDownSts "mirror auto turn down on off status feedback.";
CM_ SG_ 981 dscu_DrMassgIntenSt "Driver Seat Inten State.";
CM_ SG_ 981 dscu_PsgMassgIntenSt "Pass Seat Inten State.";
CM_ SG_ 981 dscu_MemoryPos "DSM_Memory Position.";
CM_ SG_ 981 dscu_leftMirrorSw "Left mirror swich.";
CM_ SG_ 981 dscu_rightMirrorSw "Right mirror swich.";
CM_ SG_ 981 dscu_dsmGetMemoryReq "dsm Get Memory Request.";
CM_ SG_ 981 dscu_Init "dscu Initialize.";
CM_ SG_ 981 dscu_fsvh_passSeatHeatSts "Passenger seat heating status.";
CM_ SG_ 981 dscu_fsvh_passSeatVentSts "Passenger seat ventilation status";
CM_ SG_ 981 dscu_fsvh_drSeatHeatSts "Driver seat heating status.";
CM_ SG_ 981 dscu_fsvh_drSeatVentSts "Driver seat ventilation status";
CM_ SG_ 981 dscu_faceIDAccntGetSeatPosFb "Face ID/账户座椅调出结果反馈";
CM_ SG_ 982 dscu_dsSeatBackPos "Driver seat back position.
主驾靠背位置（百分比）";
CM_ SG_ 982 dscu_dsSeatSlidePos "Driver  seat slide position.
主驾滑道位置（百分比）";
CM_ SG_ 982 dscu_dsSeatHeightPos "Driver seat height position.
主驾高度位置（百分比）";
CM_ SG_ 982 dscu_dsSeatCushionAnglePos "Driver's seat cushion angle position.
主驾座垫角度位置（百分比）";
CM_ SG_ 982 dscu_leftMirrorVerticalPos "左后视镜上下位置（百分比）";
CM_ SG_ 982 dscu_leftMirrorHorizontalPos "左后视镜左右位置（百分比）";
CM_ SG_ 982 dscu_rightMirrorVerticalPos "右后视镜上下位置（百分比）";
CM_ SG_ 982 dscu_rightMirrorHorizontalPos "右后视镜左右位置（百分比）";
CM_ SG_ 1031 obc_maxOutputVoltage "Maximum output voltage.";
CM_ SG_ 1031 obc_maxOutputCurrent "Maximum output current.";
CM_ SG_ 1031 obc_chargeVoltage "Charge voltage.";
CM_ SG_ 1031 obc_chargeCurrent "Charge current.";
CM_ SG_ 255 OBC_AcChgEnergy "本次慢充单次充电电量";
CM_ SG_ 1041 bcm_tpmsLFSts "Front left TPMS sensor status.";
CM_ SG_ 1041 bcm_tpmsRFSts "Front right TPMS sensor status.";
CM_ SG_ 1041 bcm_PressureWarningLF "Front left TPMS sensor PressureWarning";
CM_ SG_ 1041 bcm_PressureWarningRF "Front right TPMS sensor PressureWarning";
CM_ SG_ 1041 bcm_TireTempWarningLF "Front left TPMS sensor TempWarning";
CM_ SG_ 1041 bcm_TireTempWarningRF "Front right TPMS sensor TempWarning";
CM_ SG_ 1041 bcm_tpmsLFLOW_BATT_Warning "Front left TPMS sensor low battery Warning";
CM_ SG_ 1041 bcm_tpmsRFLOW_BATT_Warning "Front right TPMS sensor low battery Warning";
CM_ SG_ 1041 bcm_tpmsLFRAPID_LEAK_Warning "Front left TPMS sensor rapid leak Warning";
CM_ SG_ 1041 bcm_tpmsRFRAPID_LEAK_Warning "Front right TPMS sensor rapid leak Warning";
CM_ SG_ 1041 bcm_tyreLFPressure "Front left tire pressure.";
CM_ SG_ 1041 bcm_tyreLFTemp "Front left tire temperature.";
CM_ SG_ 1041 bcm_tyreRFPressure "Front right tire pressure.";
CM_ SG_ 1041 bcm_tyreRFTemp "Front right tire temperature.";
CM_ SG_ 1057 bcm_tpmsLRSts "Rear left TPMS sensor status.";
CM_ SG_ 1057 bcm_tpmsRRSts "Rear right TPMS sensor status.";
CM_ SG_ 1057 bcm_PressureWarningLR "Rear left TPMS sensor PressureWarning";
CM_ SG_ 1057 bcm_PressureWarningRR "Rear right TPMS sensor PressureWarning";
CM_ SG_ 1057 bcm_TireTempWarningLR "Rear left TPMS sensor TempWarning";
CM_ SG_ 1057 bcm_TireTempWarningRR "Rear right TPMS sensor TempWarning";
CM_ SG_ 1057 bcm_tpmsLRLOW_BATT_Warning "Rear left TPMS sensor low battery Warning";
CM_ SG_ 1057 bcm_tpmsRRLOW_BATT_Warning "Rear right TPMS sensor low battery Warning";
CM_ SG_ 1057 bcm_tpmsLRRAPID_LEAK_Warning "Rear left TPMS sensor  rapid leak Warning";
CM_ SG_ 1057 bcm_tpmsRRRAPID_LEAK_Warning "Rear right TPMS sensor rapid leak Warning";
CM_ SG_ 1057 bcm_tyreLRPressure "Rear left tire pressure.";
CM_ SG_ 1057 bcm_tyreLRTemp "Rear left tire temperature.";
CM_ SG_ 1057 bcm_tyreRRPressure "Rear right tire pressure.";
CM_ SG_ 1057 bcm_tyreRRTemp "Rear right tire temperature.";
CM_ SG_ 1073 bcm_rllmStopLampFault "Stop Lamp Good/Fault Status.";
CM_ SG_ 1073 bcm_rllmLeftTurnLampFault "Turn Lamp Good/Fault Status.";
CM_ SG_ 1073 bcm_rllmFogLampFault "Fog  LampGood/Fault Status.";
CM_ SG_ 1073 bcm_rllmReverseLampFault "Reverse Lamp Good/Fault Status.";
CM_ SG_ 1073 bcm_rllmPositionLampFault "Position Lamp Good/Fault Status.";
CM_ SG_ 1073 bcm_rmlmStopLampFault "Stop Lamp Good/Fault Status.";
CM_ SG_ 1073 bcm_rmlmLeftTurnLampFault "Turn Lamp Good/Fault Status.";
CM_ SG_ 1073 bcm_rmlmRightTurnLampFault "Turn Lamp Good/Fault Status.";
CM_ SG_ 1073 bcm_rmlmPositionLampFault "Position Lamp Good/Fault Status.";
CM_ SG_ 1073 bcm_rrlmStopLampFault "Stop Lamp Good/Fault Status.";
CM_ SG_ 1073 bcm_rrlmRightTurnLampFault "Turn Lamp Good/Fault Status.";
CM_ SG_ 1073 bcm_rrlmFogLampFault "Fog  LampGood/Fault Status.";
CM_ SG_ 1073 bcm_rrlmReverseLampFault "Reverse Lamp Good/Fault Status.";
CM_ SG_ 1073 bcm_rrlmPositionLampFault "Position Lamp Good/Fault Status.";
CM_ SG_ 1073 bcm_rmlmHighStopLampFault "High Stop Lamp Good/Fault Status.";
CM_ SG_ 1089 vcu_vehicleSpeed "Vehicle speed.";
CM_ SG_ 1089 vcu_cruiseCtrlSetSpeed "Set cruise control speed.";
CM_ SG_ 1089 vcu_brakeLight "Brake light.";
CM_ SG_ 1089 vcu_alertLevel "Alert level.";
CM_ SG_ 1089 vcu_driveReady "Drive ready indicator.";
CM_ SG_ 1089 vcu_hvState "High voltage state.";
CM_ SG_ 1089 vcu_highVoltFail "High voltage  fail.";
CM_ SG_ 1089 vcu_regenmode "Regeneration mode.";
CM_ SG_ 1089 vcu_drivePowerAllowed "允许驱动功率，用于仪表显示";
CM_ SG_ 1089 vcu_gearSwitchFail "Gear switch fail.";
CM_ SG_ 1089 vcu_refuelReq "VCU refuel request.";
CM_ SG_ 1089 vcu_drivePowerAcutal "实际驱动功率，用于仪表显示";
CM_ SG_ 1089 vcu_evModeDisplay "EV或REV模式";
CM_ SG_ 1089 VCU_VehicleSpeedValid "Indicate vehicle reference speed valid";
CM_ SG_ 1089 vcu_RmtEngStartReq "VCU请求用户远程启动发动机";
CM_ SG_ 1089 vcu_ExhibitionSts "Exhibition mode Status";
CM_ SG_ 1089 vcu_remoteVehicleForbiddenStart "VCU remote vehicle forbidden start.";
CM_ SG_ 1274 gw_vin_frame "VIN";
CM_ SG_ 1274 gw_vin0 "VIN低字节";
CM_ SG_ 1274 gw_vin1 "VIN";
CM_ SG_ 1274 gw_vin2 "VIN";
CM_ SG_ 1274 gw_vin3 "VIN";
CM_ SG_ 1274 gw_vin4 "VIN";
CM_ SG_ 1274 gw_vin5 "VIN";
CM_ SG_ 1274 gw_vin6 "VIN高字节";
CM_ SG_ 1275 GW_Mode "the signal indicates the current gateway state to forbid diagnosis";
CM_ SG_ 1297 vcu_cellTemperatureDifHig "cellTemperatureDifferenceHig";
CM_ SG_ 1297 vcu_batteryOverTemperature "Battery over temperature.";
CM_ SG_ 1297 vcu_overVoltage "Over voltage.";
CM_ SG_ 1297 vcu_lowVoltage "Low voltage.";
CM_ SG_ 1297 vcu_lowSoc "Low SOC.";
CM_ SG_ 1297 vcu_cellOverVoltage "Cell  over voltage.";
CM_ SG_ 1297 vcu_cellLowVoltage "Cell low voltage.";
CM_ SG_ 1297 vcu_highSoc "High SOC.";
CM_ SG_ 1297 vcu_socStepChange "Warning for battery pack SOC step change.";
CM_ SG_ 1297 vcu_chargerMismatch "Charger mismatch.";
CM_ SG_ 1297 vcu_cellOutOfBalance "Cell out of balance.";
CM_ SG_ 1297 vcu_isolationFault "Isolation fault.";
CM_ SG_ 1297 vcu_dcdcOverTemperature "DCDC over temperature.";
CM_ SG_ 1297 vcu_brakeFault "Brake fault.";
CM_ SG_ 1297 vcu_dcdcAlerState "DCDC aler state.";
CM_ SG_ 1297 vcu_mcuf0OverTemperature "MCUF0 over temperature.";
CM_ SG_ 1297 vcu_mcur0OverTemperature "MCUR0  over temperature.";
CM_ SG_ 1297 vcu_hvilFault "High voltage interlock fault.";
CM_ SG_ 1297 vcu_mcuf0MotorOverTemperature "MCUF0 motor over temperature.";
CM_ SG_ 1297 vcu_mcur0MotorOverTemperature "MCUR0 motor over temperature.";
CM_ SG_ 1297 vcu_batteryOverCharge "Battery over charge.";
CM_ SG_ 1298 mcur0_totalFaultNum "Total fault number.";
CM_ SG_ 1298 mcur0_workMode "MCUR0 work mode.";
CM_ SG_ 1298 mcur0_OverTemperature "MCUR0 over temperature.";
CM_ SG_ 1298 mcur0_MotorOverTemperature "Motor over temperature.";
CM_ SG_ 1299 mcuf0_totalFaultNum "Total fault number.";
CM_ SG_ 1299 mcuf0_workMode "MCUF0 work mode.";
CM_ SG_ 1299 mcuf0_OverTemperature "MCUF0 over temperature.";
CM_ SG_ 1299 mcuf0_MotorOverTemperature "Motor over temperature.";
CM_ SG_ 1300 bms_SOC "State of Charge.";
CM_ SG_ 1300 bms_SOH "State of Health.";
CM_ SG_ 1300 bms_SOE "State of Energy.";
CM_ SG_ 1300 bms_remainChargeTime "Remaining charge time.";
CM_ SG_ 1300 bms_batteryConditionFail "Battery condition fail.";
CM_ SG_ 1300 bms_BatteryConditionSts "Battery condition status.";
CM_ SG_ 1300 bms_maxChargeSOC "Maximum charge SOC.";
CM_ SG_ 1300 bms_maxACChargeAllowedCurrent "Maximum AC charge allowed current.";
CM_ SG_ 1300 bms_stEgyFlowSysDischRgn "State of energy flow system discharge Rgn.";
CM_ SG_ 1300 bms_stEgyFlowOBCAndBatt "State of energy flow for OBC and battery.";
CM_ SG_ 1300 bms_chargeFormSts "Charge form status.";
CM_ SG_ 1377 vcu_PwrSincelastcharge "Power Since the last charge
自上次充电后总电耗";
CM_ SG_ 1377 vcu_PwroftripA "Power of tripA
行程A总电耗";
CM_ SG_ 1396 bms_isolationResistance "Isolation resistance.";
CM_ SG_ 1396 bms_vehicleChargingSts "Vehicle charging Status.";
CM_ SG_ 1396 bms_totalFaultNum "Total fault number.";
CM_ SG_ 1396 bms_packTempMinModuleIdx "Pack temperature minimum module index.";
CM_ SG_ 1396 bms_packTempMinSensorIdx "Pack temperature minimum sensor index.";
CM_ SG_ 1396 bms_packTempMaxModuleIdx "Pack temperature maximum module index.";
CM_ SG_ 1396 bms_packTempMaxSensorIdx "Pack temperature maximum sensor index.";
CM_ SG_ 1396 bms_residualEnergy "Battery residual energy.";
CM_ SG_ 1412 bms_temperatureIndex "Temperature index.";
CM_ SG_ 1412 bms_moduleXTempSensor1 "Module X temperature sensor1.";
CM_ SG_ 1412 bms_moduleXTempSensor2 "Module X temperature sensor2.";
CM_ SG_ 1412 bms_moduleXTempSensor3 "Module X temperature sensor3.";
CM_ SG_ 1412 bms_moduleXTempSensor4 "Module X temperature sensor4.";
CM_ SG_ 1412 bms_moduleXTempSensor5 "Module X temperature sensor5.";
CM_ SG_ 1412 bms_moduleXTempSensor6 "Module X temperature sensor6.";
CM_ SG_ 1428 bms_voltageIndex "Voltage index.";
CM_ SG_ 1428 bms_moduleXcellBlock1 "Module X cell block1.";
CM_ SG_ 1428 bms_moduleXcellBlock2 "Module X cell block2.";
CM_ SG_ 1428 bms_moduleXcellBlock3 "Module X cell block3.";
CM_ SG_ 1428 bms_moduleXcellBlock4 "Module X cell block4.";
CM_ SG_ 254 bms_DcChgEnergy "快充过程充电量";
CM_ SG_ 1566 GW_INFO_RMR "Repeat Message Request";
CM_ SG_ 1566 GW_INFO_AWB "Active Wakeup Bit";
CM_ SG_ 1832 Diag_PhyReq_TBOX_Data "Diagnostic Physical Request Data to TBOX";
CM_ SG_ 1921 Diag_Resp_BCM_Data "Diagnostic Physical response Data from BCM";
BA_DEF_ BO_  "NmMessage" ENUM  "No","Yes";
BA_DEF_ BO_  "DiagState" ENUM  "No","Yes";
BA_DEF_ BO_  "GenMsgSendType" ENUM  "Cyclic","Event","IfActive","CE","CA","NoMsgSendType";
BA_DEF_ BO_  "GenMsgCycleTime" INT 0 0;
BA_DEF_ SG_  "GenSigSendType" ENUM  "Cyclic","OnChange","OnWrite","IfActive","OnChangeWithRepetition","OnWriteWithRepetition","IfActiveWithRepetition","NoSigSendType","OnChangeAndIfActive","OnChangeAndIfActiveWithRepetition","CA","CE","Event";
BA_DEF_ SG_  "GenSigStartValue" INT 0 0;
BA_DEF_ SG_  "GenSigInactiveValue" INT 0 0;
BA_DEF_ BO_  "GenMsgCycleTimeFast" INT 0 0;
BA_DEF_ BO_  "GenMsgNrOfRepetition" INT 0 0;
BA_DEF_DEF_  "NmMessage" "No";
BA_DEF_DEF_  "DiagState" "No";
BA_DEF_DEF_  "GenMsgSendType" "Cyclic";
BA_DEF_DEF_  "GenMsgCycleTime" 0;
BA_DEF_DEF_  "GenSigSendType" "Cyclic";
BA_DEF_DEF_  "GenSigStartValue" 0;
BA_DEF_DEF_  "GenSigInactiveValue" 0;
BA_DEF_DEF_  "GenMsgCycleTimeFast" 0;
BA_DEF_DEF_  "GenMsgNrOfRepetition" 0;
BA_ "GenMsgCycleTime" BO_ 801 100;
BA_ "GenMsgCycleTime" BO_ 802 100;
BA_ "GenMsgCycleTime" BO_ 803 100;
BA_ "GenMsgCycleTime" BO_ 804 100;
BA_ "GenMsgCycleTime" BO_ 816 100;
BA_ "GenMsgCycleTime" BO_ 817 100;
BA_ "GenMsgCycleTime" BO_ 820 100;
BA_ "GenMsgCycleTime" BO_ 823 100;
BA_ "GenMsgCycleTime" BO_ 836 100;
BA_ "GenMsgCycleTime" BO_ 841 50;
BA_ "GenMsgCycleTime" BO_ 858 50;
BA_ "GenMsgCycleTime" BO_ 862 500;
BA_ "GenMsgNrOfRepetition" BO_ 868 3;
BA_ "GenMsgCycleTimeFast" BO_ 868 1000;
BA_ "GenMsgSendType" BO_ 868 1;
BA_ "GenMsgCycleTime" BO_ 873 50;
BA_ "GenMsgCycleTime" BO_ 878 50;
BA_ "GenMsgCycleTime" BO_ 894 100;
BA_ "GenMsgNrOfRepetition" BO_ 896 130;
BA_ "GenMsgCycleTimeFast" BO_ 896 20;
BA_ "GenMsgCycleTime" BO_ 896 50;
BA_ "GenMsgSendType" BO_ 896 3;
BA_ "GenMsgCycleTime" BO_ 903 100;
BA_ "GenMsgCycleTime" BO_ 909 100;
BA_ "GenMsgCycleTime" BO_ 916 100;
BA_ "GenMsgCycleTime" BO_ 918 100;
BA_ "GenMsgCycleTime" BO_ 929 100;
BA_ "GenMsgCycleTime" BO_ 932 100;
BA_ "GenMsgCycleTime" BO_ 942 100;
BA_ "GenMsgCycleTime" BO_ 950 100;
BA_ "GenMsgCycleTime" BO_ 958 100;
BA_ "GenMsgCycleTime" BO_ 961 100;
BA_ "GenMsgCycleTime" BO_ 962 100;
BA_ "GenMsgCycleTime" BO_ 977 100;
BA_ "GenMsgCycleTime" BO_ 978 100;
BA_ "GenMsgCycleTime" BO_ 981 100;
BA_ "GenMsgCycleTime" BO_ 982 100;
BA_ "GenMsgCycleTime" BO_ 1031 200;
BA_ "GenMsgNrOfRepetition" BO_ 255 10;
BA_ "GenMsgCycleTimeFast" BO_ 255 100;
BA_ "GenMsgSendType" BO_ 255 1;
BA_ "GenMsgCycleTime" BO_ 1041 200;
BA_ "GenMsgCycleTime" BO_ 1057 200;
BA_ "GenMsgCycleTime" BO_ 1073 500;
BA_ "GenMsgCycleTime" BO_ 1089 100;
BA_ "GenMsgCycleTime" BO_ 1274 1000;
BA_ "GenMsgCycleTime" BO_ 1275 1000;
BA_ "GenMsgCycleTime" BO_ 1297 1000;
BA_ "GenMsgCycleTime" BO_ 1298 1000;
BA_ "GenMsgCycleTime" BO_ 1299 1000;
BA_ "GenMsgCycleTime" BO_ 1300 1000;
BA_ "GenMsgCycleTime" BO_ 1377 1000;
BA_ "GenMsgCycleTime" BO_ 1396 1000;
BA_ "GenMsgCycleTime" BO_ 1412 100;
BA_ "GenMsgCycleTime" BO_ 1428 100;
BA_ "GenMsgNrOfRepetition" BO_ 254 10;
BA_ "GenMsgCycleTimeFast" BO_ 254 100;
BA_ "GenMsgSendType" BO_ 254 1;
BA_ "GenMsgSendType" BO_ 1566 1;
BA_ "NmMessage" BO_ 1566 1;
BA_ "GenMsgSendType" BO_ 1832 1;
BA_ "GenMsgSendType" BO_ 1921 1;
BA_ "GenSigStartValue" SG_ 817 vcu_v2vChrgOutCurntFdbk 9;
BA_ "GenSigStartValue" SG_ 841 mrr_obj0_TargetType 3;
BA_ "GenSigStartValue" SG_ 841 mrr_obj1_TargetType 3;
BA_ "GenSigStartValue" SG_ 858 mpc_las_roadCurvature 60;
BA_ "GenSigStartValue" SG_ 858 mpc_las_LLaneDistance 28;
BA_ "GenSigStartValue" SG_ 858 mpc_las_RLaneDistance 32;
BA_ "GenSigStartValue" SG_ 858 mpc_LL_Line_Curvature 60;
BA_ "GenSigStartValue" SG_ 858 mpc_RR_Line_Curvature 60;
BA_ "GenSigStartValue" SG_ 868 packCode_Index 1;
BA_ "GenSigSendType" SG_ 868 packCode_Index 5;
BA_ "GenSigSendType" SG_ 868 packCode1 4;
BA_ "GenSigSendType" SG_ 868 packCode2 4;
BA_ "GenSigSendType" SG_ 868 packCode3 4;
BA_ "GenSigSendType" SG_ 868 packCode4 4;
BA_ "GenSigSendType" SG_ 868 packCode5 4;
BA_ "GenSigSendType" SG_ 868 packCode6 4;
BA_ "GenSigSendType" SG_ 868 packCode7 4;
BA_ "GenSigStartValue" SG_ 873 mrr_obj2_TargetType 3;
BA_ "GenSigStartValue" SG_ 873 mrr_obj3_TargetType 3;
BA_ "GenSigStartValue" SG_ 878 eps_modeSts 1;
BA_ "GenSigStartValue" SG_ 894 gcu_torqueEst 8000;
BA_ "GenSigStartValue" SG_ 894 ecu_engCoolantTemp 64;
BA_ "GenSigStartValue" SG_ 896 acu_warningLampSts 1;
BA_ "GenSigSendType" SG_ 896 acu_crashOutputSts 4;
BA_ "GenSigStartValue" SG_ 896 acu_driverSeatBeltStsValid 1;
BA_ "GenSigStartValue" SG_ 896 acu_passengerSeatBeltStsValid 1;
BA_ "GenSigStartValue" SG_ 896 acu_passengerAirbagSts 1;
BA_ "GenSigStartValue" SG_ 916 pot_tailgateOpenSts 1;
BA_ "GenSigStartValue" SG_ 918 ac_ambientTemp 80;
BA_ "GenSigStartValue" SG_ 918 ac_cabinTemp 80;
BA_ "GenSigStartValue" SG_ 918 ac_EvapActualTemp 80;
BA_ "GenSigStartValue" SG_ 918 ac_HighPresCoolantTemp 80;
BA_ "GenSigStartValue" SG_ 918 ac_LowPresCoolantTemp 80;
BA_ "GenSigStartValue" SG_ 929 vcu_RegenModeSts 2;
BA_ "GenSigStartValue" SG_ 929 vcu_enableCreepTorqueSts 1;
BA_ "GenSigStartValue" SG_ 942 mcur0_iBus 3000;
BA_ "GenSigStartValue" SG_ 958 mcuf0_iBus 3000;
BA_ "GenSigStartValue" SG_ 961 bcm_rsmSolarRight 254;
BA_ "GenSigStartValue" SG_ 961 bcm_rsmSolarLeft 254;
BA_ "GenSigStartValue" SG_ 962 bcm_lockAutoCloseWinFdb 1;
BA_ "GenSigStartValue" SG_ 962 bcm_welcomeOnOffSetFeedback 2;
BA_ "GenSigStartValue" SG_ 977 bcm_rsm_FwBrightness 2046;
BA_ "GenSigStartValue" SG_ 977 bcm_rsm_AmbBrightness 1022;
BA_ "GenSigStartValue" SG_ 977 bcm_rsm_IRBrightness 254;
BA_ "GenSigStartValue" SG_ 978 BCM_FLWindowHorizontalSts 127;
BA_ "GenSigStartValue" SG_ 978 BCM_FRWindowHorizontalSts 127;
BA_ "GenSigStartValue" SG_ 978 BCM_RLWindowHorizontalSts 127;
BA_ "GenSigStartValue" SG_ 978 BCM_RRWindowHorizontalSts 127;
BA_ "GenSigStartValue" SG_ 981 dscu_easyEntrySts 1;
BA_ "GenSigStartValue" SG_ 981 dscu_MirrorAutoTurnDownSts 1;
BA_ "GenSigStartValue" SG_ 981 dscu_leftMirrorSw 1;
BA_ "GenSigStartValue" SG_ 981 dscu_rightMirrorSw 1;
BA_ "GenSigStartValue" SG_ 255 OBC_AcChgEnergy 2047;
BA_ "GenSigSendType" SG_ 255 OBC_AcChgEnergy 4;
BA_ "GenSigStartValue" SG_ 1089 vcu_ExhibitionSts 1;
BA_ "GenSigStartValue" SG_ 1300 bms_remainChargeTime 255;
BA_ "GenSigStartValue" SG_ 1300 bms_maxChargeSOC 100;
BA_ "GenSigStartValue" SG_ 1300 bms_maxACChargeAllowedCurrent 62;
BA_ "GenSigStartValue" SG_ 1377 vcu_PwrSincelastcharge 5000;
BA_ "GenSigStartValue" SG_ 1377 vcu_PwroftripA 5000;
BA_ "GenSigStartValue" SG_ 1396 bms_vehicleChargingSts 3;
BA_ "GenSigStartValue" SG_ 1396 bms_packTempMinModuleIdx 1;
BA_ "GenSigStartValue" SG_ 1396 bms_packTempMaxModuleIdx 1;
BA_ "GenSigStartValue" SG_ 254 bms_DcChgEnergy 2047;
BA_ "GenSigSendType" SG_ 254 bms_DcChgEnergy 4;
BA_ "GenSigSendType" SG_ 1566 GW_INFO_RMR 2;
BA_ "GenSigSendType" SG_ 1566 GW_INFO_AWB 2;
BA_ "GenSigSendType" SG_ 1832 Diag_PhyReq_TBOX_Data 2;
BA_ "GenSigSendType" SG_ 1921 Diag_Resp_BCM_Data 2;
VAL_ 801 vcu_w029_coolantLevelLow 1 "fault" 0 "NO_fault" ;
VAL_ 801 vcu_f029_coolantLevelLow 1 "fault" 0 "NO_fault" ;
VAL_ 802 mcur0_w000_overVoltage 1 "Fault" 0 "No Fault" ;
VAL_ 802 mcur0_f000_overVoltage 1 "Fault" 0 "No Fault" ;
VAL_ 802 mcur0_w001_overSpeed 1 "Fault" 0 "No Fault" ;
VAL_ 802 mcur0_f001_overSpeed 1 "Fault" 0 "No Fault" ;
VAL_ 802 mcur0_w002_overCurrentPhA 1 "Fault" 0 "No Fault" ;
VAL_ 802 mcur0_f002_overCurrentPhA 1 "Fault" 0 "No Fault" ;
VAL_ 802 mcur0_w003_overCurrentPhB 1 "Fault" 0 "No Fault" ;
VAL_ 802 mcur0_f003_overCurrentPhB 1 "Fault" 0 "No Fault" ;
VAL_ 802 mcur0_w004_overCurrentPhC 1 "Fault" 0 "No Fault" ;
VAL_ 802 mcur0_f004_overCurrentPhC 1 "Fault" 0 "No Fault" ;
VAL_ 802 mcur0_w005_canError 1 "Fault" 0 "No Fault" ;
VAL_ 802 mcur0_f005_canError 1 "Fault" 0 "No Fault" ;
VAL_ 802 mcur0_w006_noCurrentPhA 1 "Fault" 0 "No Fault" ;
VAL_ 802 mcur0_f006_noCurrentPhA 1 "Fault" 0 "No Fault" ;
VAL_ 802 mcur0_w007_noCurrentPhB 1 "Fault" 0 "No Fault" ;
VAL_ 802 mcur0_f007_noCurrentPhB 1 "Fault" 0 "No Fault" ;
VAL_ 802 mcur0_w008_noCurrentPhC 1 "Fault" 0 "No Fault" ;
VAL_ 802 mcur0_f008_noCurrentPhC 1 "Fault" 0 "No Fault" ;
VAL_ 802 mcur0_w009_taskOverrun100Hz 1 "Fault" 0 "No Fault" ;
VAL_ 802 mcur0_f009_taskOverrun100Hz 1 "Fault" 0 "No Fault" ;
VAL_ 802 mcur0_w010_taskOverrun10Hz 1 "Fault" 0 "No Fault" ;
VAL_ 802 mcur0_f010_taskOverrun10Hz 1 "Fault" 0 "No Fault" ;
VAL_ 802 mcur0_w011_PhATopDsatFaltSta 1 "Fault" 0 "No Fault" ;
VAL_ 802 mcur0_f011_PhATopDsatFaltSta 1 "Fault" 0 "No Fault" ;
VAL_ 802 mcur0_w012_PhBTopDsatFaltSta 1 "Fault" 0 "No Fault" ;
VAL_ 802 mcur0_f012_PhBTopDsatFaltSta 1 "Fault" 0 "No Fault" ;
VAL_ 802 mcur0_w013_PhCTopDsatFaltSta 1 "Fault" 0 "No Fault" ;
VAL_ 802 mcur0_f013_PhCTopDsatFaltSta 1 "Fault" 0 "No Fault" ;
VAL_ 802 mcur0_w014_PhABotDsatFaltSta 1 "Fault" 0 "No Fault" ;
VAL_ 802 mcur0_f014_PhABotDsatFaltSta 1 "Fault" 0 "No Fault" ;
VAL_ 802 mcur0_w015_PhBBotDsatFaltSta 1 "Fault" 0 "No Fault" ;
VAL_ 802 mcur0_f015_PhBBotDsatFaltSta 1 "Fault" 0 "No Fault" ;
VAL_ 802 mcur0_w016_PhCBotDsatFaltSta 1 "Fault" 0 "No Fault" ;
VAL_ 802 mcur0_f016_PhCBotDsatFaltSta 1 "Fault" 0 "No Fault" ;
VAL_ 802 mcur0_w017_underVoltage 1 "Fault" 0 "No Fault" ;
VAL_ 802 mcur0_f017_underVoltage 1 "Fault" 0 "No Fault" ;
VAL_ 802 mcur0_w018_overTemperature 1 "Fault" 0 "No Fault" ;
VAL_ 802 mcur0_f018_overTemperature 1 "Fault" 0 "No Fault" ;
VAL_ 802 mcur0_w019_underTemperature 1 "Fault" 0 "No Fault" ;
VAL_ 802 mcur0_f019_underTemperature 1 "Fault" 0 "No Fault" ;
VAL_ 802 mcur0_w020_controllerOverTemp 1 "Fault" 0 "No Fault" ;
VAL_ 802 mcur0_f020_controllerOverTemp 1 "Fault" 0 "No Fault" ;
VAL_ 802 mcur0_w021_adcOverRun 1 "Fault" 0 "No Fault" ;
VAL_ 802 mcur0_f021_adcOverRun 1 "Fault" 0 "No Fault" ;
VAL_ 802 mcur0_w022_HwOverCurrentPh 1 "Fault" 0 "No Fault" ;
VAL_ 802 mcur0_f022_HwOverCurrentPh 1 "Fault" 0 "No Fault" ;
VAL_ 802 mcur0_w023_HwOverCurrentPh 1 "Fault" 0 "No Fault" ;
VAL_ 802 mcur0_f023_HwOverCurrentPh 1 "Fault" 0 "No Fault" ;
VAL_ 802 mcur0_w024_HwOverCurrentPh 1 "Fault" 0 "No Fault" ;
VAL_ 802 mcur0_f024_HwOverCurrentPh 1 "Fault" 0 "No Fault" ;
VAL_ 802 mcur0_w025_hardwareOverVoltage 1 "Fault" 0 "No Fault" ;
VAL_ 802 mcur0_f025_hardwareOverVoltage 1 "Fault" 0 "No Fault" ;
VAL_ 802 mcur0_w026_hardwareDsatFault 1 "Fault" 0 "No Fault" ;
VAL_ 802 mcur0_f026_hardwareDsatFault 1 "Fault" 0 "No Fault" ;
VAL_ 802 mcur0_w027_curSenOffsetOutOfR 1 "Fault" 0 "No Fault" ;
VAL_ 802 mcur0_f027_curSenOffsetOutOfR 1 "Fault" 0 "No Fault" ;
VAL_ 803 mcuf0_w000_overVoltage 1 "Fault" 0 "No Fault" ;
VAL_ 803 mcuf0_f000_overVoltage 1 "Fault" 0 "No Fault" ;
VAL_ 803 mcuf0_w001_overSpeed 1 "Fault" 0 "No Fault" ;
VAL_ 803 mcuf0_f001_overSpeed 1 "Fault" 0 "No Fault" ;
VAL_ 803 mcuf0_w002_overCurrentPhA 1 "Fault" 0 "No Fault" ;
VAL_ 803 mcuf0_f002_overCurrentPhA 1 "Fault" 0 "No Fault" ;
VAL_ 803 mcuf0_w003_overCurrentPhB 1 "Fault" 0 "No Fault" ;
VAL_ 803 mcuf0_f003_overCurrentPhB 1 "Fault" 0 "No Fault" ;
VAL_ 803 mcuf0_w004_overCurrentPhC 1 "Fault" 0 "No Fault" ;
VAL_ 803 mcuf0_f004_overCurrentPhC 1 "Fault" 0 "No Fault" ;
VAL_ 803 mcuf0_w005_canError 1 "Fault" 0 "No Fault" ;
VAL_ 803 mcuf0_f005_canError 1 "Fault" 0 "No Fault" ;
VAL_ 803 mcuf0_w006_noCurrentPhA 1 "Fault" 0 "No Fault" ;
VAL_ 803 mcuf0_f006_noCurrentPhA 1 "Fault" 0 "No Fault" ;
VAL_ 803 mcuf0_w007_noCurrentPhB 1 "Fault" 0 "No Fault" ;
VAL_ 803 mcuf0_f007_noCurrentPhB 1 "Fault" 0 "No Fault" ;
VAL_ 803 mcuf0_w008_noCurrentPhC 1 "Fault" 0 "No Fault" ;
VAL_ 803 mcuf0_f008_noCurrentPhC 1 "Fault" 0 "No Fault" ;
VAL_ 803 mcuf0_w009_taskOverrun100Hz 1 "Fault" 0 "No Fault" ;
VAL_ 803 mcuf0_f009_taskOverrun100Hz 1 "Fault" 0 "No Fault" ;
VAL_ 803 mcuf0_w010_taskOverrun10Hz 1 "Fault" 0 "No Fault" ;
VAL_ 803 mcuf0_f010_taskOverrun10Hz 1 "Fault" 0 "No Fault" ;
VAL_ 803 mcuf0_w011_PhATopDsatFaltSts 1 "Fault" 0 "No Fault" ;
VAL_ 803 mcuf0_f011_PhATopDsatFaltSts 1 "Fault" 0 "No Fault" ;
VAL_ 803 mcuf0_w012_PhBTopDsatFaltSts 1 "Fault" 0 "No Fault" ;
VAL_ 803 mcuf0_f012_PhBTopDsatFaltSts 1 "Fault" 0 "No Fault" ;
VAL_ 803 mcuf0_w013_PhCTopDsatFaltSts 1 "Fault" 0 "No Fault" ;
VAL_ 803 mcuf0_f013_PhCTopDsatFaltSts 1 "Fault" 0 "No Fault" ;
VAL_ 803 mcuf0_w014_PhABotDsatFaltSts 1 "Fault" 0 "No Fault" ;
VAL_ 803 mcuf0_f014_PhABotDsatFaltSts 1 "Fault" 0 "No Fault" ;
VAL_ 803 mcuf0_w015_PhBBotDsatFaltSts 1 "Fault" 0 "No Fault" ;
VAL_ 803 mcuf0_f015_PhBBotDsatFaltSts 1 "Fault" 0 "No Fault" ;
VAL_ 803 mcuf0_w016_PhCBotDsatFaltSts 1 "Fault" 0 "No Fault" ;
VAL_ 803 mcuf0_f016_PhCBotDsatFaltSts 1 "Fault" 0 "No Fault" ;
VAL_ 803 mcuf0_w017_underVoltage 1 "Fault" 0 "No Fault" ;
VAL_ 803 mcuf0_f017_underVoltage 1 "Fault" 0 "No Fault" ;
VAL_ 803 mcuf0_w018_overTemperature 1 "Fault" 0 "No Fault" ;
VAL_ 803 mcuf0_f018_overTemperature 1 "Fault" 0 "No Fault" ;
VAL_ 803 mcuf0_w019_underTemperature 1 "Fault" 0 "No Fault" ;
VAL_ 803 mcuf0_f019_underTemperature 1 "Fault" 0 "No Fault" ;
VAL_ 803 mcuf0_w020_controllerOverTemp 1 "Fault" 0 "No Fault" ;
VAL_ 803 mcuf0_f020_controllerOverTemp 1 "Fault" 0 "No Fault" ;
VAL_ 803 mcuf0_w021_adcOverRun 1 "Fault" 0 "No Fault" ;
VAL_ 803 mcuf0_f021_adcOverRun 1 "Fault" 0 "No Fault" ;
VAL_ 803 mcuf0_w022_hdOverCurrentPhA 1 "Fault" 0 "No Fault" ;
VAL_ 803 mcuf0_f022_hdOverCurrentPhA 1 "Fault" 0 "No Fault" ;
VAL_ 803 mcuf0_w023_hdOverCurrentPhB 1 "Fault" 0 "No Fault" ;
VAL_ 803 mcuf0_f023_hdOverCurrentPhB 1 "Fault" 0 "No Fault" ;
VAL_ 803 mcuf0_w024_hdOverCurrentPhC 1 "Fault" 0 "No Fault" ;
VAL_ 803 mcuf0_f024_hdOverCurrentPhC 1 "Fault" 0 "No Fault" ;
VAL_ 803 mcuf0_w025_hardwareOverVoltage 1 "Fault" 0 "No Fault" ;
VAL_ 803 mcuf0_f025_hardwareOverVoltage 1 "Fault" 0 "No Fault" ;
VAL_ 803 mcuf0_w026_hardwareDsatFault 1 "Fault" 0 "No Fault" ;
VAL_ 803 mcuf0_f026_hardwareDsatFault 1 "Fault" 0 "No Fault" ;
VAL_ 803 mcuf0_w027_curSenOffsetOutOfR 1 "Fault" 0 "No Fault" ;
VAL_ 803 mcuf0_f027_curSenOffsetOutOfR 1 "Fault" 0 "No Fault" ;
VAL_ 804 bms_w000_packUnderVoltage 1 "Fault" 0 "No Fault" ;
VAL_ 804 bms_f000_packUnderVoltage 1 "Fault" 0 "No Fault" ;
VAL_ 804 bms_w001_packOverVoltage 1 "Fault" 0 "No Fault" ;
VAL_ 804 bms_f001_packOverVoltage 1 "Fault" 0 "No Fault" ;
VAL_ 804 bms_w002_packOverCrntDischg 1 "Fault" 0 "No Fault" ;
VAL_ 804 bms_f002_packOverCrntDischg 1 "Fault" 0 "No Fault" ;
VAL_ 804 bms_w003_packOverCrntChg 1 "Fault" 0 "No Fault" ;
VAL_ 804 bms_f003_packOverCrntChg 1 "Fault" 0 "No Fault" ;
VAL_ 804 bms_w004_cellUnderVoltage 1 "Fault" 0 "No Fault" ;
VAL_ 804 bms_f004_cellUnderVoltage 1 "Fault" 0 "No Fault" ;
VAL_ 804 bms_w005_cellOverVoltage 1 "Fault" 0 "No Fault" ;
VAL_ 804 bms_f005_cellOverVoltage 1 "Fault" 0 "No Fault" ;
VAL_ 804 bms_w006_cellUnderTemp 1 "Fault" 0 "No Fault" ;
VAL_ 804 bms_f006_cellUnderTemp 1 "Fault" 0 "No Fault" ;
VAL_ 804 bms_w007_cellOverTemp 1 "Fault" 0 "No Fault" ;
VAL_ 804 bms_f007_cellOverTemp 1 "Fault" 0 "No Fault" ;
VAL_ 804 bms_w008_contactorPosMainHSFlt 1 "Fault" 0 "No Fault" ;
VAL_ 804 bms_f008_contactorPosMainHSFlt 1 "Fault" 0 "No Fault" ;
VAL_ 804 bms_w009_contactorPosMainLSFlt 1 "Fault" 0 "No Fault" ;
VAL_ 804 bms_f009_contactorPosMainLSFlt 1 "Fault" 0 "No Fault" ;
VAL_ 804 bms_w010_contactorNegMainHSFlt 1 "Fault" 0 "No Fault" ;
VAL_ 804 bms_f010_contactorNegMainHSFlt 1 "Fault" 0 "No Fault" ;
VAL_ 804 bms_w011_contactorNegMainLSFlt 1 "Fault" 0 "No Fault" ;
VAL_ 804 bms_f011_contactorNegMainLSFlt 1 "Fault" 0 "No Fault" ;
VAL_ 804 bms_w012_contactorPrechgHSFault 1 "Fault" 0 "No Fault" ;
VAL_ 804 bms_f012_contactorPrechgHSFault 1 "Fault" 0 "No Fault" ;
VAL_ 804 bms_w013_contactorPrechgLSFault 1 "Fault" 0 "No Fault" ;
VAL_ 804 bms_f013_contactorPrechgLSFault 1 "Fault" 0 "No Fault" ;
VAL_ 804 bms_w014_acChargingRelayFault 1 "Fault" 0 "No Fault" ;
VAL_ 804 bms_f014_acChargingRelayFault 1 "Fault" 0 "No Fault" ;
VAL_ 804 bms_w015_dcChargingRelayFault 1 "Fault" 0 "No Fault" ;
VAL_ 804 bms_f015_dcChargingRelayFault 1 "Fault" 0 "No Fault" ;
VAL_ 804 bms_w016_currentSensorFailure 1 "Fault" 0 "No Fault" ;
VAL_ 804 bms_f016_currentSensorFailure 1 "Fault" 0 "No Fault" ;
VAL_ 804 bms_w017_cellImbalanceDischrg 1 "Fault" 0 "No Fault" ;
VAL_ 804 bms_f017_cellImbalanceDischrg 1 "Fault" 0 "No Fault" ;
VAL_ 804 bms_w018_prechargeFailure 1 "Fault" 0 "No Fault" ;
VAL_ 804 bms_f018_prechargeFailure 1 "Fault" 0 "No Fault" ;
VAL_ 804 bms_w019_bmuCommFailure 1 "Fault" 0 "No Fault" ;
VAL_ 804 bms_f019_bmuCommFailure 1 "Fault" 0 "No Fault" ;
VAL_ 804 bms_w020_isolationFault 1 "Fault" 0 "No Fault" ;
VAL_ 804 bms_f020_isolationFault 1 "Fault" 0 "No Fault" ;
VAL_ 804 bms_w021_coolantInletOverTemp 1 "Fault" 0 "No Fault" ;
VAL_ 804 bms_f021_coolantInletOverTemp 1 "Fault" 0 "No Fault" ;
VAL_ 804 bms_w022_coolantOutletOverTemp 1 "Fault" 0 "No Fault" ;
VAL_ 804 bms_f022_coolantOutletOverTemp 1 "Fault" 0 "No Fault" ;
VAL_ 804 bms_w023_prechargeTimeout 1 "Fault" 0 "No Fault" ;
VAL_ 804 bms_f023_prechargeTimeout 1 "Fault" 0 "No Fault" ;
VAL_ 804 bms_w024_powerDeratingSoc 1 "Fault" 0 "No Fault" ;
VAL_ 804 bms_f024_powerDeratingSoc 1 "Fault" 0 "No Fault" ;
VAL_ 804 bms_w025_noPowerDeliverySoc 1 "Fault" 0 "No Fault" ;
VAL_ 804 bms_f025_noPowerDeliverySoc 1 "Fault" 0 "No Fault" ;
VAL_ 804 bms_w026_dcLSContactorFail 1 "Fault" 0 "No Fault" ;
VAL_ 804 bms_f026_dcLSContactorFail 1 "Fault" 0 "No Fault" ;
VAL_ 804 bms_w027_hvilOpen 1 "Fault" 0 "No Fault" ;
VAL_ 804 bms_f027_hvilOpen 1 "Fault" 0 "No Fault" ;
VAL_ 804 bms_w028_lostCommsVCU 1 "Fault" 0 "No Fault" ;
VAL_ 804 bms_f028_lostCommsVCU 1 "Fault" 0 "No Fault" ;
VAL_ 804 bms_w029_lostCommsOBC 1 "Fault" 0 "No Fault" ;
VAL_ 804 bms_f029_lostCommsOBC 1 "Fault" 0 "No Fault" ;
VAL_ 804 bms_w030_batteryProtectionSoc 1 "Fault" 0 "No Fault" ;
VAL_ 804 bms_f030_batteryProtectionSoc 1 "Fault" 0 "No Fault" ;
VAL_ 804 bms_w031_cellTempImbalDischrg 1 "Fault" 0 "No Fault" ;
VAL_ 804 bms_f031_cellTempImbalDischrg 1 "Fault" 0 "No Fault" ;
VAL_ 816 vcu_Rev_VcuV2VModeFb 2 "FAULT" 1 "ENABLE" 0 "DISABLE" ;
VAL_ 816 vcu_v2vChrgAllow 1 "Allow" 0 "Inhibit" ;
VAL_ 816 vcu_StartRevSOC 63 "Invalid" ;
VAL_ 817 vcu_Rev_BmstempInletCoolant 4095 "Invalid" ;
VAL_ 817 vcu_Rev_BmstempOutletCoolant 4095 "Invalid" ;
VAL_ 817 vcu_stEgyFlowGenMotAndBatt 2 "BMS to Generator motor" 1 "Generator motor to Battery" 0 "Neutral" ;
VAL_ 817 vcu_stEgyFlowEngAndGenMot 2 "Geneator motor to engine" 1 "Engine to Generator motor" 0 "Neutral" ;
VAL_ 817 vcu_dcPrehtChrgRlyAlwOpn 1 "Allow" 0 "Inhibit" ;
VAL_ 817 vcu_obcDschrgAllow 1 "Allow" 0 "Inhibit" ;
VAL_ 817 vcu_v2vChrgFdbk 1 "ON" 0 "OFF" ;
VAL_ 817 vcu_obcDschrgFdbk 1 "ON" 0 "OFF" ;
VAL_ 817 vcu_v2vChrgOutCurntFdbk 9 "100" 8 "90" 7 "80" 6 "70" 5 "60" 4 "50" 3 "40" 2 "30" 1 "20" 0 "0" ;
VAL_ 817 VCU_MaxFuelConsumptionSt 1 "ON" 0 "OFF" ;
VAL_ 817 VCU_MaxFuelConsumptionModeSt 1 "Low Speed" 0 "High Speed" ;
VAL_ 817 vcu_RangeExtenderNoSt 1 "Request" 0 "No_request" ;
VAL_ 820 bms_w056_ivtsOverTemp 1 "fault" 0 "NO_fault" ;
VAL_ 820 bms_f056_ivtsOverTemp 1 "fault" 0 "NO_fault" ;
VAL_ 820 bms_w059_vcuStateMsgMia 1 "fault" 0 "NO_fault" ;
VAL_ 820 bms_f059_vcuStateMsgMia 1 "fault" 0 "NO_fault" ;
VAL_ 820 bms_w060_ribbonBondBroken 1 "fault" 0 "NO_fault" ;
VAL_ 820 bms_f060_ribbonBondBroken 1 "fault" 0 "NO_fault" ;
VAL_ 820 bms_w061_crashDetected 1 "fault" 0 "NO_fault" ;
VAL_ 820 bms_f061_crashDetected 1 "fault" 0 "NO_fault" ;
VAL_ 820 bms_w062_vcuVehicleMsgMia 1 "fault" 0 "NO_fault" ;
VAL_ 820 bms_f062_vcuVehicleMsgMia 1 "fault" 0 "NO_fault" ;
VAL_ 841 mrr_obj0_dx 255 "Invalid" ;
VAL_ 841 mrr_obj1_dx 255 "Invalid" ;
VAL_ 841 mrr_obj0_Vx 511 "Invalid" ;
VAL_ 841 mrr_obj1_Vx 511 "Invalid" ;
VAL_ 841 mrr_obj0_TargetType 3 "No Object" 2 "reserve" 1 "TRUCK" 0 "SEDAN" ;
VAL_ 841 mrr_obj0_wExist 7 "invalid" 6 "[90:100]" 5 "[80:90)" 4 "[70:80)" 3 "[60:70)" 2 "[50:60)" 1 "[0:50)" 0 "defult" ;
VAL_ 841 mrr_obj1_wExist 7 "invalid" 6 "[90:100]" 5 "[80:90)" 4 "[70:80)" 3 "[60:70)" 2 "[50:60)" 1 "[0:50)" 0 "defult" ;
VAL_ 841 mrr_obj1_TargetType 3 "No Object" 2 "reserve" 1 "TRUCK" 0 "SEDAN" ;
VAL_ 858 mpc_las_roadCurvature 127 "Invalid" ;
VAL_ 858 mpc_las_LLaneDistance 63 "Invalid" ;
VAL_ 858 mpc_las_RLaneDistance 63 "Invalid" ;
VAL_ 858 mpc_las_LLaneMarkerType 7 "INVALID" 6 "RESERVED" 5 "OTHER" 4 "BOTTS' DOTS" 3 "DOUBLELAND_MARK" 2 "ROAD_EDGE" 1 "SOLID" 0 "DASHED" ;
VAL_ 858 mpc_las_RLaneMarkerType 7 "INVALID" 6 "RESERVED" 5 "OTHER" 4 "BOTTS' DOTS" 3 "DOUBLELAND_MARK" 2 "ROAD_EDGE" 1 "SOLID" 0 "DASHED" ;
VAL_ 858 mpc_textinfor 7 "Reserved" 6 "TJA error" 5 "TJA degradted to ACC" 4 "TJA active" 3 "TJA exited" 2 "Reserved" 1 "TJA Switched Off" 0 "NO INDICATION" ;
VAL_ 858 mpc_LL_Line_Curvature 127 "Invalid" ;
VAL_ 858 mpc_RR_Line_Curvature 127 "Invalid" ;
VAL_ 858 mpc_LL_LaneMarkerType 7 "INVALID" 6 "RESERVED" 5 "OTHER" 4 "BOTTS' DOTS" 3 "DOUBLELAND_MARK" 2 "ROAD_EDGE" 1 "SOLID" 0 "DASHED" ;
VAL_ 858 mpc_RR_LaneMarkerType 7 "INVALID" 6 "RESERVED" 5 "OTHER" 4 "BOTTS' DOTS" 3 "DOUBLELAND_MARK" 2 "ROAD_EDGE" 1 "SOLID" 0 "DASHED" ;
VAL_ 862 obc_acVoltageInput 0 "Invalid" ;
VAL_ 862 obc_acCurrentInput 0 "Invalid" ;
VAL_ 862 obc_0x487_timeoutFlag 1 "Timeout" 0 "Normal" ;
VAL_ 862 bms_0x354_timeoutFlag 1 "Timeout" 0 "Normal" ;
VAL_ 862 bms_v2vChrgConnection 1 "Connected" 0 "Disconnect" ;
VAL_ 873 mrr_obj2_dx 255 "Invalid" ;
VAL_ 873 mrr_obj3_dx 255 "Invalid" ;
VAL_ 873 mrr_obj2_Vx 511 "Invalid" ;
VAL_ 873 mrr_obj3_Vx 511 "Invalid" ;
VAL_ 873 mrr_obj2_TargetType 3 "No Object" 2 "reserve" 1 "TRUCK" 0 "SEDAN" ;
VAL_ 873 mrr_obj2_wExist 7 "invalid" 6 "[90:100]" 5 "[80:90)" 4 "[70:80)" 3 "[60:70)" 2 "[50:60)" 1 "[0:50)" 0 "defult" ;
VAL_ 873 mrr_obj3_wExist 7 "invalid" 6 "[90:100]" 5 "[80:90)" 4 "[70:80)" 3 "[60:70)" 2 "[50:60)" 1 "[0:50)" 0 "defult" ;
VAL_ 873 mrr_obj3_TargetType 3 "No Object" 2 "reserve" 1 "TRUCK" 0 "SEDAN" ;
VAL_ 878 eps_0x124_timeoutFlag 1 "Timeout" 0 "Normal" ;
VAL_ 878 iB_0x2A5_timeoutFlag 1 "Timeout" 0 "Normal" ;
VAL_ 878 eps_warningLamp 1 "FAULT" 0 "NORMAL" ;
VAL_ 878 eps_modeSts 3 "INVALID" 2 "SPORT" 1 "COMFORT" 0 "Reserved" ;
VAL_ 878 iB_hmiWarningOn 3 "NOT_AVAILABLE" 2 "RED" 1 "YELLOW" 0 "NO_REQUEST" ;
VAL_ 878 iB_hmiWarningOn_Q 2 "FAULTY" 1 "NORMAL" 0 "NOT_INITIALIZED" ;
VAL_ 878 iB_modeSts 1 "SPORT" 0 "COMFORT" ;
VAL_ 894 gcu_torqueEst 16383 "Invalid" ;
VAL_ 894 ecu_engSpeed 8191 "Invalid" ;
VAL_ 894 gcu_0x10C_timeoutFlag 1 "Timeout" 0 "Normal" ;
VAL_ 894 ecu_0x30B_timeoutFlag 1 "Timeout" 0 "Normal" ;
VAL_ 894 ecu_0x31B_timeoutFlag 1 "Timeout" 0 "Normal" ;
VAL_ 894 ecu_engCoolantTemp 255 "Invalid" ;
VAL_ 894 ecu_fuelConsump100ms 4095 "Invalid" ;
VAL_ 894 ecu_milIndicator 3 "INVALID" 2 "ON" 1 "Reserved" 0 "OFF" ;
VAL_ 894 vcu_coolantLevelLow 1 "FAULT" 0 "NORMAL" ;
VAL_ 894 vcu_0x531_timeoutFlag 1 "Timeout" 0 "Normal" ;
VAL_ 894 ecu_state 7 "None" 6 "AUTOSTOPPING" 5 "FINISH" 4 "STOPPING" 3 "RUNNING" 2 "CRANKING" 1 "READY" 0 "STANDBY" ;
VAL_ 894 ecu_engStartSuccess 1 "SUCCESS" 0 "FAIL" ;
VAL_ 894 ecu_engSpdErr 1 "ERROR" 0 "NO_ERROR" ;
VAL_ 894 ecu_0x39B_timeoutFlag 1 "Timeout" 0 "Normal" ;
VAL_ 896 acu_warningLampSts 2 "FLASH" 1 "ON" 0 "OFF" ;
VAL_ 896 acu_crashOutputStsValid 1 "VALID" 0 "INVALID" ;
VAL_ 896 acu_crashOutputSts 1 "CRASH" 0 "NO_CRASH" ;
VAL_ 896 acu_driverSeatBeltSts 1 "TIED" 0 "UNTIED" ;
VAL_ 896 acu_driverSeatBeltStsValid 1 "VALID" 0 "INVALID" ;
VAL_ 896 acu_passengerSeatBeltSts 1 "TIED" 0 "UNTIED" ;
VAL_ 896 acu_passengerSeatBeltStsValid 1 "VALID" 0 "INVALID" ;
VAL_ 896 acu_passengerAirbagSts 3 "RESERVED" 2 "CLOSED" 1 "NOT_CLOSE" 0 "RESERVED" ;
VAL_ 896 acu_secondLeftSeatBeltSts 1 "TIED" 0 "UNTIED" ;
VAL_ 896 acu_secondMiddleSeatBeltSts 1 "TIED" 0 "UNTIED" ;
VAL_ 896 acu_secondRightSeatBeltSts 1 "TIED" 0 "UNTIED" ;
VAL_ 896 acu_passengerSts 1 "OCCUPIED" 0 "UNOCCUPIED" ;
VAL_ 896 acu_secondLeftSts 1 "OCCUPIED" 0 "UNOCCUPIED" ;
VAL_ 896 acu_secondMiddleSts 1 "OCCUPIED" 0 "UNOCCUPIED" ;
VAL_ 896 acu_secondRightSts 1 "OCCUPIED" 0 "UNOCCUPIED" ;
VAL_ 903 obc_hardwareFaultSts 3 "RESERVED2" 2 "RESERVED1" 1 "FAULT" 0 "NORMAL" ;
VAL_ 903 obc_lockMotorSts 3 "LOCKED" 2 "FAULT_STATUS2" 1 "FAULT_STATUS1" 0 "UNLOCK" ;
VAL_ 903 obc_errorFlag 15 "FAULT_HADWARE" 14 "FAULT_OUT_OV" 13 "FAULT_OUT_UV" 12 "FAULT_INV_OVER_POWER" 11 "FAULT_PFC_ERR" 10 "FAULT_DC_ERR" 9 "FAULT_ST_CP" 8 "FAULT_ST_CC" 7 "FAULT_IN_OV" 6 "FAULT_IN_UV" 5 "FAULT_COMM_OUT" 4 "FAULT_OUT_OC" 3 "FAULT_OTP_ALL" 2 "FAULT_OTP_RT" 1 "FAULT_MUTEX" 0 "NO_FAULT" ;
VAL_ 903 obc_state 15 "RESERVED3" 14 "RESERVED2" 13 "RESERVED1" 12 "BATT_WARM" 11 "V2X" 10 "SLEEP" 9 "FAULT" 8 "RECOVERY_FAULT" 7 "END_OF_CHARGE" 6 "CHARGE_PAUSE" 5 "CHARGE_CV" 4 "CHARGE_CC" 3 "DC_CHARGE_STANDBY" 2 "AC_CHARGE_STANDBY" 1 "HANDSHAKE" 0 "INIT" ;
VAL_ 903 obc_s2Sts 1 "CONNECTED" 0 "NOT_CONNECTED" ;
VAL_ 903 obc_batteryConnectSts 1 "CONNECTED" 0 "NOT_CONNECTED" ;
VAL_ 903 obc_ccOhm 9 "2000Ohm" 8 "RESERVED2" 7 "RESERVED1" 6 "100OHM" 5 "220OHM" 4 "680OHM" 3 "1500OHM" 2 "HALFCONNECT" 1 "UNCONNECT" 0 "CC_SHORT_GROUND" ;
VAL_ 903 obc_chargeSts 1 "CHARGING" 0 "UNCHARGING" ;
VAL_ 903 obc_slowChargeRelaySts 2 "FAULT" 1 "CLOSE" 0 "OPEN" ;
VAL_ 903 obc_fastChargeRelayHSts 2 "FAULT" 1 "CLOSE" 0 "OPEN" ;
VAL_ 903 obc_fastChargeRelayLSts 2 "FAULT" 1 "CLOSE" 0 "OPEN" ;
VAL_ 903 obc_chargerEndChargeReq 1 "AC_CHARGE_ENABLE" 0 "AC_CHARGE_END" ;
VAL_ 909 dcdc_hardwareFaultSts 3 "FAULT" 0 "NORMAL" ;
VAL_ 909 dcdc_errorFlag 15 "RESERVED" 14 "SELFTESTFALL(LOCK)DCDC self test failed" 13 "FAULT_OUT_OC(LOCK)DCDC  output current greater than 215A" 12 "FAULT_IN_OC(LOCK)DCDC  input current  greater than 15A" 11 "FAULT_OUT_OV(LOCK)DCDC output voltage  greater than 16V" 10 "FAULT_OUT_UV(LOCK)DCDC output voltage less than 9V" 9 "Reserved" 8 "Reserved" 7 "Reserved" 6 "FAULT_IN_OV(REC)DCDC input voltage  greater than 450" 5 "FAULT_IN_UV(REC)DCDC input voltage less than 240" 4 "FAULT_COM_OUT(REC)Loss of communication between DCDC and VCU" 3 "RESERVED" 2 "FAULT_OTP_ALL(REC)DC temperature higher than 85 ℃" 1 "FAULT_UTP_ALL(REC)DC temperature below -40℃" 0 "NO_FAULT" ;
VAL_ 909 dcdc_systemSts 7 "DCDC_LOCK_FAULT_STATE" 6 "DCDC_RECV_FAULT_STATE" 5 "DCDC_SLEEP_STATE" 4 "DCDC308_RES1" 3 "DCDC308_RES0" 2 "DCDC_WORK_STATE" 1 "DCDC_STANDBY_STATE" 0 "DCDC_INIT_STATE" ;
VAL_ 909 dcdc_deratingSts 1 "DERATING" 0 "NORMAL" ;
VAL_ 909 dcdc_alerState 3 "Level3" 2 "Level2" 1 "Level1" 0 "No error" ;
VAL_ 909 dcdc_overTemperature 3 "Level3" 2 "Level2" 1 "Level1" 0 "No error" ;
VAL_ 916 pot_CatchSWSts 1 "ON" 0 "OFF" ;
VAL_ 916 pot_PawlSWSts 1 "ON" 0 "OFF" ;
VAL_ 916 pot_tailgateOpenFailWarning 1 "WARNING" 0 "NO_WARNING" ;
VAL_ 916 pot_tailgateCloseFailWarning 1 "WARNING" 0 "NO_WARNING" ;
VAL_ 916 pot_tailgateOpenSts 7 "Reserved" 6 "Latch cinching" 5 "Latch releasing" 4 "PLG stopped" 3 "Closing" 2 "Opening" 1 "Fully closed" 0 "Fully opened" ;
VAL_ 916 pot_doorMemoryPosEnb 1 "Success" 0 "No request" ;
VAL_ 916 pot_antiPlayWarning 1 "WARNING" 0 "NO_WARNING" ;
VAL_ 916 pot_tailgateCloseSwSts 3 "Stuck" 2 "Long Press" 1 "Press" 0 "Release" ;
VAL_ 916 pot_workingSts 3 "Reserved" 2 "Abnormality" 1 "Normal" 0 "Initializing" ;
VAL_ 916 pot_OpenTurnIndicator 7 "Warning" 6 "MemoryPositionFault" 5 "ForceStop" 4 "Anti-PinchReverse" 3 "UserOperationDenid" 2 "MemoryPosition" 1 "UserOperationAcception" 0 "Off" ;
VAL_ 916 pot_NeutralSWSts 1 "ON" 0 "OFF" ;
VAL_ 916 pot_MotorOverTempProtection 1 "Protecting mode" 0 "Normal mode" ;
VAL_ 916 pot_delayClosingPotReq 1 "Active" 0 "No Request" ;
VAL_ 918 ac_ambientTemp 255 "Invalid" ;
VAL_ 918 ac_cabinTemp 255 "Invalid" ;
VAL_ 918 ac_EvapActualTemp 255 "Invalid" ;
VAL_ 918 ac_HighPresCoolantTemp 255 "Invalid" ;
VAL_ 918 ac_LowPresCoolantTemp 255 "Invalid" ;
VAL_ 918 ac_LowPressure 127 "Invalid" ;
VAL_ 918 ac_ambientTempValid 1 "VALID" 0 "INVALID" ;
VAL_ 918 ac_cabinPtcPower 127 "Invalid" ;
VAL_ 929 vcu_driveMode 7 "Reserved" 6 "Reserved" 5 "Reserved" 4 "Reserved" 3 "Offroad" 2 "SPORT" 1 "COMFORT" 0 "ECO" ;
VAL_ 929 vcu_towMode 1 "ON" 0 "OFF" ;
VAL_ 929 VCU_EscReady 3 "invalid" 2 "ready" 1 "failure" 0 "Not_ready" ;
VAL_ 929 vcu_ready 1 "READY" 0 "NOT_READY" ;
VAL_ 929 vcu_highVoltageSuccess 7 "RESERVE_HIGHVOLT3" 6 "RESERVE_HIGHVOLT2" 5 "RESERVE_HIGHVOLT1" 4 "FAILURE_AND_LOW_VOLT" 3 "HIGH_VOLT_UPING" 2 "HIGH_VOLT_DOWNING" 1 "HIGH_VOLT_UP" 0 "LOW_VOLT" ;
VAL_ 929 vcu_epbReq 2 "RELEASE" 1 "APPLY" 0 "NO_COMMAND" ;
VAL_ 929 vcu_hvOnMode 3 "INVALID" 2 "REMOTE" 1 "LOCAL" 0 "OFF" ;
VAL_ 929 vcu_4wdModeSts 3 "Reserved" 2 "AWD" 1 "RWD" 0 "FWD" ;
VAL_ 929 vcu_RegenModeSts 3 "Strong Recovery" 2 "NORMAL" 1 "LOW" 0 "OFF" ;
VAL_ 929 vcu_enableCreepTorqueSts 1 "ON" 0 "OFF" ;
VAL_ 929 vcu_memorySts 1 "Memory" 0 "No_Memory" ;
VAL_ 929 vcu_torqueDistMode 3 "INVALID" 2 "SPORT" 1 "AUTO" 0 "Defult" ;
VAL_ 932 BMS_ThrmlRunawaySt 3 "预留" 2 "热失控故障" 1 "正常" 0 "无效" ;
VAL_ 932 BMS_3wayValveSt 1 "打开" 0 "关闭" ;
VAL_ 932 BMS_ThrmlRunawayDiagSt 4 "诊断方案4" 3 "诊断方案3" 2 "诊断方案2" 1 "诊断方案1" 0 "无诊断" ;
VAL_ 932 BMS_ASDensity 65535 "Invalid" ;
VAL_ 942 mcur0_speed 262143 "Invalid" ;
VAL_ 942 mcur0_iBus 16383 "Invalid" ;
VAL_ 942 mcur0_vBus 16383 "Invalid" ;
VAL_ 942 mcur0_faultLevel 3 "LEVEL3" 2 "LEVEL2" 1 "LEVEL1" 0 "LEVEL0（NO fault）" ;
VAL_ 942 mcur0_stEgyFlowAndBatt 2 "BATTERY_TO_Rear_MOTOR" 1 "Rear_MOTOR_TO_BATTERY" 0 "NEUTRAL" ;
VAL_ 942 mcur0_state 10 "OFF" 9 "ACTIVE_DISCHARGE" 8 "IDLE" 7 "AUTO_RETRY" 6 "HARD_FAULT" 5 "GPO" 4 "TURTLE" 3 "ENABLE" 2 "STANDBY" 1 "SOPT" 0 "INIT" ;
VAL_ 942 mcur0_0x112_timeoutFlag 1 "Timeout" 0 "Normal" ;
VAL_ 942 mcur0_0x312_timeoutFlag 1 "Timeout" 0 "Normal" ;
VAL_ 950 ac_systemOnOffSts 1 "ON" 0 "OFF" ;
VAL_ 950 ac_autoSts 1 "ON" 0 "OFF" ;
VAL_ 950 ac_acSts 1 "ON" 0 "OFF" ;
VAL_ 950 ac_driverTempC 30 "HI" 0 "low" ;
VAL_ 950 ac_dualSts 1 "DUAL" 0 "SINGLE" ;
VAL_ 950 ac_frontDefrostSts 1 "ON" 0 "OFF" ;
VAL_ 950 ac_passengerTempC 30 "HI" 0 "low" ;
VAL_ 950 ac_recircSts 3 "Reserved" 2 "Auto" 1 "INTERNAL" 0 "EXTERNAL" ;
VAL_ 950 ac_modeSts 7 "INVALID" 4 "DEFROST" 3 "FOOT_AND_DEFROST" 2 "FOOT" 1 "FACE_AND_FOOT" 0 "FACE" ;
VAL_ 950 ac_blowerLvSts 7 "SPEED_7" 6 "SPEED_6" 5 "SPEED_5" 4 "SPEED_4" 3 "SPEED_3" 2 "SPEED_2" 1 "SPEED_1" 0 "OFF" ;
VAL_ 950 ac_diagInfo 17 "OUT_OF_CAN_NETWORK" 16 "NETWORK_BREAK_WITH_AQS" 15 "NETWORK_BREAK_WITH_PTC" 14 "MIXR_STEPPER_BROKE" 13 "MIXL_STEPPER_BROKE" 12 "MODE_STEPPER_BROKE" 11 "REC_STEPPER_BROKE" 10 "BLOWER_BROKE" 9 "RIGHT_FACE_SENSOR_BROKE" 8 "RIGHT_FOOT_SENSOR_BROKE" 7 "LEFT_FACE_SENSOR_BROKE" 6 "LEFT_FOOT_SENSOR_BROKE" 5 "INCAR_SENSOR_BROKE" 4 "AMB_SENSOR_BROKE" 3 "LOW_PT_SENSOR_BROKE" 2 "HIGH_PT_SENSOR_BROKE" 1 "EVAP_SENSOR_BROKE" 0 "NORMAL" ;
VAL_ 950 ac_cabinPtcSts 1 "ON" 0 "OFF" ;
VAL_ 950 ac_rearDefrostReq 1 "Pressed" 0 "No Press" ;
VAL_ 950 AC_FreshAirModeRsp 1 "On" 0 "Off" ;
VAL_ 950 AC_VentilationCoolRsp 1 "On" 0 "Off" ;
VAL_ 958 mcuf0_speed 262143 "Invalid" ;
VAL_ 958 mcuf0_iBus 16383 "Invalid" ;
VAL_ 958 mcuf0_vBus 16383 "Invalid" ;
VAL_ 958 mcuf0_faultLevel 3 "LEVEL3" 2 "LEVEL2" 1 "LEVEL1" 0 "LEVEL0（NO fault）" ;
VAL_ 958 mcuf0_stEgyFlowAndBatt 2 "BATTERY_TO_FRONT_MOTOR" 1 "FRONT_MOTOR_TO_BATTERY" 0 "NEUTRAL" ;
VAL_ 958 mcuf0_state 10 "OFF" 9 "ACTIVE_DISCHARGE" 8 "IDLE" 7 "AUTO_RETRY" 6 "HARD_FAULT" 5 "GPO" 4 "TURTLE" 3 "ENABLE" 2 "STANDBY" 1 "SOPT" 0 "INIT" ;
VAL_ 958 mcuf0_0x113_timeoutFlag 1 "Timeout" 0 "Normal" ;
VAL_ 958 mcuf0_0x313_timeoutFlag 1 "Timeout" 0 "Normal" ;
VAL_ 961 bcm_rearMirrorSts 1 "UNFOLD" 0 "FOLD" ;
VAL_ 961 bcm_DRLSts 1 "On" 0 "Off" ;
VAL_ 961 bcm_sunroofSts 7 "UNINITIALIZED" 6 "FULLY_OPEN" 5 "PARTIALLY_SLIDE" 4 "ANTIPINCH_IN_PARTIALLY_SLIDE" 3 "FULLY_CLOSE" 2 "ANTIPINCH_IN_VENT" 1 "VENT_AREA" 0 "TILT_UP" ;
VAL_ 961 bcm_sunshadeSts 7 "Uninitialized" 6 "Fully open" 5 "Reversed" 4 "Half open" 3 "Fully close" 2 "Second half of slide" 1 "First half of slide" 0 "Reserved" ;
VAL_ 961 bcm_windowLFSts 7 "Pinch Reversing" 6 "Manual Down moving" 5 "Auto Down moving" 4 "Manual Up moving" 3 "Auto Up moving" 2 "Window closed" 1 "Window opened" 0 "stopped" ;
VAL_ 961 bcm_windowRFSts 7 "Pinch Reversing" 6 "Manual Down moving" 5 "Auto Down moving" 4 "Manual Up moving" 3 "Auto Up moving" 2 "Window closed" 1 "Window opened" 0 "stopped" ;
VAL_ 961 bcm_leftBsdLedSts 1 "ON" 0 "OFF" ;
VAL_ 961 bcm_rightBsdLedSts 1 "ON" 0 "OFF" ;
VAL_ 961 bcm_windowLRSts 7 "Pinch Reversing" 6 "Manual Down moving" 5 "Auto Down moving" 4 "Manual Up moving" 3 "Auto Up moving" 2 "Window closed" 1 "Window opened" 0 "stopped" ;
VAL_ 961 bcm_windowRRSts 7 "Pinch Reversing" 6 "Manual Down moving" 5 "Auto Down moving" 4 "Manual Up moving" 3 "Auto Up moving" 2 "Window closed" 1 "Window opened" 0 "stopped" ;
VAL_ 961 bcm_rearDefrostSts 1 "ON" 0 "OFF" ;
VAL_ 961 bcm_delayClosingPotReq 1 "Close" 0 "NoInput" ;
VAL_ 961 bcm_rkeTailgateCtrlCmd 3 "The back door button is pressed longer than 2S" 2 "In 2 seconds, the back door button is pressed for 2 times in a row" 1 "The back door button is pressed once" 0 "NO_ACTION" ;
VAL_ 961 bcm_rainSensorError 1 "FAULT" 0 "NORMAL" ;
VAL_ 961 bcm_GlassUncloseWarning 1 "Warning" 0 "No warning" ;
VAL_ 961 bcm_posLampSts 1 "ON" 0 "OFF" ;
VAL_ 961 bcm_autoLampSwSts 1 "AUTO" 0 "NON_AUTO" ;
VAL_ 961 bcm_rsmSolarRight 255 "Invalid" ;
VAL_ 961 bcm_rsmSolarLeft 255 "Invalid" ;
VAL_ 961 bcm_lowBeamSts 1 "ON" 0 "OFF" ;
VAL_ 961 bcm_highBeamSts 1 "ON" 0 "OFF" ;
VAL_ 961 bcm_kickActiveReq 1 "KICK_MOVEMENT_DETECTED" 0 "NO_ACTIVATION_DETECTED" ;
VAL_ 961 bcm_rlsSensitivity 7 "Invalid" 6 "Sensitivity 7" 5 "Sensitivity 6" 4 "Sensitivity 5" 3 "Sensitivity 4" 2 "Sensitivity 3" 1 "Sensitivity 2" 0 "Sensitivity 1" ;
VAL_ 961 bcm_rearFogLampSts 1 "ON" 0 "OFF" ;
VAL_ 961 bcm_lightSensorError 1 "FAULT" 0 "NORMAL" ;
VAL_ 961 bcm_remoteForbidden 3 "Reserved" 2 "Forbidden" 1 "Pending" 0 "NoForbidden" ;
VAL_ 961 BCM_rlsWindowCloseReq 1 "Request" 0 "No Request" ;
VAL_ 962 BCM_volOrSOCLowAlarm 3 "INVALID" 2 "Normal" 1 "LOW" 0 "INACTIVE" ;
VAL_ 962 bcm_centerCtrlPotOnOffSet 3 "Reserved" 2 "OPEN" 1 "CLOSE" 0 "NORequest" ;
VAL_ 962 bcm_RLReadLightSts 1 "ON" 0 "OFF" ;
VAL_ 962 bcm_RRReadLightSts 1 "ON" 0 "OFF" ;
VAL_ 962 bcm_welcomeRsp 15 "Reserved" 14 "Reserved" 13 "Reserved" 12 "Reserved" 11 "Mode10" 10 "Mode9" 9 "Mode8" 8 "Mode7" 7 "Mode6" 6 "Mode5" 5 "Mode4" 4 "Mode3" 3 "Mode2" 2 "Mode1" 1 "OFF" 0 "Default" ;
VAL_ 962 bcm_antiTheftAlarmFormSts 3 "Reserved" 2 "Reserved" 1 "Vision+Voice" 0 "Only Vision" ;
VAL_ 962 bcm_lockAutoCloseWinFdb 3 "INVALID" 2 "INACTIVE" 1 "ACTIVE" 0 "RESERVED" ;
VAL_ 962 bcm_screenAutoLiftFdb 3 "INVALID" 2 "INACTIVE" 1 "ACTIVE" 0 "RESERVED" ;
VAL_ 962 bcm_backlightadjust 15 "Invalid" 14 "Reserved" 13 "Reserved" 12 "Reserved" 11 "Reserved" 10 "Level 10" 9 "Level 9" 8 "Level 8" 7 "Level 7" 6 "Level 6" 5 "Level 5" 4 "Level 4" 3 "Level 3" 2 "Level 2" 1 "Level 1" 0 "Off" ;
VAL_ 962 bcm_DGSWSts 3 "INVALID" 2 "CLOSE" 1 "OPEN" 0 "NO COMMOND" ;
VAL_ 962 bcm_DGPercentSts 31 "INVALID" 11 "36" 10 "15.5" 9 "13" 8 "11.9" 7 "11.4" 6 "10.6" 5 "10.3" 4 "9.6" 3 "8.8" 2 "7.5" 1 "0" 0 "NO_Req" ;
VAL_ 962 bcm_apmCmd_2U 3 "Windows stop(停止遥控升降窗动作)" 2 "Window Down" 1 "Window Up" 0 "Default" ;
VAL_ 962 bcm_hazardSwitchReq 3 "Invalid" 2 "Reserved" 1 "Pressed" 0 "No Press" ;
VAL_ 962 bcm_welcomeOnOffSetFeedback 15 "Reserved" 14 "Reserved" 13 "Reserved" 12 "Reserved" 11 "Mode10" 10 "Mode9" 9 "Mode8" 8 "Mode7" 7 "Mode6" 6 "Mode5" 5 "Mode4" 4 "Mode3" 3 "Mode2" 2 "Mode1" 1 "OFF" 0 "Default" ;
VAL_ 962 bcm_keyInPotRemind 1 "Warning" 0 "No Warning" ;
VAL_ 977 bcm_rsm_windowTemp 2047 "Invalid" ;
VAL_ 977 bcm_rsm_dewPointTemp 2047 "Invalid" ;
VAL_ 977 bcm_rsm_relHumidity 255 "Invalid" ;
VAL_ 977 bcm_rsm_FwBrightness 2047 "Invalid" ;
VAL_ 977 bcm_rsm_IRBrightness 255 "Invalid" ;
VAL_ 978 BCM_FLWindowHorizontalSts 127 "Invalid" ;
VAL_ 978 BCM_FRWindowHorizontalSts 127 "Invalid" ;
VAL_ 978 BCM_RLWindowHorizontalSts 127 "Invalid" ;
VAL_ 978 BCM_RRWindowHorizontalSts 127 "Invalid" ;
VAL_ 978 bcm_srm_srMovement 7 "reserved" 6 "moving uninitialized" 5 "reversing (AP/Stall)" 4 "closing slide" 3 "opening slide" 2 "closing tilt" 1 "opening tilt" 0 "stopped" ;
VAL_ 978 bcm_ssm_ssMovement 7 "reserved" 6 "moving uninitialized" 5 "reversing (AP/Stall)" 4 "closing slide" 3 "opening slide" 2 "closing tilt" 1 "opening tilt" 0 "stopped" ;
VAL_ 981 dscu_drSeatMassSts 7 "ERROR" 6 "RESERVED" 5 "LEVEL_5" 4 "LEVEL_4" 3 "LEVEL_3" 2 "LEVEL_2" 1 "LEVEL_1" 0 "OFF" ;
VAL_ 981 dscu_passSeatMassSts 7 "ERROR" 6 "RESERVED" 5 "LEVEL_5" 4 "LEVEL_4" 3 "LEVEL_3" 2 "LEVEL_2" 1 "LEVEL_1" 0 "OFF" ;
VAL_ 981 dscu_easyEntrySts 1 "Enable" 0 "Disable" ;
VAL_ 981 dscu_MirrorAutoTurnDownSts 1 "Enable" 0 "Disable" ;
VAL_ 981 dscu_DrMassgIntenSt 3 "High Intensity" 2 "Normal Intensity" 1 "Weak Intensity" 0 "OFF" ;
VAL_ 981 dscu_PsgMassgIntenSt 3 "High Intensity" 2 "Normal Intensity" 1 "Weak Intensity" 0 "OFF" ;
VAL_ 981 dscu_MemoryPos 7 "RESERVED" 6 "Memory failed" 5 "5 POSITION" 4 "4 POSITION" 3 "3 POSITION" 2 "2 POSITION" 1 "1 POSITION" 0 "NOT_MEMORYPOSITION" ;
VAL_ 981 dscu_leftMirrorSw 1 "Press" 0 "No Press" ;
VAL_ 981 dscu_rightMirrorSw 1 "Press" 0 "No Press" ;
VAL_ 981 dscu_dsmGetMemoryReq 7 "Reserved" 6 "Get failed" 5 "5 POSITION" 4 "4 POSITION" 3 "3 POSITION" 2 "2 POSITION" 1 "1 POSITION" 0 "NOT_MEMORYPOSITION" ;
VAL_ 981 dscu_Init 1 "Success" 0 "Not Init" ;
VAL_ 981 dscu_fsvh_passSeatHeatSts 7 "ERROR" 3 "LEVEL_3" 2 "LEVEL_2" 1 "LEVEL_1" 0 "OFF" ;
VAL_ 981 dscu_fsvh_passSeatVentSts 7 "ERROR" 3 "LEVEL_3" 2 "LEVEL_2" 1 "LEVEL_1" 0 "OFF" ;
VAL_ 981 dscu_fsvh_drSeatHeatSts 7 "ERROR" 3 "LEVEL_3" 2 "LEVEL_2" 1 "LEVEL_1" 0 "OFF" ;
VAL_ 981 dscu_fsvh_drSeatVentSts 7 "ERROR" 3 "LEVEL_3" 2 "LEVEL_2" 1 "LEVEL_1" 0 "OFF" ;
VAL_ 981 dscu_faceIDAccntGetSeatPosFb 3 "Reserved" 2 "Failed" 1 "Success" 0 "Invalid" ;
VAL_ 982 dscu_dsSeatBackPos 255 "Invalid" ;
VAL_ 982 dscu_dsSeatSlidePos 255 "Invalid" ;
VAL_ 982 dscu_dsSeatHeightPos 255 "Invalid" ;
VAL_ 982 dscu_dsSeatCushionAnglePos 255 "Invalid" ;
VAL_ 982 dscu_leftMirrorVerticalPos 255 "Invalid" ;
VAL_ 982 dscu_leftMirrorHorizontalPos 255 "Invalid" ;
VAL_ 982 dscu_rightMirrorVerticalPos 255 "Invalid" ;
VAL_ 982 dscu_rightMirrorHorizontalPos 255 "Invalid" ;
VAL_ 255 OBC_AcChgEnergy 2047 "Invalid" ;
VAL_ 1041 bcm_tpmsLFSts 3 "SENSOR_ERROR" 2 "SYS_ERROR" 1 "NORMAL_TPMS" 0 "INITIAL_TPMS" ;
VAL_ 1041 bcm_tpmsRFSts 3 "SENSOR_ERROR" 2 "SYS_ERROR" 1 "NORMAL_TPMS" 0 "INITIAL_TPMS" ;
VAL_ 1041 bcm_PressureWarningLF 3 "RESERVED" 2 "HIGH_TYRE_PRESSURE" 1 "LOW_TYRE_PRESSURE" 0 "NO WARNING" ;
VAL_ 1041 bcm_PressureWarningRF 3 "RESERVED" 2 "HIGH_TYRE_PRESSURE" 1 "LOW_TYRE_PRESSURE" 0 "NO WARNING" ;
VAL_ 1041 bcm_TireTempWarningLF 1 "WARNING" 0 "NO WARNING" ;
VAL_ 1041 bcm_TireTempWarningRF 1 "WARNING" 0 "NO WARNING" ;
VAL_ 1041 bcm_tpmsLFLOW_BATT_Warning 1 "WARNING" 0 "NO WARNING" ;
VAL_ 1041 bcm_tpmsRFLOW_BATT_Warning 1 "WARNING" 0 "NO WARNING" ;
VAL_ 1041 bcm_tpmsLFRAPID_LEAK_Warning 1 "WARNING" 0 "NO WARNING" ;
VAL_ 1041 bcm_tpmsRFRAPID_LEAK_Warning 1 "WARNING" 0 "NO WARNING" ;
VAL_ 1041 bcm_tyreLFPressure 255 "Invalid" ;
VAL_ 1041 bcm_tyreLFTemp 255 "Invalid" ;
VAL_ 1041 bcm_tyreRFPressure 255 "Invalid" ;
VAL_ 1041 bcm_tyreRFTemp 255 "Invalid" ;
VAL_ 1057 bcm_tpmsLRSts 3 "SENSOR_ERROR" 2 "SYS_ERROR" 1 "NORMAL_TPMS" 0 "INITIAL_TPMS" ;
VAL_ 1057 bcm_tpmsRRSts 3 "SENSOR_ERROR" 2 "SYS_ERROR" 1 "NORMAL_TPMS" 0 "INITIAL_TPMS" ;
VAL_ 1057 bcm_PressureWarningLR 3 "RESERVED" 2 "HIGH_TYRE_PRESSURE" 1 "LOW_TYRE_PRESSURE" 0 "NO WARNING" ;
VAL_ 1057 bcm_PressureWarningRR 3 "RESERVED" 2 "HIGH_TYRE_PRESSURE" 1 "LOW_TYRE_PRESSURE" 0 "NO WARNING" ;
VAL_ 1057 bcm_TireTempWarningLR 1 "WARNING" 0 "NO WARNING" ;
VAL_ 1057 bcm_TireTempWarningRR 1 "WARNING" 0 "NO WARNING" ;
VAL_ 1057 bcm_tpmsLRLOW_BATT_Warning 1 "WARNING" 0 "NO WARNING" ;
VAL_ 1057 bcm_tpmsRRLOW_BATT_Warning 1 "WARNING" 0 "NO WARNING" ;
VAL_ 1057 bcm_tpmsLRRAPID_LEAK_Warning 1 "WARNING" 0 "NO WARNING" ;
VAL_ 1057 bcm_tpmsRRRAPID_LEAK_Warning 1 "WARNING" 0 "NO WARNING" ;
VAL_ 1057 bcm_tyreLRPressure 255 "Invalid" ;
VAL_ 1057 bcm_tyreLRTemp 255 "Invalid" ;
VAL_ 1057 bcm_tyreRRPressure 255 "Invalid" ;
VAL_ 1057 bcm_tyreRRTemp 255 "Invalid" ;
VAL_ 1073 bcm_rllmStopLampFault 1 "fault" 0 "good" ;
VAL_ 1073 bcm_rllmLeftTurnLampFault 1 "fault" 0 "good" ;
VAL_ 1073 bcm_rllmFogLampFault 1 "fault" 0 "good" ;
VAL_ 1073 bcm_rllmReverseLampFault 1 "fault" 0 "good" ;
VAL_ 1073 bcm_rllmPositionLampFault 1 "fault" 0 "good" ;
VAL_ 1073 bcm_rmlmStopLampFault 1 "fault" 0 "good" ;
VAL_ 1073 bcm_rmlmLeftTurnLampFault 1 "fault" 0 "good" ;
VAL_ 1073 bcm_rmlmRightTurnLampFault 1 "fault" 0 "good" ;
VAL_ 1073 bcm_rmlmPositionLampFault 1 "fault" 0 "good" ;
VAL_ 1073 bcm_rrlmStopLampFault 1 "fault" 0 "good" ;
VAL_ 1073 bcm_rrlmRightTurnLampFault 1 "fault" 0 "good" ;
VAL_ 1073 bcm_rrlmFogLampFault 1 "fault" 0 "good" ;
VAL_ 1073 bcm_rrlmReverseLampFault 1 "fault" 0 "good" ;
VAL_ 1073 bcm_rrlmPositionLampFault 1 "fault" 0 "good" ;
VAL_ 1073 bcm_rmlmHighStopLampFault 1 "fault" 0 "good" ;
VAL_ 1089 vcu_brakeLight 1 "ON" 0 "OFF" ;
VAL_ 1089 vcu_alertLevel 7 "NONE_4" 6 "NONE_3" 5 "NONE_2" 4 "NONE_1" 3 "HARD_FAULT" 2 "GPO" 1 "TURTLE" 0 "NORMAL" ;
VAL_ 1089 vcu_driveReady 1 "TRUE" 0 "FALSE" ;
VAL_ 1089 vcu_hvState 3 "HIGH_VOLT_UPING" 2 "HIGH_VOLT_DOWNING" 1 "HIGH_VOLT_UP" 0 "HIGH_VOLT_DOWN" ;
VAL_ 1089 vcu_highVoltFail 3 "INVALID" 2 "RESERVED" 1 "FAIL" 0 "NOT_FAIL" ;
VAL_ 1089 vcu_regenmode 1 "ON" 0 "OFF" ;
VAL_ 1089 vcu_drivePowerAllowed 1023 "Invalid" 0 "Init" ;
VAL_ 1089 vcu_gearSwitchFail 1 "FAIL" 0 "NOT_FAIL" ;
VAL_ 1089 vcu_refuelReq 1 "Request" 0 "No request" ;
VAL_ 1089 vcu_drivePowerAcutal 1023 "Invalid" 0 "Init" ;
VAL_ 1089 vcu_evModeDisplay 3 "Reserve" 2 "REV Mode" 1 "EV Mode" 0 "Init" ;
VAL_ 1089 VCU_VehicleSpeedValid 1 "Invalid" 0 "Valid" ;
VAL_ 1089 vcu_RmtEngStartReq 1 "Request" 0 "No Request" ;
VAL_ 1089 vcu_ExhibitionSts 3 "Reserved" 2 "Exhibition" 1 "Normal" 0 "Invalid" ;
VAL_ 1089 vcu_remoteVehicleForbiddenStart 3 "INVALID" 2 "Forbidden Start" 1 "Start" 0 "INACTIVE" ;
VAL_ 1274 gw_vin_frame 7 "Reserved" 6 "Reserved" 5 "Reserved" 4 "Reserved" 3 "Third Frame" 2 "Second Frame" 1 "First Frame" 0 "Default" ;
VAL_ 1275 GW_Mode 7 "Invalid" 6 "Reserved" 5 "Reserved" 4 "Reserved" 3 "Reserved" 2 "INFOCAN disable" 1 "DCAN disable" 0 "Default" ;
VAL_ 1297 vcu_mcuf0OverTemperature 1 "Fault" 0 "Normal" ;
VAL_ 1297 vcu_mcur0OverTemperature 1 "Fault" 0 "Normal" ;
VAL_ 1297 vcu_mcuf0MotorOverTemperature 1 "Fault" 0 "Normal" ;
VAL_ 1297 vcu_mcur0MotorOverTemperature 1 "Fault" 0 "Normal" ;
VAL_ 1298 mcur0_workMode 3 "STANDBY" 2 "SHUTDOWN" 1 "GENERATOR_MODE" 0 "MOTOR_MODE" ;
VAL_ 1298 mcur0_OverTemperature 3 "Level3" 2 "Level2" 1 "Level1" 0 "No error" ;
VAL_ 1298 mcur0_MotorOverTemperature 3 "Level3" 2 "Level2" 1 "Level1" 0 "No error" ;
VAL_ 1299 mcuf0_workMode 3 "STANDBY" 2 "SHUTDOWN" 1 "GENERATOR_MODE" 0 "MOTOR_MODE" ;
VAL_ 1299 mcuf0_OverTemperature 3 "Level3" 2 "Level2" 1 "Level1" 0 "No error" ;
VAL_ 1299 mcuf0_MotorOverTemperature 3 "Level3" 2 "Level2" 1 "Level1" 0 "No error" ;
VAL_ 1300 bms_remainChargeTime 255 "Invalid" ;
VAL_ 1300 bms_batteryConditionFail 1 "FAILED" 0 "NORMAL" ;
VAL_ 1300 bms_BatteryConditionSts 1 "ENABLE" 0 "DISABLE" ;
VAL_ 1300 bms_stEgyFlowSysDischRgn 3 "Reserved" 2 "BATTERY_DISCHARGE" 1 "BATTERY_CHARGE" 0 "NEUTRAL" ;
VAL_ 1300 bms_stEgyFlowOBCAndBatt 3 "Reserved" 2 "BATTERY_TO_OBC" 1 "OBC_TO_BATTERY" 0 "NEUTRAL" ;
VAL_ 1300 bms_chargeFormSts 7 "Reserved" 6 "INVALID_CHRGFORM" 5 "RESERVE_CHRGFORM4" 4 "RESERVE_CHRGFORM3" 3 "RESERVE_CHRGFORM2" 2 "RESERVE_CHRGFORM1" 1 "TIMING_CHARGE" 0 "IMMEDIATE_CHARGE" ;
VAL_ 1377 vcu_PwrSincelastcharge 16383 "Invalid" ;
VAL_ 1377 vcu_PwroftripA 16383 "Invalid" ;
VAL_ 1396 bms_vehicleChargingSts 7 "Reserved" 6 "Reserved" 5 "CHARGE_ABNORMAL" 4 "CHARGE_COMPLETE" 3 "NOT_CHARGING" 2 "CHARGING_IN_DRIVE" 1 "CHARGING_IN_PARK" 0 "INVALID" ;
VAL_ 254 bms_DcChgEnergy 2047 "Invalid" ;
VAL_ 1566 GW_INFO_RMR 1 "Repeat Message State requested" 0 "Repeat Message State not requested" ;
VAL_ 1566 GW_INFO_AWB 1 "Node has woken up the network (active Wakeup)" 0 "Node has not woken up the network (passive wakeup)" ;
